VERSION ""

NS_ :

BS_:

BU_: SafetyRestraintSystem2 BrakeStrokeAlertMonitorTractor RearDoorStatusUnit SteeringColumnUnit BodyController ForwardRoadImageProcessor BrakesTrailer5 BrakesTrailer4 WeighingSystemDisplay Door6StatusUnit Door5StatusUnit Door4StatusUnit FuelTankMonitor PassengerCounterUnit3 PassengerCounterUnit2 IdleAdjustSystem EntryAssistControl2 EntryAssistControl1 EngineOilControlSystem InstrumentCluster2 IntersectionPreemptionEmitter SafetyRestraintSystem CommUnitCellular WeightingSystemAxleGroup6 WeightingSystemAxleGroup5 WeightingSystemAxleGroup4 WeightingSystemAxleGroup3 WeightingSystemAxleGroup2 WeightingSystemAxleGroup1 ParkingHeater TransmissiionShiftConsolePrimary DrivelineRetarder DriverInformationCenter2 Tachograph CollisionAvoidanceSystems Bridge_TrailerMounted Bridge_TractorMounted LightingControlAdministratorUnit SurveillanceMircrophone SilentAlarmUnit VehicleControlHeadTouchScreen MobileDataTerminal SmartCardTerminal BusChassisIdentificationUnit VehicleTurntable MaintenancePrinter BridgeFromDrivetrainLink BaseUnit VehicleProximityLeftSide VehicleProximityRightSide MobileDataTerminalUnit HighSpeedCommUnit VehicleStatusPointsMonitorUnit RouteAdherenceUnit EnvMonitorUnit ScheduleAdherenceUnit PassengerCounterUnit1 FareCollectionUnit AnnunciatorUnit MiddleDoorStatusUnit FrontDoorStatusUnit VehicleLocationUnit RefrigerantManagement VehicleHeadSigns VehicleLogicControlUnit VehicleControlHeadUnit TiresControlUnit PneumaticSystemController RearAxleSteeringController Engine3 OffBoardProgrammingStation CommUnitSatellite OffBoardDiagnostics2 DataLoggingComputer VehicleSensorsToDataConverter ParticulateTrapSystem TransmAddHybridCtrlModule Engine2 CrankingSystem EngineRetarder OffBoardDiagnostics1 DriverInformationCenter Electrical TiresTrailer3 TiresTrailer2 TiresTrailer1 TiresPowerUnit CommonUnitGround Multiplex VehicleSecurity VehicleNavigationUnit AerodynamicControlUnit ProximityDetectorRear ProximityDetectorFront ElectricalChargingSystem ParkBrakeController DiagSysTrailer2_obsolete DiagSysTrailer1 DiagSysPowerUnit SuspensionTrailer3_obsolete SuspensionTrailer2_obsolete SuspensionTrailer1 SuspensionPowerUnit CargoHeatingTrailer3_obsolete CargoHeatingTrailer2_obsolete CargoHeatingTrailer CabClimateControl RoadSpeedIndicator CruiseControl FuelSystem VehicleManagementSystem TripRecorder AxleTrailer2_obsolete BrakesTrailer3 BrakesTrailer2 BrakesTrailer1 BrakePowerUnit AxleTrailer3_obsolete AxleTrailer1 AxlePowerUnit PowerTakeoff InstrumentCluster Transmission TurboCharger Engine1
VAL_TABLE_ VtSitg_RqTempClutchDisengage 3 "NotAvailable" 2 "Error" 1 "ClutchDisengegementRequested" 0 "NoRequest" ;
VAL_TABLE_ VTSig_Lamp 3 "NotAvailable" 2 "Error" 1 "On" 0 "Off" ;
VAL_TABLE_ VTSig_Active 1 "Active" 0 "not Active" ;
VAL_TABLE_ VTSig_OnOff 3 "NotAvailable" 2 "Error" 1 "On" 0 "Off" ;

BO_ 510 Page2DataLinkEscape: 2 Vector__XXX
 SG_ VarLengthAndTypeData : 8|8@1+ (1,0) [0|255] "" Vector__XXX
 SG_ MID : 0|8@1+ (1,0) [0|255] "" Vector__XXX

BO_ 509 MilepostIdentification: 1 Vector__XXX
 SG_ VarNrASCIIChars : 0|8@1+ (1,0) [0|255] "ASCII" Vector__XXX

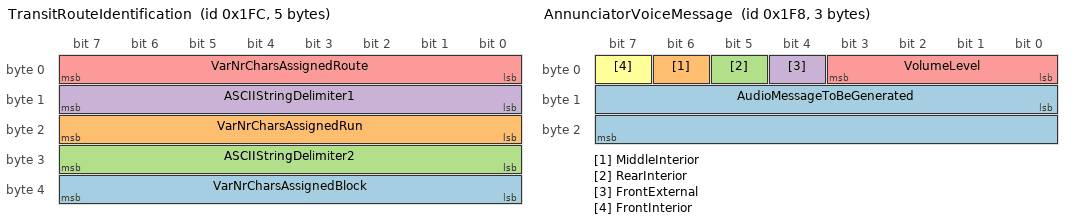
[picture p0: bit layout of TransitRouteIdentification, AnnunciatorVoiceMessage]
BO_ 508 TransitRouteIdentification: 5 Vector__XXX
 SG_ VarNrCharsAssignedBlock : 32|8@1+ (1,0) [0|255] "ASCII" Vector__XXX
 SG_ VarNrCharsAssignedRun : 16|8@1+ (1,0) [0|255] "ASCII" Vector__XXX
 SG_ ASCIIStringDelimiter2 : 24|8@1+ (1,0) [0|255] "ASCII" Vector__XXX
 SG_ ASCIIStringDelimiter1 : 8|8@1+ (1,0) [0|255] "ASCII" Vector__XXX
 SG_ VarNrCharsAssignedRoute : 0|8@1+ (1,0) [0|255] "ASCII" Vector__XXX

BO_ 507 DriverIdentification: 3 Vector__XXX
 SG_ VarNrCharsOtherDriverData : 16|8@1+ (1,0) [0|255] "ASCII" Vector__XXX
 SG_ ASCIIStringDelimiter1 : 8|8@1+ (1,0) [0|255] "ASCII" Vector__XXX
 SG_ VarNrCharsDriverId : 0|8@1+ (1,0) [0|255] "ASCII" Vector__XXX

BO_ 506 VehicleControlHeadDisplayMessage: 3 Vector__XXX
 SG_ VarNrASCIIChars : 16|8@1+ (1,0) [0|255] "ASCII" Vector__XXX
 SG_ SegmentPosForDisplayOfASCIIChars : 8|8@1+ (1,0) [0|255] "ASCII" Vector__XXX
 SG_ LinePosForDisplayOfASCIIChars : 0|8@1+ (1,0) [0|255] "ASCII" Vector__XXX

BO_ 505 VehicleCtrlHeadKeyboardMessage: 2 Vector__XXX
 SG_ IBMScanCode : 8|8@1+ (1,0) [0|255] "" Vector__XXX
 SG_ FunctionKeyDepression : 0|8@1+ (1,0) [0|255] "" Vector__XXX

BO_ 504 AnnunciatorVoiceMessage: 3 Vector__XXX
 SG_ AudioMessageToBeGenerated : 8|16@1+ (1,0) [0|65535] "" Vector__XXX
 SG_ MiddleInterior : 6|1@1+ (1,0) [0|1] "" Vector__XXX
 SG_ RearInterior : 5|1@1+ (1,0) [0|1] "" Vector__XXX
 SG_ FrontExternal : 4|1@1+ (1,0) [0|1] "" Vector__XXX
 SG_ VolumeLevel : 0|4@1+ (1,0) [0|15] "" Vector__XXX
 SG_ FrontInterior : 7|1@1+ (1,0) [0|1] "" Vector__XXX

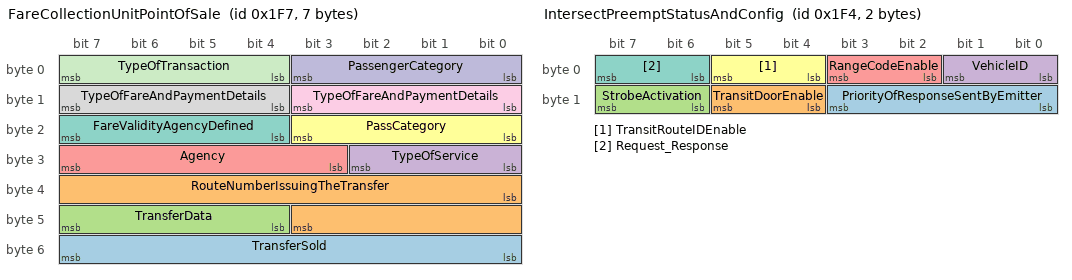
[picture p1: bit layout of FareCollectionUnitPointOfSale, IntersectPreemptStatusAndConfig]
BO_ 503 FareCollectionUnitPointOfSale: 7 Vector__XXX
 SG_ TransferSold : 48|8@1+ (1,0) [0|255] "" Vector__XXX
 SG_ RouteNumberIssuingTheTransfer : 32|12@1+ (1,0) [0|4095] "" Vector__XXX
 SG_ TransferData : 44|4@1+ (1,0) [0|15] "" Vector__XXX
 SG_ TypeOfService : 24|3@1+ (1,0) [0|7] "" Vector__XXX
 SG_ Agency : 27|5@1+ (1,0) [1|31] "" Vector__XXX
 SG_ PassCategory : 16|4@1+ (1,0) [0|15] "" Vector__XXX
 SG_ FareValidityAgencyDefined : 20|4@1+ (1,0) [0|15] "" Vector__XXX
 SG_ TypeOfFareAndPaymentDetails : 12|4@1+ (1,0) [0|15] "" Vector__XXX
 SG_ TypeOfFareAndPaymentDetails : 8|4@1+ (1,0) [0|15] "" Vector__XXX
 SG_ PassengerCategory : 0|4@1+ (1,0) [0|15] "" Vector__XXX
 SG_ TypeOfTransaction : 4|4@1+ (1,0) [0|15] "" Vector__XXX

BO_ 502 FareCollectionUnitServiceDetail: 14 Vector__XXX
 SG_ DriversSecurityCode : 96|16@1+ (1,0) [0|65535] "" Vector__XXX
 SG_ AssignedBlock : 80|16@1+ (1,0) [0|65535] "" Vector__XXX
 SG_ AssignedRun : 64|16@1+ (1,0) [0|65535] "" Vector__XXX
 SG_ AssignedRoute : 48|16@1+ (1,0) [0|65535] "" Vector__XXX
 SG_ PatternNumber : 32|16@1+ (1,0) [0|65535] "" Vector__XXX
 SG_ TripNumber : 16|16@1+ (1,0) [0|65535] "" Vector__XXX
 SG_ FarePresets : 8|8@1+ (1,0) [0|255] "" Vector__XXX
 SG_ TripStatus : 0|4@1+ (1,0) [0|15] "" Vector__XXX
 SG_ TripStatus : 4|3@1+ (1,0) [0|7] "" Vector__XXX
 SG_ FareboxStatus : 7|1@1+ (1,0) [0|1] "" Vector__XXX

BO_ 501 SignageMessage: 2 Vector__XXX
 SG_ DataCharacter1 : 8|8@1+ (1,0) [0|255] "" Vector__XXX
 SG_ RecordType : 0|8@1+ (1,0) [0|255] "ASCII" Vector__XXX

BO_ 500 IntersectPreemptStatusAndConfig: 2 Vector__XXX
 SG_ PriorityOfResponseSentByEmitter : 8|4@1+ (1,0) [0|15] "" Vector__XXX
 SG_ TransitDoorEnable : 12|2@1+ (1,0) [0|3] "" Vector__XXX
 SG_ StrobeActivation : 14|2@1+ (1,0) [0|3] "" Vector__XXX
 SG_ VehicleID : 0|2@1+ (1,0) [0|3] "" Vector__XXX
 SG_ RangeCodeEnable : 2|2@1+ (1,0) [0|3] "" Vector__XXX
 SG_ TransitRouteIDEnable : 4|2@1- (1,0) [0|3] "" Vector__XXX
 SG_ Request_Response : 6|2@1- (1,0) [0|3] "" Vector__XXX

BO_ 499 DriverInterfaceUnitDIUObjFormCmd: 5 Vector__XXX
 SG_ DataCharacter1 : 32|8@1+ (1,0) [0|255] "" Vector__XXX
 SG_ OID : 16|16@1+ (1,0) [0|65535] "" Vector__XXX
 SG_ FID : 8|8@1- (1,0) [0|255] "" Vector__XXX
 SG_ CommandType : 0|8@1+ (1,0) [0|255] "" Vector__XXX

BO_ 498 SendKeypressCommand: 3 Vector__XXX
 SG_ VarNrASCIIChars : 16|8@1+ (1,0) [0|255] "ASCII" Vector__XXX
 SG_ FID : 8|8@1- (1,0) [0|255] "" Vector__XXX
 SG_ MID : 0|8@1+ (1,0) [0|255] "" Vector__XXX

BO_ 450 BridgeFilterControl: 3 Vector__XXX
 SG_ TransmissionUpdatePeriod : 16|8@1+ (0.2,0) [0|51] "s" Vector__XXX
 SG_ PID : 8|8@1+ (1,0) [0|255] "" Vector__XXX
 SG_ MID : 0|8@1+ (1,0) [0|255] "" Vector__XXX

BO_ 449 ReportingIntervalRequest: 3 Vector__XXX
 SG_ TransmissionUpdatePeriod : 16|8@1+ (1,0) [0|255] "s" Vector__XXX
 SG_ PIDPage2 : 8|8@1+ (1,0) [0|255] "" Vector__XXX
 SG_ MID : 0|8@1+ (1,0) [0|255] "" Vector__XXX

BO_ 448 Page2MultisectionParameter: 3 Vector__XXX
 SG_ VarLengthDataSectionedParam : 24|8@1+ (1,0) [0|255] "" Vector__XXX
 SG_ ByteCountOrDataSectionedParam : 16|8@1+ (1,0) [0|255] "" Vector__XXX
 SG_ LastAndCurrentSectionNumber : 8|8@1+ (1,0) [0|255] "" Vector__XXX
 SG_ PIDPage2 : 0|8@1+ (1,0) [0|255] "" Vector__XXX

BO_ 447 PassengerCounter: 2 Vector__XXX
 SG_ PatronCount : 8|8@1+ (1,0) [0|255] "" Vector__XXX
 SG_ TypeOfPassengerCount : 0|8@1+ (1,0) [0|255] "" Vector__XXX

BO_ 446 CylHeadTemperatureBankB_Left: 2 Vector__XXX
 SG_ CylHeadTemperatureBankB_Left : 0|16@1- (0.25,0) [-8192|8191.75] "°F" Vector__XXX

BO_ 445 CylHeadTemperatureBankB_Right: 2 Vector__XXX
 SG_ CylHeadTemperatureBankB_Right : 0|16@1- (0.25,0) [-8192|8191.75] "°F" Vector__XXX

BO_ 444 Battery2Potential: 2 Vector__XXX
 SG_ Battery2Potential : 0|16@1+ (0.05,0) [0|3276.75] "V" Vector__XXX

BO_ 443 AuxiliaryGagePressureReading2: 2 Vector__XXX
 SG_ AuxiliaryGagePressureReading2 : 0|16@1+ (0.689,0) [0|45153.6] "kPa" Vector__XXX

BO_ 442 AuxiliaryTemperature2: 2 Vector__XXX
 SG_ AuxiliaryTemperature2 : 0|16@1- (0.1,0) [-3276.8|3276.7] "°F" Vector__XXX

BO_ 441 AuxiliaryTemperature1: 2 Vector__XXX
 SG_ AuxiliaryTemperature1 : 0|16@1- (0.1,0) [-3276.8|3276.7] "°F" Vector__XXX

BO_ 440 ExtendedRangeBoostPressure2: 2 Vector__XXX
 SG_ ExtendedRangeBoostPressure2 : 0|16@1+ (0.125,0) [0|8191.875] "kPa" Vector__XXX

BO_ 439 ExtendedRangeBoostPressure1: 2 Vector__XXX
 SG_ ExtendedRangeBoostPressure1 : 0|16@1+ (0.125,0) [0|8191.875] "kPa" Vector__XXX

BO_ 438 Trailer2Tag2PushChn2TirePressure: 2 Vector__XXX
 SG_ Trailer2Tag2PushChn2TirePressure : 0|16@1+ (0.689,0) [0|45153.6] "kPa" Vector__XXX

BO_ 437 Trail2Tag2PushChn2TirePrssreTarg: 2 Vector__XXX
 SG_ Trail2Tag2PushChn2TirePrssreTarg : 0|16@1+ (0.689,0) [0|45153.6] "kPa" Vector__XXX

BO_ 436 TripSuddenDecelerations: 2 Vector__XXX
 SG_ TripSuddenDecelerations : 0|16@1+ (1,0) [0|65535] "" Vector__XXX

BO_ 435 CargoAmbientTemperatreByLocation: 2 Vector__XXX
 SG_ CargoAmbientTemperature : 8|8@1- (1,0) [-127|128] "°F" Vector__XXX
 SG_ LocationOfTheAirTemperature : 0|2@1+ (1,0) [0|3] "" Vector__XXX

BO_ 434 ACVoltage: 2 Vector__XXX
 SG_ ACVoltage : 0|16@1+ (0.125,0) [0|8191.875] "V" Vector__XXX

BO_ 433 FuelShutoffSolenoidVoltage: 2 Vector__XXX
 SG_ FuelShutoffSolenoidVoltage : 0|16@1+ (0.05,0) [0|3276.75] "V" Vector__XXX

BO_ 432 StarterMotorVoltage: 2 Vector__XXX
 SG_ StarterMotorVoltage : 0|16@1+ (0.05,0) [0|3276.75] "V" Vector__XXX

BO_ 431 StarterNegativeCableVoltage: 2 Vector__XXX
 SG_ StarterNegativeCableVoltage : 0|16@1+ (0.0001,0) [0|6.5535] "V" Vector__XXX

BO_ 430 StarterSolenoidVoltage: 2 Vector__XXX
 SG_ StarterSolenoidVoltage : 0|16@1+ (0.05,0) [0|3276.75] "V" Vector__XXX

BO_ 429 StarterCurrentPeak: 2 Vector__XXX
 SG_ StarterCurrentPeak : 0|16@1+ (0.125,0) [0|8191.875] "A" Vector__XXX

BO_ 428 BatteryInternalResistance: 2 Vector__XXX
 SG_ BatteryInternalResistance : 0|16@1+ (0.25,0) [0|16383.75] "mOhm" Vector__XXX

BO_ 427 BatteryResistanceChange: 2 Vector__XXX
 SG_ BatteryResistanceChange : 0|16@1+ (0.25,0) [0|16383.75] "mOhm/s" Vector__XXX

BO_ 426 AlternatorGeneratorFieldVoltage: 2 Vector__XXX
 SG_ AlternatorGeneratorFieldVoltage : 0|16@1+ (0.05,0) [0|3276.75] "V" Vector__XXX

BO_ 425 AuxiliaryFrequency: 2 Vector__XXX
 SG_ AuxiliaryFrequency : 0|16@1+ (0.1,0) [0|6553.5] "Hz" Vector__XXX

BO_ 424 DCVoltage: 2 Vector__XXX
 SG_ DCVoltage : 0|16@1+ (0.05,0) [0|3276.75] "V" Vector__XXX

BO_ 423 ExtendedRangeNetBatteryCurrent: 2 Vector__XXX
 SG_ ExtendedRangeNetBatteryCurrent : 0|16@1- (0.125,0) [-4095.875|4096] "A" Vector__XXX

BO_ 422 AuxiliaryCurrent: 2 Vector__XXX
 SG_ AuxiliaryCurrent : 0|16@1- (0.125,0) [-4095.875|4096] "A" Vector__XXX

BO_ 421 AltrnatorGenratorNegCableVoltage: 2 Vector__XXX
 SG_ AltrnatorGenratorNegCableVoltage : 0|16@1+ (0.0001,0) [0|6.5535] "V" Vector__XXX

BO_ 420 StarterCurrentAverage: 2 Vector__XXX
 SG_ StarterCurrentAverage : 0|16@1+ (0.125,0) [0|8191.875] "A" Vector__XXX

BO_ 419 StarterCircuitResistance: 2 Vector__XXX
 SG_ StarterCircuitResistance : 0|16@1+ (0.25,0) [0|16383.75] "mOhm" Vector__XXX

BO_ 418 Transmission2OilTemperature: 2 Vector__XXX
 SG_ Transmission2OilTemperature : 0|16@1+ (0.25,0) [-8192|8191.75] "°F" Vector__XXX

BO_ 417 GrossVehicleWeight: 2 Vector__XXX
 SG_ GrossVehicleWeight : 0|16@1+ (17.792,0) [0|1166056.9] "N" Vector__XXX

BO_ 416 EvaporatorTemperature: 2 Vector__XXX
 SG_ EvaporatorTemperature : 0|16@1- (0.25,0) [-8192|8191.75] "°F" Vector__XXX

BO_ 415 AirCondRfrgerntHighSidePressure: 2 Vector__XXX
 SG_ AirCondRfrgerntHighSidePressure : 0|16@1- (1.379,0) [-45185|45184] "kPa" Vector__XXX

BO_ 414 AirCondRfrgerntLowSidePressure: 2 Vector__XXX
 SG_ AirCondRfrgerntLowSidePressure : 0|16@1- (1.379,0) [-45185|45184] "kPa" Vector__XXX

BO_ 413 NetVehicleWeightChange: 2 Vector__XXX
 SG_ NetVehicleWeightChange : 0|16@1- (17.792,0) [-583020.1|583037.3] "N" Vector__XXX

BO_ 412 RecircEngExhaustGasTemperature: 2 Vector__XXX
 SG_ RecircEngExhaustGasTemperature : 0|16@1- (0.25,0) [-8192|8191.75] "°F" Vector__XXX

BO_ 411 RecircEngExhaustGasDiffPressure: 2 Vector__XXX
 SG_ RecircEngExhaustGasDiffPressure : 0|16@1- (0.0078125,0) [-250|251.99] "kPa" Vector__XXX

BO_ 410 ExtRangeRoadSurfaceTemperature: 2 Vector__XXX
 SG_ ExtRangeRoadSurfaceTemperature : 0|16@1- (0.25,0) [-8192|8191.75] "°F" Vector__XXX

BO_ 409 AxleGroupWeight: 2 Vector__XXX
 SG_ AxleGroupWeight : 0|16@1+ (17.792,0) [0|1166056.9] "N" Vector__XXX

BO_ 408 AxleGroupEmptyWeightCalibration: 2 Vector__XXX
 SG_ AxleGroupEmptyWeightCalibration : 0|16@1+ (17.792,0) [0|1166056.9] "N" Vector__XXX

BO_ 407 AxleGroupFullWeightCalibration: 2 Vector__XXX
 SG_ AxleGroupFullWeightCalibration : 0|16@1+ (17.792,0) [0|1166056.9] "N" Vector__XXX

BO_ 406 HVACBlowerMotorSpeed: 2 Vector__XXX
 SG_ HVACBlowerMotorSpeed : 0|16@1+ (0.25,0) [0|16383.75] "rpm" Vector__XXX

BO_ 384 CompnentSpecificRequestParameter: 2 Vector__XXX
 SG_ IDFullParam : 0|8@1+ (1,0) [0|255] "" Vector__XXX
 SG_ MID : 8|8@1+ (1,0) [0|255] "" Vector__XXX

BO_ 383 VehicleAcceleration: 1 Vector__XXX
 SG_ VehicleAcceleration : 0|8@1- (0.322,0) [-41.216|40.894] "km/h/s" Vector__XXX

BO_ 382 TransitSilentAlarmStatus: 1 Vector__XXX
 SG_ SilentAlarmStatus : 0|2@1+ (1,0) [0|3] "" Vector__XXX

BO_ 381 VehicleUseStatus: 1 Vector__XXX
 SG_ TransitRunStatus : 8|2@1+ (1,0) [0|3] "" Vector__XXX
 SG_ VehicleUseStatus : 0|2@1+ (1,0) [0|3] "" Vector__XXX

BO_ 380 ArticulationAngle: 1 Vector__XXX
 SG_ ArticulationAngle : 0|8@1- (1,0) [-128|127] "°" Vector__XXX

BO_ 379 DoorStatus: 1 Vector__XXX
 SG_ TransitDoorStatus : 0|2@1+ (1,0) [0|3] "" Vector__XXX
 SG_ TrailerCargoDoorStatus : 2|2@1+ (1,0) [0|3] "" Vector__XXX

BO_ 378 FareCollectionUnitStatus: 1 Vector__XXX
 SG_ FareCollectionUnitStatus : 7|1@1+ (1,0) [0|1] "" Vector__XXX
 SG_ AlarmIdentifier : 0|7@1+ (1,0) [0|127] "" Vector__XXX

BO_ 377 CompressionUnbalance: 1 Vector__XXX
 SG_ CompressionUnbalance : 0|8@1+ (0.5,0) [0|127.5] "%" Vector__XXX

BO_ 376 FuelPumpInletVacuum: 1 Vector__XXX
 SG_ FuelPumpInletVacuum : 0|8@1+ (0.2,0) [0|51] "Hg" Vector__XXX

BO_ 375 FuelReturnPressure: 1 Vector__XXX
 SG_ FuelReturnPressure : 0|8@1+ (0.5,0) [0|127.5] "psi" Vector__XXX

BO_ 374 AlternatorACVoltage: 1 Vector__XXX
 SG_ AlternatorACVoltage : 0|8@1+ (0.125,0) [0|31.875] "V" Vector__XXX

BO_ 373 CenterRearDriveAxleTemperature: 1 Vector__XXX
 SG_ CenterRearDriveAxleTemperature : 0|8@1+ (1.2,0) [0|306] "°F" Vector__XXX

BO_ 372 RemoteAccelerator: 1 Vector__XXX
 SG_ RemoteAccelerator : 0|8@1+ (0.4,0) [0|102] "%" Vector__XXX

BO_ 371 TrailerPneumSupplyLinePressure: 1 Vector__XXX
 SG_ TrailerPneumSupplyLinePressure : 0|8@1+ (4.14,0) [0|1055] "kPa" Vector__XXX

BO_ 370 TrailrPneumBrkeCtrlLinePressure: 1 Vector__XXX
 SG_ TrailrPneumBrkeCtrlLinePressure : 0|8@1- (4.14,0) [0|1055] "kPa" Vector__XXX

BO_ 369 DistanceToRearObject_Reverse: 1 Vector__XXX
 SG_ DistanceToObjFromRearOfVehicle : 0|8@1+ (0.1,0) [0|25.5] "" Vector__XXX

BO_ 368 LaneDepartureIndication: 1 Vector__XXX
 SG_ RightSideIndicationStatus : 4|2@1+ (1,0) [0|3] "" Vector__XXX
 SG_ LeftSideIndicationStatus : 6|2@1+ (1,0) [0|3] "" Vector__XXX

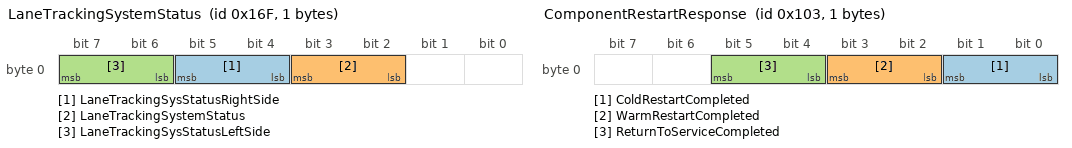
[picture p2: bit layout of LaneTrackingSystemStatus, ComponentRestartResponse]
BO_ 367 LaneTrackingSystemStatus: 1 Vector__XXX
 SG_ LaneTrackingSysStatusRightSide : 4|2@1+ (1,0) [0|3] "" Vector__XXX
 SG_ LaneTrackingSystemStatus : 2|2@1- (1,0) [0|3] "" Vector__XXX
 SG_ LaneTrackingSysStatusLeftSide : 6|2@1+ (1,0) [0|3] "" Vector__XXX

BO_ 366 EngineOilLevelHigh_Low: 1 Vector__XXX
 SG_ EngineOilLevelHigh_Low : 0|8@1- (0.473,0) [-60.544|60.071] "L" Vector__XXX

BO_ 365 WeighingSystemStatusCommand: 1 Vector__XXX
 SG_ WeighingSystemStatus2 : 0|2@1+ (1,0) [0|3] "" Vector__XXX
 SG_ WeighingSystemStatus1 : 2|2@1+ (1,0) [0|3] "" Vector__XXX

BO_ 364 HVACUnitDischargeTemperature: 1 Vector__XXX
 SG_ HVACUnitDischargeTemperature : 0|8@1- (2.5,0) [-320|317.5] "°F" Vector__XXX

BO_ 363 HydraulicRetarderCtrlAirPressure: 1 Vector__XXX
 SG_ HydraulicRetarderCtrlAirPressure : 0|8@1+ (4.14,0) [0|1055] "kPa" Vector__XXX

BO_ 362 PercentExhaustGasRecircValve2Pos: 1 Vector__XXX
 SG_ PercentExhaustGasRecircValve2Pos : 0|8@1+ (0.5,0) [0|127.5] "%" Vector__XXX

BO_ 259 ComponentRestartResponse: 1 Vector__XXX
 SG_ ColdRestartCompleted : 0|2@1+ (1,0) [0|3] "" Vector__XXX
 SG_ WarmRestartCompleted : 2|2@1+ (1,0) [0|3] "" Vector__XXX
 SG_ ReturnToServiceCompleted : 4|2@1+ (1,0) [0|3] "" Vector__XXX

BO_ 258 WarmRestartOfSpecificComponent: 1 Vector__XXX
 SG_ MID : 0|8@1+ (1,0) [0|255] "" Vector__XXX

BO_ 257 ColdRestartOfSpecificComponent: 1 Vector__XXX
 SG_ MID : 0|8@1+ (1,0) [0|255] "" Vector__XXX

BO_ 254 DataLinkEscape: 2 Vector__XXX

BO_ 253 ElapsedTime: 1 Vector__XXX
 SG_ Seconds : 0|8@1+ (0.25,0) [0|63.75] "s" Vector__XXX

BO_ 252 Date: 3 Vector__XXX
 SG_ Year : 16|8@1+ (1,0) [0|255] "y" Vector__XXX
 SG_ Month : 8|8@1+ (1,0) [0|255] "months" Vector__XXX
 SG_ Day : 0|8@1+ (0.25,0) [0|63.75] "d" Vector__XXX

BO_ 251 Clock: 3 Vector__XXX
 SG_ Hours : 16|8@1+ (1,0) [0|255] "h" Vector__XXX
 SG_ Minutes : 8|8@1+ (1,0) [0|255] "min" Vector__XXX
 SG_ Seconds : 0|8@1+ (0.25,0) [0|63.75] "s" Vector__XXX

BO_ 250 TotalFuelUsed2: 4 Vector__XXX
 SG_ TotalFuelUsed : 0|32@1+ (0.473,0) [0|2032277476] "L" Vector__XXX

BO_ 247 TotalEngineHours: 4 Vector__XXX
 SG_ TotalEngineHours : 0|32@1+ (0.05,0) [0|214748364.75] "h" Vector__XXX

BO_ 249 TotalEngineRevolutions: 4 Vector__XXX
 SG_ TotalEngineRevolutions : 0|32@1+ (1000,0) [0|4294967295000] "r" Vector__XXX

BO_ 248 TotalPTOHours: 4 Vector__XXX
 SG_ TotalPTOHours : 0|32@1+ (0.05,0) [0|214748364.75] "h" Vector__XXX

BO_ 246 TotalVehicleHours: 4 Vector__XXX
 SG_ TotalVehicleHours : 0|32@1+ (0.05,0) [0|214748364.75] "h" Vector__XXX

BO_ 245 TotalVehicleDistance: 4 Vector__XXX
 SG_ TotalVehicleDistance : 0|32@1+ (0.161,0) [0|691207984.6] "km" Vector__XXX

BO_ 244 TripDistance: 4 Vector__XXX
 SG_ TripDistance : 0|32@1+ (0.16,0) [0|687194767.2] "km" Vector__XXX

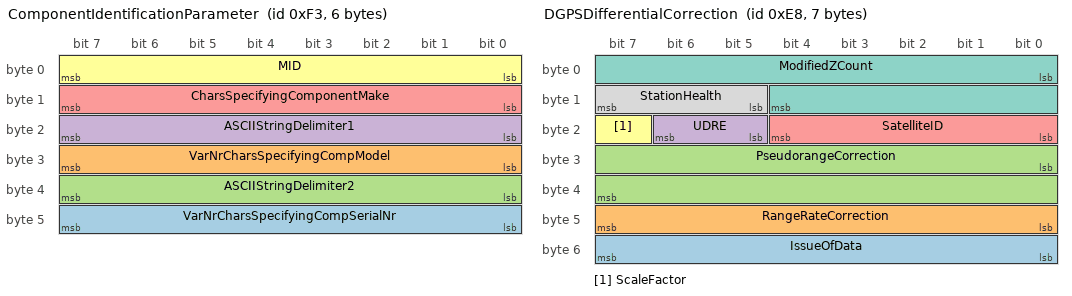
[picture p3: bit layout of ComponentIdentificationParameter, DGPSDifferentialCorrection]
BO_ 243 ComponentIdentificationParameter: 6 Vector__XXX
 SG_ VarNrCharsSpecifyingCompSerialNr : 40|8@1+ (1,0) [0|255] "ASCII" Vector__XXX
 SG_ VarNrCharsSpecifyingCompModel : 24|8@1+ (1,0) [0|255] "ASCII" Vector__XXX
 SG_ ASCIIStringDelimiter2 : 32|8@1+ (1,0) [0|255] "ASCII" Vector__XXX
 SG_ ASCIIStringDelimiter1 : 16|8@1+ (1,0) [0|255] "ASCII" Vector__XXX
 SG_ CharsSpecifyingComponentMake : 8|8@1+ (1,0) [0|255] "ASCII" Vector__XXX
 SG_ MID : 0|8@1+ (1,0) [0|255] "" Vector__XXX

BO_ 242 TireTemperatureByPosition: 3 Vector__XXX
 SG_ TirePosition : 8|8@1+ (1,0) [0|255] "" Vector__XXX
 SG_ MID : 0|8@1+ (1,0) [0|255] "" Vector__XXX
 SG_ TireTemperature : 16|8@1+ (2.5,0) [0|637.5] "°F" Vector__XXX

BO_ 241 TirePressureByPosition: 3 Vector__XXX
 SG_ TirePressure : 16|8@1+ (4.14,0) [0|1055.7] "kPa" Vector__XXX
 SG_ TirePosition : 8|8@1+ (1,0) [0|255] "" Vector__XXX
 SG_ MID : 0|8@1+ (1,0) [0|255] "" Vector__XXX

BO_ 240 ChangeReferenceNumber: 1 Vector__XXX
 SG_ VarLengthAndTypeChangeRefNr : 0|8@1+ (1,0) [0|255] "" Vector__XXX

BO_ 239 Position: 10 Vector__XXX
 SG_ Altitude : 64|16@1- (0.15,2418.2) [-2497|4993.7] "m" Vector__XXX
 SG_ Longitude : 32|32@1- (1E-006,0) [-2147.483648|2147.483647] "°" Vector__XXX
 SG_ Latitude : 0|32@1- (1E-006,0) [-2147.483648|2147.483647] "°" Vector__XXX

BO_ 238 VelocityVector: 5 Vector__XXX
 SG_ Pitch : 24|16@1- (0.01,0) [-327.68|327.67] "°" Vector__XXX
 SG_ PresentVehicleHeading : 8|16@1+ (0.01,0) [0|655.35] "°" Vector__XXX
 SG_ CalculatedVehicleSpeed : 0|8@1+ (0.805,-24) [-24|180.8] "km/h" Vector__XXX

BO_ 237 VehicleIdentificationNumberVIN: 1 Vector__XXX
 SG_ VarNrASCIIChars : 0|8@1+ (1,0) [0|255] "ASCII" Vector__XXX

BO_ 236 TotalIdleFuelUsed2: 4 Vector__XXX
 SG_ TotalIdleFuelUsed : 0|32@1+ (0.473,0) [0|2031519530.5] "L" Vector__XXX

BO_ 235 TotalIdleHours: 4 Vector__XXX
 SG_ TotalIdleHours : 0|32@1+ (0.05,0) [0|214748364.75] "h" Vector__XXX

BO_ 234 SoftwareIdentification: 1 Vector__XXX
 SG_ VarLengthSoftwareIdField : 0|8@1+ (1,0) [0|255] "ASCII" Vector__XXX

BO_ 233 UnitNumberPowerUnit: 1 Vector__XXX
 SG_ VarNrASCIIChars : 0|8@1+ (1,0) [0|255] "ASCII" Vector__XXX

BO_ 232 DGPSDifferentialCorrection: 7 Vector__XXX
 SG_ IssueOfData : 48|8@1+ (1,0) [0|255] "" Vector__XXX
 SG_ RangeRateCorrection : 40|8@1- (0.002,0) [-0.256|0.254] "m/s" Vector__XXX
 SG_ PseudorangeCorrection : 24|16@1- (0.02,0) [-655.36|655.34] "m" Vector__XXX
 SG_ UDRE : 21|2@1+ (1,0) [0|3] "" Vector__XXX
 SG_ SatelliteID : 16|5@1+ (1,0) [0|31] "" Vector__XXX
 SG_ ScaleFactor : 23|1@1+ (1,0) [0|1] "" Vector__XXX
 SG_ ModifiedZCount : 0|13@1+ (0.6,0) [0|4914.6] "s" Vector__XXX
 SG_ StationHealth : 13|3@1- (1,0) [0|7] "" Vector__XXX

BO_ 231 TripFuel2: 4 Vector__XXX
 SG_ TripFuel : 0|32@1+ (0.5,0) [0|2147483647.5] "kg" Vector__XXX

BO_ 230 TotalIdleFuelUsed: 4 Vector__XXX
 SG_ TotalIdleFuelUsed : 0|32@1+ (0.5,0) [0|2147483647.5] "kg" Vector__XXX

BO_ 229 TotalFuelUsed: 4 Vector__XXX
 SG_ TotalFuelUsed : 0|32@1+ (0.5,0) [0|2147483647.5] "kg" Vector__XXX

BO_ 228 SpeedSensorCalibration: 4 Vector__XXX
 SG_ SpeedSensorCalibration : 0|32@1+ (0.621,0) [0|2667174690.2] "pulses/km" Vector__XXX

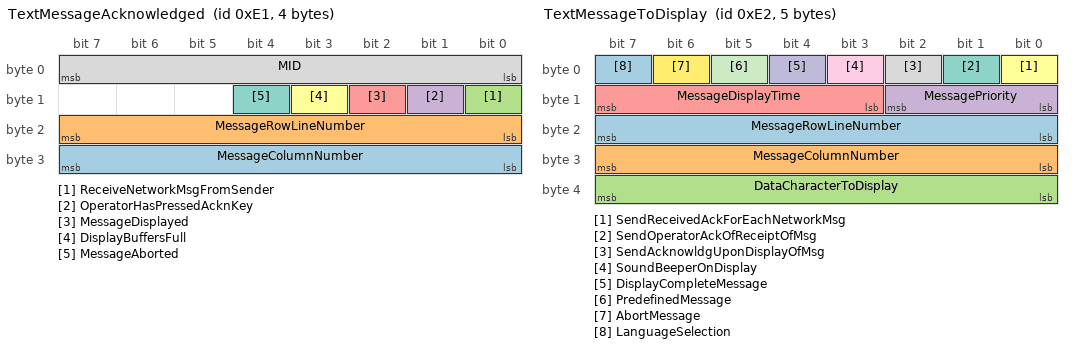
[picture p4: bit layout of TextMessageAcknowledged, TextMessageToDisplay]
BO_ 225 TextMessageAcknowledged: 4 Vector__XXX
 SG_ MessageColumnNumber : 24|8@1+ (1,0) [0|255] "" Vector__XXX
 SG_ MessageRowLineNumber : 16|8@1+ (1,0) [0|255] "" Vector__XXX
 SG_ ReceiveNetworkMsgFromSender : 8|1@1+ (1,0) [0|1] "" Vector__XXX
 SG_ OperatorHasPressedAcknKey : 9|1@1+ (1,0) [0|1] "" Vector__XXX
 SG_ MessageDisplayed : 10|1@1+ (1,0) [0|1] "" Vector__XXX
 SG_ DisplayBuffersFull : 11|1@1+ (1,0) [0|1] "" Vector__XXX
 SG_ MessageAborted : 12|1@1+ (1,0) [0|2] "" Vector__XXX
 SG_ MID : 0|8@1+ (1,0) [0|255] "" Vector__XXX

BO_ 226 TextMessageToDisplay: 5 Vector__XXX
 SG_ MessageRowLineNumber : 16|8@1+ (1,0) [0|255] "" Vector__XXX
 SG_ MessageColumnNumber : 24|8@1+ (1,0) [0|255] "" Vector__XXX
 SG_ DataCharacterToDisplay : 32|8@1+ (1,0) [0|255] "ASCII" Vector__XXX
 SG_ MessagePriority : 8|3@1+ (1,0) [0|7] "" Vector__XXX
 SG_ MessageDisplayTime : 11|5@1- (1,0) [0|31] "" Vector__XXX
 SG_ SendReceivedAckForEachNetworkMsg : 0|1@1+ (1,0) [0|1] "" Vector__XXX
 SG_ SendOperatorAckOfReceiptOfMsg : 1|1@1- (1,0) [0|1] "" Vector__XXX
 SG_ SendAcknowldgUponDisplayOfMsg : 2|1@1+ (1,0) [0|1] "" Vector__XXX
 SG_ SoundBeeperOnDisplay : 3|1@1+ (1,0) [0|1] "" Vector__XXX
 SG_ DisplayCompleteMessage : 4|1@1+ (1,0) [0|1] "" Vector__XXX
 SG_ PredefinedMessage : 5|1@1+ (1,0) [0|1] "" Vector__XXX
 SG_ AbortMessage : 6|1@1+ (1,0) [0|1] "" Vector__XXX
 SG_ LanguageSelection : 7|1@1+ (1,0) [0|1] "" Vector__XXX

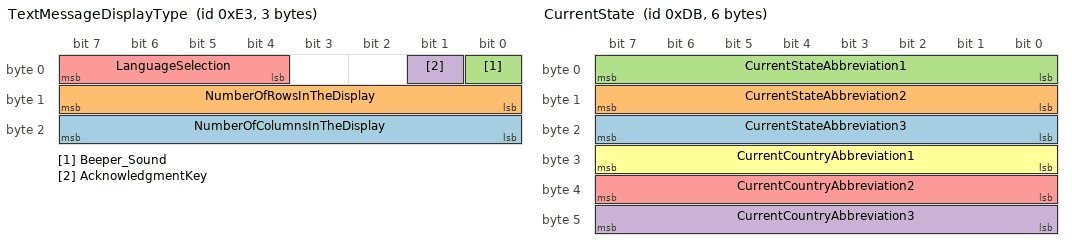
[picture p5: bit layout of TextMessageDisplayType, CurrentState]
BO_ 227 TextMessageDisplayType: 3 Vector__XXX
 SG_ NumberOfColumnsInTheDisplay : 16|8@1+ (1,0) [0|255] "" Vector__XXX
 SG_ NumberOfRowsInTheDisplay : 8|8@1+ (1,0) [0|255] "" Vector__XXX
 SG_ Beeper_Sound : 0|1@1+ (1,0) [0|1] "" Vector__XXX
 SG_ AcknowledgmentKey : 1|1@1+ (1,0) [0|1] "" Vector__XXX
 SG_ LanguageSelection : 4|4@1+ (1,0) [0|15] "" Vector__XXX

BO_ 224 ImmobilizerSecurityCode: 1 Vector__XXX
 SG_ VarLengthAndTypeImmobSecurtyCode : 0|8@1+ (1,0) [0|255] "" Vector__XXX

BO_ 223 AuxiliaryA_DCounts: 2 Vector__XXX
 SG_ A_DCountsForChannel1 : 0|16@1+ (1,0) [0|65535] "" Vector__XXX

BO_ 222 AntiTheftStatusReport: 9 Vector__XXX
 SG_ EncryptionSeedPresent : 8|2@1+ (1,0) [0|3] "" Vector__XXX
 SG_ RandomNumber : 16|56@1+ (1,0) [0|7.2057594038E+016] "" Vector__XXX
 SG_ PasswordValid : 10|2@1+ (1,0) [0|3] "" Vector__XXX
 SG_ ComponentStatus : 12|2@1- (1,0) [0|3] "" Vector__XXX
 SG_ StatusOfRequest : 14|2@1+ (1,0) [0|3] "" Vector__XXX
 SG_ MID : 0|8@1+ (1,0) [0|255] "" Vector__XXX

BO_ 221 AntiTheftRequest: 9 Vector__XXX
 SG_ PasswordRepresentation : 16|56@1+ (1,0) [0|7.2057594038E+016] "" Vector__XXX
 SG_ EncryptionIndicatorStates : 9|2@1- (1,0) [0|3] "" Vector__XXX
 SG_ DesiredExitMode : 11|2@1+ (1,0) [0|3] "" Vector__XXX
 SG_ CommandStates : 13|3@1+ (1,0) [0|7] "" Vector__XXX
 SG_ MID : 0|8@1+ (1,0) [0|255] "" Vector__XXX

BO_ 220 EngineTorqueHistory: 33 Vector__XXX
 SG_ EngineTorqueLimit6AxleInput : 248|16@1+ (2,0) [0|100000] "Nm" Vector__XXX
 SG_ EngineTorqueLimit5Switch : 232|16@1+ (1,0) [0|65535] "Nm" Vector__XXX
 SG_ EngineTorqueLimit3Transmission : 200|16@1+ (1,0) [0|65535] "Nm" Vector__XXX
 SG_ EngineTorqueLimit4Transmission : 216|16@1+ (1,0) [0|65535] "Nm" Vector__XXX
 SG_ TransmissionGearRatio3 : 184|16@1+ (0.01,0) [0|655] "ratio" Vector__XXX
 SG_ EngineTorqueLimit2Transmission : 168|16@1+ (1,0) [0|65535] "Nm" Vector__XXX
 SG_ TransmissionGearRatio2 : 152|16@1+ (0.01,0) [0|655] "ratio" Vector__XXX
 SG_ EngineTorqueLimit1Transmission : 136|16@1+ (1,0) [0|65535] "Nm" Vector__XXX
 SG_ TransmissionGearRatio1 : 120|16@1+ (0.01,0) [0|655] "ratio" Vector__XXX
 SG_ TorqueLimitingFeatureStatus : 112|2@1+ (1,0) [0|3] "" Vector__XXX
 SG_ TorqueLimitingFeature : 114|3@1+ (1,0) [0|7] "" Vector__XXX
 SG_ CalibrationRecordDurationTime : 80|32@1+ (0.05,0) [0|214748364.75] "h" Vector__XXX
 SG_ CalibrationRecordStartYear : 72|8@1+ (1,0) [0|255] "y" Vector__XXX
 SG_ CalibrationRecordStartDay : 64|8@1+ (0.25,0) [0.25|31.75] "d" Vector__XXX
 SG_ CalibrationRecordStartMonth : 56|8@1+ (1,0) [0|12] "month" Vector__XXX
 SG_ PeakEngineTorque2 : 40|16@1+ (1,0) [0|65535] "Nm" Vector__XXX
 SG_ PeakEngineTorque1 : 24|16@1+ (1,0) [0|65535] "Nm" Vector__XXX
 SG_ EnginePower : 8|16@1+ (0.5,0) [0|32767.5] "kW" Vector__XXX
 SG_ NumberOfCalibrationRecords : 0|8@1+ (1,0) [0|255] "" Vector__XXX

BO_ 219 CurrentState: 6 Vector__XXX
 SG_ CurrentStateAbbreviation3 : 16|8@1+ (1,0) [0|255] "ASCII" Vector__XXX
 SG_ CurrentStateAbbreviation2 : 8|8@1+ (1,0) [0|255] "ASCII" Vector__XXX
 SG_ CurrentStateAbbreviation1 : 0|8@1+ (1,0) [0|255] "ASCII" Vector__XXX
 SG_ CurrentCountryAbbreviation3 : 40|8@1+ (1,0) [0|255] "ASCII" Vector__XXX
 SG_ CurrentCountryAbbreviation2 : 32|8@1+ (1,0) [0|255] "ASCII" Vector__XXX
 SG_ CurrentCountryAbbreviation1 : 24|8@1+ (1,0) [0|255] "ASCII" Vector__XXX

BO_ 218 StateLineCrossing: 17 Vector__XXX
 SG_ OldStateAbbreviation3 : 56|8@1+ (1,0) [0|255] "ASCII" Vector__XXX
 SG_ OldStateAbbreviation2 : 48|8@1+ (1,0) [0|255] "ASCII" Vector__XXX
 SG_ OldStateAbbreviation1 : 40|8@1+ (1,0) [0|255] "ASCII" Vector__XXX
 SG_ OldCountryAbbreviation3 : 80|8@1+ (1,0) [0|255] "ASCII" Vector__XXX
 SG_ OldCountryAbbreviation2 : 72|8@1+ (1,0) [0|255] "ASCII" Vector__XXX
 SG_ OldCountryAbbreviation1 : 64|8@1+ (1,0) [0|255] "ASCII" Vector__XXX
 SG_ NewStateAbbreviation3 : 104|8@1+ (1,0) [0|255] "ASCII" Vector__XXX
 SG_ NewStateAbbreviation2 : 96|8@1+ (1,0) [0|255] "ASCII" Vector__XXX
 SG_ NewStateAbbreviation1 : 88|8@1+ (1,0) [0|255] "ASCII" Vector__XXX
 SG_ NewCountryAbbreviation3 : 128|8@1+ (1,0) [0|255] "ASCII" Vector__XXX
 SG_ NewCountryAbbreviation2 : 120|8@1+ (1,0) [0|255] "ASCII" Vector__XXX
 SG_ NewCountryAbbreviation1 : 112|8@1+ (1,0) [0|255] "ASCII" Vector__XXX
 SG_ Hours : 32|8@1+ (1,0) [0|255] "h" Vector__XXX
 SG_ Minutes : 24|8@1+ (1,0) [0|255] "min" Vector__XXX
 SG_ Year : 16|8@1+ (1,0) [0|255] "y" Vector__XXX
 SG_ Month : 8|8@1+ (1,0) [0|255] "months" Vector__XXX
 SG_ Day : 0|8@1+ (0.25,0) [0|63.75] "d" Vector__XXX

BO_ 216 FuelTankNozzleIdentification: 11 Vector__XXX
 SG_ NozzleIdentification9 : 72|8@1+ (1,0) [0|255] "ASCII" Vector__XXX
 SG_ NozzleIdentification8 : 64|8@1+ (1,0) [0|255] "ASCII" Vector__XXX
 SG_ NozzleIdentification7 : 56|8@1+ (1,0) [0|255] "ASCII" Vector__XXX
 SG_ NozzleIdentification6 : 48|8@1+ (1,0) [0|255] "ASCII" Vector__XXX
 SG_ NozzleIdentification5 : 40|8@1+ (1,0) [0|255] "ASCII" Vector__XXX
 SG_ NozzleIdentification4 : 32|8@1+ (1,0) [0|255] "ASCII" Vector__XXX
 SG_ NozzleIdentification3 : 24|8@1+ (1,0) [0|255] "ASCII" Vector__XXX
 SG_ NozzleIdentification2 : 16|8@1+ (1,0) [0|255] "ASCII" Vector__XXX
 SG_ NozzleIdentification10 : 80|8@1+ (1,0) [0|255] "ASCII" Vector__XXX
 SG_ TankAntennaStatus : 6|2@1+ (1,0) [0|3] "" Vector__XXX
 SG_ TankIdentification : 0|4@1- (1,0) [0|15] "" Vector__XXX
 SG_ NozzleIdentification1 : 8|8@1+ (1,0) [0|255] "ASCII" Vector__XXX

BO_ 215 BrakeTemperature: 3 Vector__XXX
 SG_ BrakeTemperature : 16|8@1+ (5,0) [0|1275] "°F" Vector__XXX
 SG_ WheelPosition : 8|8@1+ (1,0) [0|255] "" Vector__XXX
 SG_ TrailerOrPowerUnitMID : 0|8@1+ (1,0) [0|255] "" Vector__XXX

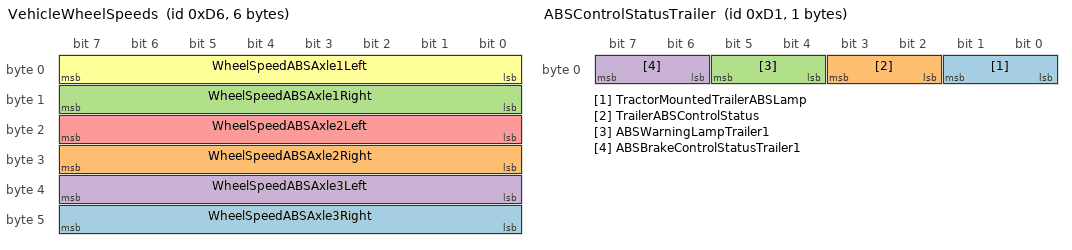
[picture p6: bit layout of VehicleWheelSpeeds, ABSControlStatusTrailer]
BO_ 214 VehicleWheelSpeeds: 6 Vector__XXX
 SG_ WheelSpeedABSAxle3Right : 40|8@1+ (0.805,0) [0|205.2] "km/h" Vector__XXX
 SG_ WheelSpeedABSAxle2Right : 24|8@1+ (0.805,0) [0|205.2] "km/h" Vector__XXX
 SG_ WheelSpeedABSAxle1Right : 8|8@1+ (0.805,0) [0|205.2] "km/h" Vector__XXX
 SG_ WheelSpeedABSAxle3Left : 32|8@1+ (0.805,0) [0|205.2] "km/h" Vector__XXX
 SG_ WheelSpeedABSAxle2Left : 16|8@1+ (0.805,0) [0|205.2] "km/h" Vector__XXX
 SG_ WheelSpeedABSAxle1Left : 0|8@1+ (0.805,0) [0|205.275] "km/h" Vector__XXX

BO_ 213 WheelEndAssemblyVibrationLevel: 3 Vector__XXX
 SG_ WheelEndAssemblyVibrationLevel : 0|8@1- (1,0) [0|255] "g" Vector__XXX

BO_ 212 TirePressureTargetBySeqNumber: 1 Vector__XXX
 SG_ VarLengthTirePressureTrgtBySeqNr : 0|8@1+ (4.14,0) [0|1035] "kPa" Vector__XXX

BO_ 211 TirePressureBySequenceNumber: 1 Vector__XXX
 SG_ VarLengthTirePressureBySquenceNr : 0|8@1+ (4.14,0) [0|1035] "kPa" Vector__XXX

BO_ 210 TireTemperatureBySequenceNumber: 1 Vector__XXX
 SG_ VarLengthTireTempBySequenceNr : 0|8@1+ (2.5,0) [0|625] "°F" Vector__XXX

BO_ 209 ABSControlStatusTrailer: 1 Vector__XXX
 SG_ TractorMountedTrailerABSLamp : 0|2@1+ (1,0) [0|3] "" Vector__XXX
 SG_ TrailerABSControlStatus : 2|2@1+ (1,0) [0|3] "" Vector__XXX
 SG_ ABSWarningLampTrailer1 : 4|2@1+ (1,0) [0|3] "" Vector__XXX
 SG_ ABSBrakeControlStatusTrailer1 : 6|2@1+ (1,0) [0|3] "" Vector__XXX

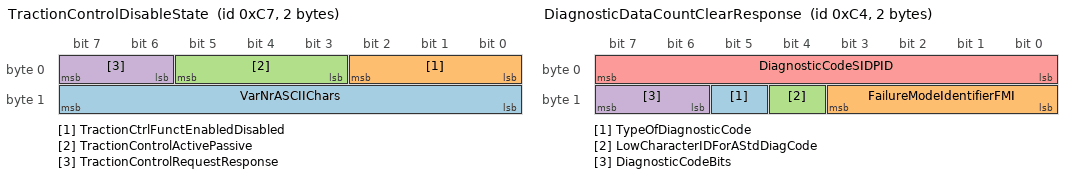
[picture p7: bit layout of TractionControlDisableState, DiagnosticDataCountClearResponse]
BO_ 199 TractionControlDisableState: 2 Vector__XXX
 SG_ VarNrASCIIChars : 8|8@1+ (1,0) [0|255] "ASCII" Vector__XXX
 SG_ TractionCtrlFunctEnabledDisabled : 0|3@1+ (1,0) [0|7] "" Vector__XXX
 SG_ TractionControlActivePassive : 3|3@1+ (1,0) [0|7] "" Vector__XXX
 SG_ TractionControlRequestResponse : 6|2@1+ (1,0) [0|3] "" Vector__XXX

BO_ 196 DiagnosticDataCountClearResponse: 2 Vector__XXX
 SG_ TypeOfDiagnosticCode : 13|1@1+ (1,0) [0|1] "" Vector__XXX
 SG_ FailureModeIdentifierFMI : 8|4@1+ (1,0) [0|15] "" Vector__XXX
 SG_ LowCharacterIDForAStdDiagCode : 12|1@1+ (1,0) [0|1] "" Vector__XXX
 SG_ DiagnosticCodeBits : 14|2@1+ (1,0) [0|3] "" Vector__XXX
 SG_ DiagnosticCodeSIDPID : 0|8@1+ (1,0) [0|255] "" Vector__XXX

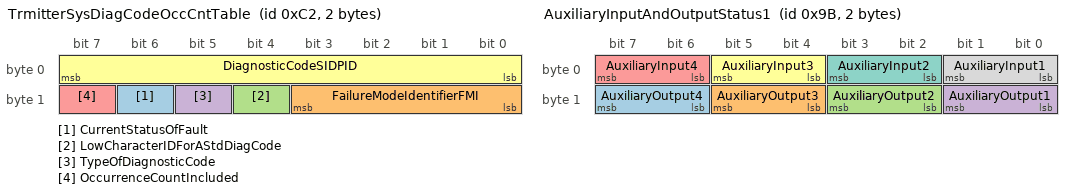
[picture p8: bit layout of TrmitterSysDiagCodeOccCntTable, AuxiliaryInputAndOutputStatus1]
BO_ 194 TrmitterSysDiagCodeOccCntTable: 2 Vector__XXX
 SG_ CurrentStatusOfFault : 14|1@1+ (1,0) [0|1] "" Vector__XXX
 SG_ FailureModeIdentifierFMI : 8|4@1- (1,0) [0|15] "" Vector__XXX
 SG_ LowCharacterIDForAStdDiagCode : 12|1@1+ (1,0) [0|1] "" Vector__XXX
 SG_ TypeOfDiagnosticCode : 13|1@1+ (1,0) [0|1] "" Vector__XXX
 SG_ OccurrenceCountIncluded : 15|1@1+ (1,0) [0|1] "" Vector__XXX
 SG_ DiagnosticCodeSIDPID : 0|8@1+ (1,0) [0|255] "" Vector__XXX

BO_ 192 MultisectionParameter: 4 Vector__XXX
 SG_ VarLengthDataSectionedParam : 24|8@1+ (1,0) [0|255] "" Vector__XXX
 SG_ ByteCountOrDataSectionedParam : 16|8@1+ (1,0) [0|255] "" Vector__XXX
 SG_ LastAndCurrentSectionNumber : 8|8@1+ (1,0) [0|255] "" Vector__XXX
 SG_ PIDPage1 : 0|8@1+ (1,0) [0|255] "" Vector__XXX

BO_ 191 TransmissionOutputShaftSpeed: 2 Vector__XXX
 SG_ TransmissionOutputShaftSpeed : 0|16@1+ (0.25,0) [0|16383.75] "rpm" Vector__XXX

BO_ 189 RatedEngineSpeed: 2 Vector__XXX
 SG_ RatedEngineSpeed : 0|16@1+ (0.25,0) [0|16383.75] "rpm" Vector__XXX

BO_ 188 IdleEngineSpeed: 2 Vector__XXX
 SG_ IdleEngineSpeed : 0|16@1+ (0.25,0) [0|16383.75] "rpm" Vector__XXX

BO_ 187 PowerTakeoffSetSpeed: 2 Vector__XXX
 SG_ PowerTakeoffSetSpeed : 0|16@1+ (0.25,0) [0|16383.75] "rpm" Vector__XXX

BO_ 186 PowerTakeoffSpeed: 2 Vector__XXX
 SG_ PowerTakeoffSpeed : 0|16@1+ (0.25,0) [0|16383.75] "rpm" Vector__XXX

BO_ 185 AverageFuelEconomy2: 2 Vector__XXX
 SG_ AverageFuelEconomy2 : 0|16@1+ (0.00166072,0) [0|108.835] "km/L" Vector__XXX

BO_ 184 InstantaneousFuelEconomy2: 2 Vector__XXX
 SG_ InstantaneousFuelEconomy2 : 0|16@1+ (0.00166072,0) [0|108.835] "km/L" Vector__XXX

BO_ 183 FuelRateInstantaneous: 2 Vector__XXX
 SG_ FuelRateInstantaneous : 0|16@1+ (1.6428E-005,0) [0|1.07665] "L/s" Vector__XXX

BO_ 182 TripFuel: 2 Vector__XXX
 SG_ TripFuel : 0|16@1+ (0.473,0) [0|31009.6] "L" Vector__XXX

BO_ 181 CargoWeight: 2 Vector__XXX
 SG_ CargoWeight : 0|16@1+ (17.792,0) [0|1166056.9] "N" Vector__XXX

BO_ 180 TrailerWeight: 2 Vector__XXX
 SG_ TrailerWeight : 0|16@1+ (17.792,0) [0|1166056.9] "N" Vector__XXX

BO_ 179 RearAxleWeight: 2 Vector__XXX
 SG_ RearAxleWeight : 0|16@1+ (4.448,0) [0|291514.2] "N" Vector__XXX

BO_ 178 FrontAxleWeight: 2 Vector__XXX
 SG_ FrontAxleWeight : 0|16@1+ (4.448,0) [0|291514.2] "N" Vector__XXX

BO_ 177 Transmission1OilTemperature: 2 Vector__XXX
 SG_ Transmission1OilTemperature : 0|16@1- (0.25,0) [-8192|8191.75] "°F" Vector__XXX

BO_ 176 TurboOilTemperature: 2 Vector__XXX
 SG_ TurboOilTemperature : 0|16@1- (0.25,0) [-8192|8191.75] "°F" Vector__XXX

BO_ 175 EngineOilTemperature: 2 Vector__XXX
 SG_ EngineOilTemperature : 0|16@1- (0.25,0) [-8192|8191.75] "°F" Vector__XXX

BO_ 174 FuelTemperature: 2 Vector__XXX
 SG_ FuelTemperature : 0|16@1- (0.25,0) [-8192|8191.75] "°F" Vector__XXX

BO_ 173 ExhaustGasTemperature: 2 Vector__XXX
 SG_ ExhaustGasTemperature : 0|16@1- (0.25,0) [-8192|8191.75] "°F" Vector__XXX

BO_ 172 AirInletTemperature: 2 Vector__XXX
 SG_ AirInletTemperature : 0|16@1- (0.25,0) [-8192|8191.75] "°F" Vector__XXX

BO_ 171 AmbientAirTemperature: 2 Vector__XXX
 SG_ AmbientAirTemperature : 0|16@1- (0.25,0) [-8192|8191.75] "°F" Vector__XXX

BO_ 170 CabInteriorTemperature: 2 Vector__XXX
 SG_ CabInteriorTemperature : 0|16@1- (0.25,0) [-8192|8191.75] "°F" Vector__XXX

BO_ 169 CargoAmbientTemperature: 2 Vector__XXX
 SG_ CargoAmbientTemperature : 0|16@1- (0.25,0) [-8192|8191.75] "°F" Vector__XXX

BO_ 168 BatteryPotential: 2 Vector__XXX
 SG_ BatteryPotential : 0|16@1+ (0.05,0) [0|3276.75] "V" Vector__XXX

BO_ 167 AlternatorPotential: 2 Vector__XXX
 SG_ AlternatorPotential : 0|16@1+ (0.05,0) [0|3276.75] "V" Vector__XXX

BO_ 166 RatedEnginePower: 2 Vector__XXX
 SG_ RatedEnginePower : 0|16@1+ (0.745,0) [0|48869.4] "kW" Vector__XXX

BO_ 165 CompassBearing: 2 Vector__XXX
 SG_ CompassBearing : 0|16@1+ (0.01,0) [0|655.35] "°" Vector__XXX

BO_ 164 InjectionControlPressure: 2 Vector__XXX
 SG_ InjectionControlPressure : 0|16@1+ (0.00390625,0) [0|255.996] "MPa" Vector__XXX

BO_ 163 TransmissionRangeAttained: 2 Vector__XXX
 SG_ ASCIICharacter2 : 8|8@1+ (1,0) [0|127] "ASCII" Vector__XXX
 SG_ ASCIICharacter1 : 0|8@1+ (1,0) [0|127] "ASCII" Vector__XXX

BO_ 162 TransmissionRangeSelected: 2 Vector__XXX
 SG_ ASCIICharacter2 : 8|8@1+ (1,0) [0|127] "ASCII" Vector__XXX
 SG_ ASCIICharacter1 : 0|8@1+ (1,0) [0|127] "ASCII" Vector__XXX

BO_ 159 GasSupplyPressure: 2 Vector__XXX
 SG_ GasSupplyPressure : 0|16@1+ (0.345,0) [0|22609.6] "kPa" Vector__XXX

BO_ 158 BatteryPotentialSwitched: 2 Vector__XXX
 SG_ BatteryPotentialSwitched : 0|16@1+ (0.05,0) [0|3276.75] "V" Vector__XXX

BO_ 157 InjectorMeteringRailPressure: 2 Vector__XXX
 SG_ InjectorMeteringRailPressure : 0|16@1+ (0.689,0) [0|45153.6] "kPa" Vector__XXX

BO_ 156 InjectorTimingRailPressure: 2 Vector__XXX
 SG_ InjectorTimingRailPressure : 0|16@1+ (0.689,0) [0|45153.6] "kPa" Vector__XXX

BO_ 155 AuxiliaryInputAndOutputStatus1: 2 Vector__XXX
 SG_ AuxiliaryOutput4 : 14|2@1+ (1,0) [0|3] "" Vector__XXX
 SG_ AuxiliaryOutput3 : 12|2@1+ (1,0) [0|3] "" Vector__XXX
 SG_ AuxiliaryOutput2 : 10|2@1+ (1,0) [0|3] "" Vector__XXX
 SG_ AuxiliaryOutput1 : 8|2@1+ (1,0) [0|3] "" Vector__XXX
 SG_ AuxiliaryInput4 : 6|2@1+ (1,0) [0|3] "" Vector__XXX
 SG_ AuxiliaryInput3 : 4|2@1+ (1,0) [0|3] "" Vector__XXX
 SG_ AuxiliaryInput2 : 2|2@1+ (1,0) [0|3] "" Vector__XXX
 SG_ AuxiliaryInput1 : 0|2@1+ (1,0) [0|3] "" Vector__XXX

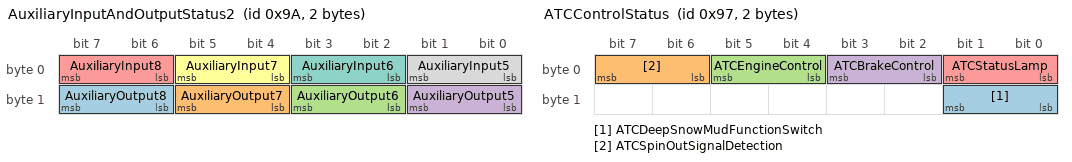
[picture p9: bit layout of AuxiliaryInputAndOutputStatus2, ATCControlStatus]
BO_ 154 AuxiliaryInputAndOutputStatus2: 2 Vector__XXX
 SG_ AuxiliaryOutput8 : 14|2@1+ (1,0) [0|3] "" Vector__XXX
 SG_ AuxiliaryOutput7 : 12|2@1+ (1,0) [0|3] "" Vector__XXX
 SG_ AuxiliaryOutput6 : 10|2@1+ (1,0) [0|3] "" Vector__XXX
 SG_ AuxiliaryOutput5 : 8|2@1+ (1,0) [0|3] "" Vector__XXX
 SG_ AuxiliaryInput8 : 6|2@1+ (1,0) [0|3] "" Vector__XXX
 SG_ AuxiliaryInput7 : 4|2@1+ (1,0) [0|3] "" Vector__XXX
 SG_ AuxiliaryInput6 : 2|2@1+ (1,0) [0|3] "" Vector__XXX
 SG_ AuxiliaryInput5 : 0|2@1+ (1,0) [0|3] "" Vector__XXX

BO_ 153 CrankcasePressure2: 2 Vector__XXX
 SG_ CrankcasePressure2 : 0|16@1- (0.0078125,0) [-256|255.99] "kPa" Vector__XXX

BO_ 152 NumberOfECUResets: 2 Vector__XXX
 SG_ NumberOfECUResets : 0|16@1+ (1,0) [0|65535] "" Vector__XXX

BO_ 151 ATCControlStatus: 2 Vector__XXX
 SG_ ATCDeepSnowMudFunctionSwitch : 8|2@1+ (1,0) [0|3] "" Vector__XXX
 SG_ ATCSpinOutSignalDetection : 6|2@1+ (1,0) [0|3] "" Vector__XXX
 SG_ ATCEngineControl : 4|2@1+ (1,0) [0|3] "" Vector__XXX
 SG_ ATCBrakeControl : 2|2@1+ (1,0) [0|3] "" Vector__XXX
 SG_ ATCStatusLamp : 0|2@1+ (1,0) [0|3] "" Vector__XXX

BO_ 149 MassFlowRate: 2 Vector__XXX
 SG_ MassFlowRate : 0|16@1+ (0.125,0) [0|8191.875] "kg/h" Vector__XXX

BO_ 148 InstantaneousFuelEconomy: 2 Vector__XXX
 SG_ InstantaneousFuelEconomy : 0|16@1+ (0.001953125,0) [0|127.998] "km/kg" Vector__XXX

BO_ 147 AverageFuelEconomy: 2 Vector__XXX
 SG_ AverageFuelEconomy : 0|16@1+ (0.001953125,0) [0|127.998] "km/kg" Vector__XXX

BO_ 146 SteerChannelTirePressure: 2 Vector__XXX
 SG_ SteerChannelTirePressure : 0|16@1+ (0.689,0) [0|45153.615] "kPa" Vector__XXX

BO_ 145 DriveChannelTirePressure: 2 Vector__XXX
 SG_ DriveChannelTirePressure : 0|16@1+ (0.689,0) [0|45153.6] "kPa" Vector__XXX

BO_ 198 CDP: 2 Vector__XXX
 SG_ SegmentID : 8|8@1+ (1,0) [0|255] "" Vector__XXX
 SG_ ReceiverMID : 0|8@1+ (1,0) [0|255] "" Vector__XXX

BO_ 197 CMP: 5 Vector__XXX
 SG_ RSDRequestAssignment m4 : 16|16@1+ (1,0) [0|65535] "" Vector__XXX
 SG_ CTSNextSegment m2 : 24|8@1+ (1,0) [0|255] "" Vector__XXX
 SG_ CTSNumberOfSegments m2 : 16|8@1+ (1,0) [0|255] "" Vector__XXX
 SG_ RTSNumberOfDataBytes m1 : 24|16@1+ (1,0) [0|65535] "" Vector__XXX
 SG_ RTSNumberOfSegments m1 : 16|8@1+ (1,0) [0|255] "" Vector__XXX
 SG_ ReceiverMID : 0|8@1+ (1,0) [0|255] "" Vector__XXX
 SG_ CMCommand M : 8|8@1+ (1,0) [0|255] "" Vector__XXX

BO_ 144 TirePressure1: 2 Vector__XXX
 SG_ TirePressure1 : 0|16@1+ (0.689,0) [0|56153.6] "kPa" Vector__XXX

BO_ 143 SteerChannelTirePressureTarget: 2 Vector__XXX
 SG_ SteerChannelTirePressureTarget : 0|16@1+ (0.689,0) [0|45153.6] "kPa" Vector__XXX

BO_ 142 DriveChannelTirePressureTarget: 2 Vector__XXX
 SG_ DriveChannelTirePressureTarget : 0|16@1+ (0.689,0) [0|45153.6] "kPa" Vector__XXX

BO_ 141 TirePressureTarget1: 2 Vector__XXX
 SG_ TirePressureTarget1 : 0|16@1+ (0.689,0) [0|45153.6] "kPa" Vector__XXX

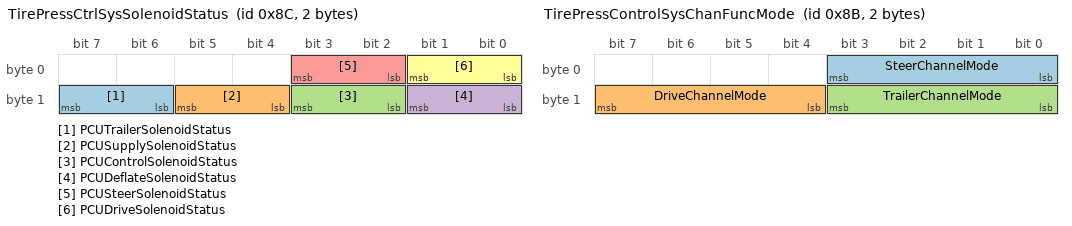
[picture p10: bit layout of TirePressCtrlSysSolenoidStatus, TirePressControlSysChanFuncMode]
BO_ 140 TirePressCtrlSysSolenoidStatus: 2 Vector__XXX
 SG_ PCUTrailerSolenoidStatus : 14|2@1+ (1,0) [0|0] "" Vector__XXX
 SG_ PCUSupplySolenoidStatus : 12|2@1+ (1,0) [0|0] "" Vector__XXX
 SG_ PCUControlSolenoidStatus : 10|2@1+ (1,0) [0|0] "" Vector__XXX
 SG_ PCUDeflateSolenoidStatus : 8|2@1+ (1,0) [0|0] "" Vector__XXX
 SG_ PCUSteerSolenoidStatus : 2|2@1+ (1,0) [0|0] "" Vector__XXX
 SG_ PCUDriveSolenoidStatus : 0|2@1+ (1,0) [0|0] "" Vector__XXX

BO_ 139 TirePressControlSysChanFuncMode: 2 Vector__XXX
 SG_ SteerChannelMode : 0|4@1+ (1,0) [0|15] "" Vector__XXX
 SG_ DriveChannelMode : 12|4@1+ (1,0) [0|15] "" Vector__XXX
 SG_ TrailerChannelMode : 8|4@1+ (1,0) [0|15] "" Vector__XXX

BO_ 138 AuxiliaryAbsolutePressureReading: 2 Vector__XXX
 SG_ AuxiliaryAbsolutePressureReading : 0|16@1+ (0.689,0) [0|45153.6] "kPa" Vector__XXX

BO_ 137 AuxiliaryGagePressureReading1: 2 Vector__XXX
 SG_ AuxiliaryGagePressureReading1 : 0|16@1+ (0.689,0) [0|45153.6] "kPa" Vector__XXX

BO_ 136 AuxVacuumPressureReading: 2 Vector__XXX
 SG_ AuxVacuumPressureReading : 0|16@1+ (0.689,0) [0|45153.6] "kPa" Vector__XXX

BO_ 135 ExRangeFuelDeliveryPressure: 2 Vector__XXX
 SG_ ExRangeFuelDeliveryPressure : 0|16@1+ (0.689,0) [0|45153.6] "kPa" Vector__XXX

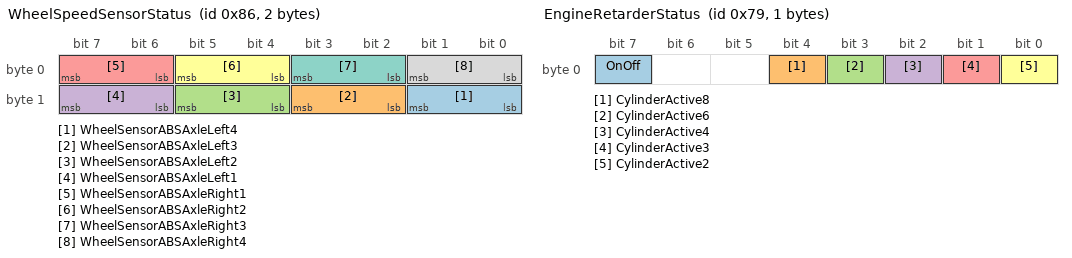
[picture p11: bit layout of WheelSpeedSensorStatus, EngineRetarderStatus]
BO_ 134 WheelSpeedSensorStatus: 2 Vector__XXX
 SG_ WheelSensorABSAxleLeft4 : 8|2@1+ (1,0) [0|3] "" Vector__XXX
 SG_ WheelSensorABSAxleLeft3 : 10|2@1+ (1,0) [0|3] "" Vector__XXX
 SG_ WheelSensorABSAxleLeft2 : 12|2@1+ (1,0) [0|3] "" Vector__XXX
 SG_ WheelSensorABSAxleLeft1 : 14|2@1+ (1,0) [0|3] "" Vector__XXX
 SG_ WheelSensorABSAxleRight1 : 6|2@1+ (1,0) [0|3] "" Vector__XXX
 SG_ WheelSensorABSAxleRight2 : 4|2@1+ (1,0) [0|3] "" Vector__XXX
 SG_ WheelSensorABSAxleRight3 : 2|2@1+ (1,0) [0|3] "" Vector__XXX
 SG_ WheelSensorABSAxleRight4 : 0|2@1+ (1,0) [0|3] "" Vector__XXX

BO_ 133 AverageFuelRate: 2 Vector__XXX
 SG_ AverageFuelRate : 0|16@1+ (1.6428E-005,0) [0|107665] "L/s" Vector__XXX

BO_ 132 MassAirFlow: 2 Vector__XXX
 SG_ MassAirFlow : 0|16@1+ (0.125,0) [0|8192.875] "kg/min" Vector__XXX

BO_ 131 ExhaustBackPressure: 2 Vector__XXX
 SG_ ExhaustBackPressure : 0|16@1+ (0.006733,0) [0|441.258] "kPa" Vector__XXX

BO_ 130 PowerSpecificFuelEconomy: 2 Vector__XXX
 SG_ PowerSpecificFuelEconomy : 0|16@1+ (0.00197,0) [0|129.1] "kW h/L" Vector__XXX

BO_ 129 InjectorMeteringRail2Pressure: 2 Vector__XXX
 SG_ InjectorMeteringRail2Pressure : 0|16@1+ (0.689,0) [0|45153.6] "kPa" Vector__XXX

BO_ 128 ComponentSpecificParamRequest: 2 Vector__XXX
 SG_ MID : 8|8@1+ (1,0) [0|255] "" Vector__XXX
 SG_ ParameterNumber : 0|8@1+ (1,0) [0|255] "" Vector__XXX

BO_ 127 TransmissionOilPressure: 1 Vector__XXX
 SG_ TransmissionOilPressure : 0|8@1+ (13.8,0) [0|3516] "kPa" Vector__XXX

BO_ 126 TransmissionFilterDiffPressure: 1 Vector__XXX
 SG_ TransmissionFilterDiffPressure : 0|8@1+ (1.724,0) [0|439.5] "kPa" Vector__XXX

BO_ 125 TransmissionOilLevelHighLow: 1 Vector__XXX
 SG_ TransmissionOilLevelHighLow : 0|8@1+ (0.473,-60.6) [-60.6|60.1] "L" Vector__XXX

BO_ 124 TransmissionOilLevel: 1 Vector__XXX
 SG_ TransmissionOilLevel : 0|8@1+ (0.5,0) [0|127.5] "%" Vector__XXX

BO_ 123 ClutchPressure: 1 Vector__XXX
 SG_ ClutchPressure : 0|8@1+ (14.8,0) [0|3516] "kPa" Vector__XXX

BO_ 122 EngineRetarderPercent: 1 Vector__XXX
 SG_ EngineRetarderPercent : 0|8@1+ (0.5,0) [0|127.5] "%" Vector__XXX

BO_ 121 EngineRetarderStatus: 1 Vector__XXX
 SG_ OnOff : 7|1@1+ (1,0) [0|1] "" Vector__XXX
 SG_ CylinderActive8 : 4|1@1+ (1,0) [0|1] "" Vector__XXX
 SG_ CylinderActive6 : 3|1@1+ (1,0) [0|1] "" Vector__XXX
 SG_ CylinderActive4 : 2|1@1+ (1,0) [0|1] "" Vector__XXX
 SG_ CylinderActive3 : 1|1@1+ (1,0) [0|1] "" Vector__XXX
 SG_ CylinderActive2 : 0|1@1+ (1,0) [0|1] "" Vector__XXX

BO_ 120 HydraulicRetarderOilTemp: 1 Vector__XXX
 SG_ HydraulicRetarderOilTemp : 0|8@1+ (2,0) [0|510] "°F" Vector__XXX

BO_ 119 HydraulicRetarderPressure: 1 Vector__XXX
 SG_ HydraulicRetarderPressure : 0|8@1+ (4.14,0) [0|1055] "kPa" Vector__XXX

BO_ 118 BrakeSecondaryPressure: 1 Vector__XXX
 SG_ BrakeSecondaryPressure : 0|8@1+ (4.14,0) [0|1055] "kPa" Vector__XXX

BO_ 117 BrakePrimaryPressure: 1 Vector__XXX
 SG_ BrakePrimaryPressure : 0|8@1+ (4.14,0) [0|1055] "kPa" Vector__XXX

BO_ 116 BrakeApplicationPressure: 1 Vector__XXX
 SG_ BrakeApplicationPressure : 0|8@1+ (4.14,0) [0|1055] "kPa" Vector__XXX

BO_ 115 AlternatorCurrent: 1 Vector__XXX
 SG_ AlternatorCurrent : 0|8@1+ (1.2,0) [0|306] "A" Vector__XXX

BO_ 114 NetBatteryCurrent: 1 Vector__XXX
 SG_ NetBatteryCurrent : 0|8@1+ (1.2,-153.6) [-153.6|152] "A" Vector__XXX

BO_ 113 GovernorDroop: 1 Vector__XXX
 SG_ GovernorDroop : 0|8@1+ (2,0) [0|510] "rpm" Vector__XXX

BO_ 112 CoolantFilterDiffPressure: 1 Vector__XXX
 SG_ CoolantFilterDiffPressure : 0|8@1+ (0.431,0) [0|109.9] "kPa" Vector__XXX

BO_ 111 CoolantLevel: 1 Vector__XXX
 SG_ CoolantLevel : 0|8@1+ (0.5,0) [0|127.5] "%" Vector__XXX

BO_ 109 CoolantPressure: 1 Vector__XXX
 SG_ CoolantPressure : 0|8@1+ (0.862,0) [0|219.8] "kPa" Vector__XXX

BO_ 108 BarometricPressure: 1 Vector__XXX
 SG_ BarometricPressure : 0|8@1+ (0.431,0) [0|109.9] "kPa" Vector__XXX

BO_ 107 AirFilterDifferentialPressure: 1 Vector__XXX
 SG_ AirFilterDifferentialPressure : 0|8@1+ (0.0498,0) [0|12.7] "kPa" Vector__XXX

BO_ 106 AirInletPressure: 1 Vector__XXX
 SG_ AirInletPressure : 0|8@1+ (1.724,0) [0|439.5] "kPa" Vector__XXX

BO_ 105 IntakeManifoldTemperature: 1 Vector__XXX
 SG_ IntakeManifoldTemperature : 0|8@1+ (1,0) [0|255] "°F" Vector__XXX

BO_ 102 BoostPressure: 1 Vector__XXX
 SG_ BoostPressure : 0|8@1+ (0.862,0) [0|219.8] "kPa" Vector__XXX

BO_ 101 CrankcasePressure: 1 Vector__XXX
 SG_ CrankcasePressure : 0|8@1+ (0.862,-110) [-110|109.5] "kPa" Vector__XXX

BO_ 99 EngineOilFilterDiffPressure: 1 Vector__XXX
 SG_ EngineOilFilterDiffPressure : 0|8@1+ (0.431,0) [0|109.9] "kPa" Vector__XXX

BO_ 97 WaterInFuelIndicator: 1 Vector__XXX
 SG_ WaterInFuelIndicator : 7|1@1+ (1,0) [0|1] "" Vector__XXX

BO_ 96 FuelLevel: 1 Vector__XXX
 SG_ FuelLevel : 0|8@1+ (0.5,0) [0|127.5] "%" Vector__XXX

BO_ 95 FuelFilterDifferentialPressure: 1 Vector__XXX

BO_ 94 FuelDeliveryPressure: 1 Vector__XXX
 SG_ FuelFilterDifferentialPressure : 8|8@1+ (1.724,0) [0|439.5] "kPa" Vector__XXX
 SG_ FuelDeliveryPressure : 0|8@1+ (3.45,0) [0|879] "kPa" Vector__XXX

BO_ 93 OutputTorque: 1 Vector__XXX
 SG_ OutputTorque : 0|8@1+ (0.4,0) [0|103] "%" Vector__XXX

BO_ 92 PercentEngineLoad: 1 Vector__XXX
 SG_ PercentEngineLoad : 0|8@1+ (0.5,0) [0|127.5] "%" Vector__XXX

BO_ 91 PercentAcceleratorPedalPosition: 1 Vector__XXX
 SG_ PercentAcceleratorPedalPosition : 0|8@1+ (0.4,0) [0|102] "%" Vector__XXX

BO_ 90 PowerTakeoffOilTemperature: 1 Vector__XXX
 SG_ PowerTakeoffOilTemperature : 0|8@1+ (1.2,0) [0|306] "°F" Vector__XXX

BO_ 86 CruiseControlSetSpeed: 1 Vector__XXX
 SG_ CruiseControlSetSpeed : 0|8@1+ (0.805,0) [0|205.2] "km/h" Vector__XXX

BO_ 83 RoadSpeedLimitStatus: 1 Vector__XXX
 SG_ RoadSpeedLimitStatus : 7|1@1+ (1,0) [0|1] "" Vector__XXX

BO_ 82 AirStartPressure: 1 Vector__XXX
 SG_ AirStartPressure : 0|8@1+ (4.14,0) [0|1055] "kPa" Vector__XXX

BO_ 81 ParticulateTrapInletPressure: 1 Vector__XXX
 SG_ ParticulateTrapInletPressure : 0|8@1+ (0.169,0) [0|43.1] "kPa" Vector__XXX

BO_ 80 WasherFluidLevel: 1 Vector__XXX
 SG_ WasherFluidLevel : 0|8@1+ (0.5,0) [0|127.5] "%" Vector__XXX

BO_ 79 RoadSurfaceTemperature: 1 Vector__XXX
 SG_ RoadSurfaceTemperature : 0|8@1+ (2.5,-320) [-320|317.5] "°F" Vector__XXX

BO_ 78 RearRearDriveAxleTemperature: 1 Vector__XXX
 SG_ RearRearDriveAxleTemperature : 0|8@1+ (1.2,0) [0|306] "°F" Vector__XXX

BO_ 77 ForwardRearDriveAxleTemperature: 1 Vector__XXX
 SG_ ForwardRearDriveAxleTemperature : 0|8@1+ (1.2,0) [0|306] "°F" Vector__XXX

BO_ 76 Axle1LiftAirPressure: 1 Vector__XXX
 SG_ Axle1LiftAirPressure : 0|8@1+ (4.14,0) [0|1055] "kPa" Vector__XXX

BO_ 75 SteeringAxleTemperature: 1 Vector__XXX
 SG_ SteeringAxleTemperature : 0|8@1+ (1.2,0) [0|306] "°F" Vector__XXX

BO_ 74 MaximumRoadSpeedLimit: 1 Vector__XXX
 SG_ MaximumRoadSpeedLimit : 0|8@1+ (0.805,0) [0|205.2] "km/h" Vector__XXX

BO_ 73 AuxiliaryWaterPumpPressure: 1 Vector__XXX
 SG_ AuxiliaryWaterPumpPressure : 0|8@1+ (13.8,0) [0|3516] "kPa" Vector__XXX

BO_ 72 BlowerBypassValvePosition: 1 Vector__XXX
 SG_ BlowerBypassValvePosition : 0|8@1+ (0.4,0) [0|102] "%" Vector__XXX

BO_ 69 TwoSpeedAxleSwitchStatus: 1 Vector__XXX
 SG_ TwoSpeedAxleSwitchStatus : 7|1@1+ (1,0) [0|1] "" Vector__XXX

BO_ 68 TorqueLimitingFactor: 1 Vector__XXX
 SG_ TorqueLimitingFactor : 0|8@1+ (0.5,0) [0|127.5] "%" Vector__XXX

BO_ 67 ShiftRequestSwitchStatus: 1 Vector__XXX
 SG_ DownshiftSwitchStatus : 2|2@1+ (1,0) [0|3] "" Vector__XXX
 SG_ UpshiftSwitchStatus : 0|2@1+ (1,0) [0|3] "" Vector__XXX

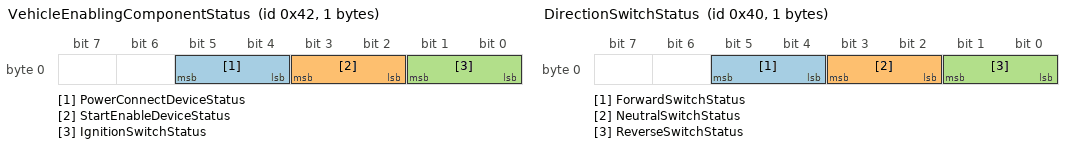
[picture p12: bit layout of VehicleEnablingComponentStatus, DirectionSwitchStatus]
BO_ 66 VehicleEnablingComponentStatus: 1 Vector__XXX
 SG_ PowerConnectDeviceStatus : 4|2@1+ (1,0) [0|3] "" Vector__XXX
 SG_ StartEnableDeviceStatus : 2|2@1+ (1,0) [0|3] "" Vector__XXX
 SG_ IgnitionSwitchStatus : 0|2@1+ (1,0) [0|3] "" Vector__XXX

BO_ 65 BrakeSwitchStatus: 1 Vector__XXX
 SG_ BrakeSystemSwitchStatus : 2|2@1+ (1,0) [0|3] "" Vector__XXX
 SG_ ServiceBrakeSwitchStatus : 0|2@1+ (1,0) [0|3] "" Vector__XXX

BO_ 64 DirectionSwitchStatus: 1 Vector__XXX
 SG_ ForwardSwitchStatus : 4|2@1+ (1,0) [0|3] "" Vector__XXX
 SG_ NeutralSwitchStatus : 2|2@1+ (1,0) [0|3] "" Vector__XXX
 SG_ ReverseSwitchStatus : 0|2@1+ (1,0) [0|3] "" Vector__XXX

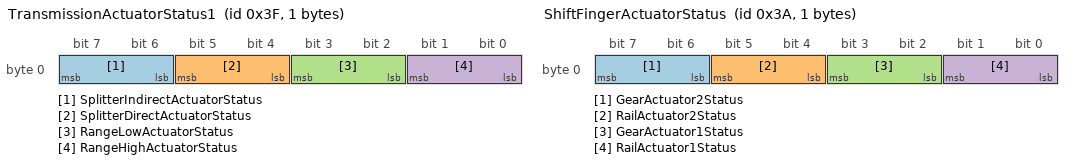
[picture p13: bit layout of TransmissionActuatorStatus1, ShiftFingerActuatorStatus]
BO_ 63 TransmissionActuatorStatus1: 1 Vector__XXX
 SG_ SplitterIndirectActuatorStatus : 6|2@1+ (1,0) [0|3] "" Vector__XXX
 SG_ SplitterDirectActuatorStatus : 4|2@1+ (1,0) [0|3] "" Vector__XXX
 SG_ RangeLowActuatorStatus : 2|2@1+ (1,0) [0|3] "" Vector__XXX
 SG_ RangeHighActuatorStatus : 0|2@1+ (1,0) [0|3] "" Vector__XXX

BO_ 62 RetarderInhibitStatus: 1 Vector__XXX
 SG_ RetarderInhibitStatus : 0|2@1+ (1,0) [0|3] "" Vector__XXX

BO_ 61 ParkingBrakeActuatorStatus: 1 Vector__XXX
 SG_ ParkingBrakeOffActuatorStatus : 2|2@1+ (1,0) [0|3] "" Vector__XXX
 SG_ ParkingBrakeOnActuatorStatus : 0|2@1+ (1,0) [0|3] "" Vector__XXX

BO_ 60 ShiftFingerRailPosition: 1 Vector__XXX
 SG_ ShiftFingerRailPosition : 0|8@1+ (0.4,0) [0|102] "%" Vector__XXX

BO_ 59 ShiftFingerGearPosition: 1 Vector__XXX
 SG_ ShiftFingerGearPosition : 0|8@1+ (0.4,0) [0|102] "%" Vector__XXX

BO_ 58 ShiftFingerActuatorStatus: 1 Vector__XXX
 SG_ GearActuator2Status : 6|2@1+ (1,0) [0|3] "" Vector__XXX
 SG_ RailActuator2Status : 4|2@1+ (1,0) [0|3] "" Vector__XXX
 SG_ GearActuator1Status : 2|2@1+ (1,0) [0|3] "" Vector__XXX
 SG_ RailActuator1Status : 0|2@1+ (1,0) [0|3] "" Vector__XXX

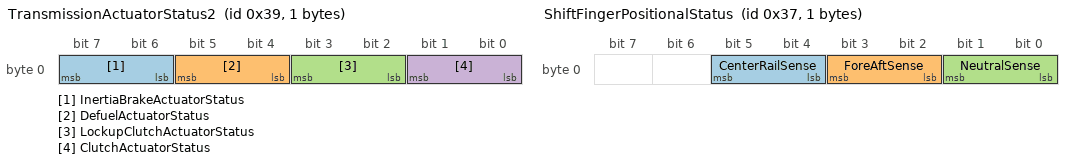
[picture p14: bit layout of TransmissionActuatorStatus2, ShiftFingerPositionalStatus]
BO_ 57 TransmissionActuatorStatus2: 1 Vector__XXX
 SG_ InertiaBrakeActuatorStatus : 6|2@1+ (1,0) [0|3] "" Vector__XXX
 SG_ DefuelActuatorStatus : 4|2@1+ (1,0) [0|3] "" Vector__XXX
 SG_ LockupClutchActuatorStatus : 2|2@1+ (1,0) [0|3] "" Vector__XXX
 SG_ ClutchActuatorStatus : 0|2@1+ (1,0) [0|3] "" Vector__XXX

BO_ 56 TransmissionRangeSwitchStatus: 1 Vector__XXX
 SG_ LowRangeSense : 2|2@1+ (1,0) [0|3] "" Vector__XXX
 SG_ HighRangeSense : 0|2@1+ (1,0) [0|3] "" Vector__XXX

BO_ 55 ShiftFingerPositionalStatus: 1 Vector__XXX
 SG_ CenterRailSense : 4|2@1+ (1,0) [0|3] "" Vector__XXX
 SG_ ForeAftSense : 2|2@1+ (1,0) [0|3] "" Vector__XXX
 SG_ NeutralSense : 0|2@1+ (1,0) [0|3] "" Vector__XXX

BO_ 54 TransmissionSyncBrakeValue: 1 Vector__XXX
 SG_ TransmissionSyncBrakeValue : 0|8@1+ (0.4,0) [0|102] "%" Vector__XXX

BO_ 53 TransmissionSyncClutchValue: 1 Vector__XXX
 SG_ TransmissionSyncClutchValue : 0|8@1+ (0.4,0) [0|102] "%" Vector__XXX

BO_ 51 ThrottlePosition: 1 Vector__XXX
 SG_ ThrottlePosition : 0|8@1+ (1,0) [0.4|102] "%" Vector__XXX

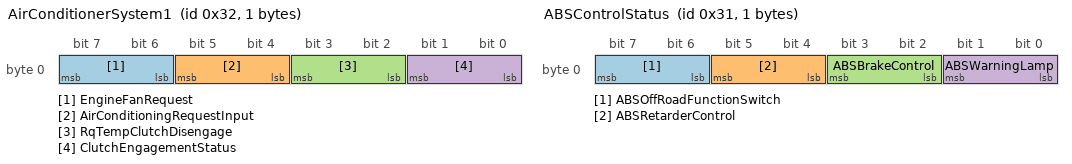
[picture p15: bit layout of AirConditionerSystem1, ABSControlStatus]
BO_ 50 AirConditionerSystem1: 1 Vector__XXX
 SG_ EngineFanRequest : 6|2@1+ (1,0) [0|3] "" Vector__XXX
 SG_ AirConditioningRequestInput : 4|2@1+ (1,0) [0|3] "" Vector__XXX
 SG_ RqTempClutchDisengage : 2|2@1+ (1,0) [0|3] "" Vector__XXX
 SG_ ClutchEngagementStatus : 0|2@1+ (1,0) [0|3] "" Vector__XXX

BO_ 49 ABSControlStatus: 1 Vector__XXX
 SG_ ABSOffRoadFunctionSwitch : 6|2@1+ (1,0) [0|3] "" Vector__XXX
 SG_ ABSRetarderControl : 4|2@1+ (1,0) [0|3] "" Vector__XXX
 SG_ ABSBrakeControl : 2|2@1+ (1,0) [0|3] "" Vector__XXX
 SG_ ABSWarningLamp : 0|2@1+ (1,0) [0|3] "" Vector__XXX

BO_ 48 ExtendedRangeBarometricPressure: 1 Vector__XXX
 SG_ ExtendedRangeBarometricPressure : 0|8@1+ (0.6,0) [0|153] "kPa" Vector__XXX

BO_ 47 RetarderStatus: 1 Vector__XXX
 SG_ TransmissionOutputRetarderStatus : 0|2@1+ (1,0) [0|3] "" Vector__XXX

BO_ 45 InletAirHeaterStatus: 1 Vector__XXX
 SG_ WaitToStartLamp : 4|2@1+ (1,0) [0|3] "" Vector__XXX
 SG_ Heater2Status : 2|2@1+ (1,0) [0|3] "" Vector__XXX
 SG_ Heater1Status : 0|2@1+ (1,0) [0|3] "" Vector__XXX

BO_ 42 PressureSwitchStatus: 1 Vector__XXX
 SG_ TirePressureSupplySwitchStatus : 0|2@1+ (1,0) [0|3] "" Vector__XXX

BO_ 41 CruiseControlSwitchesStatus: 1 Vector__XXX
 SG_ CruiseControlOnOffSwitchStatus : 4|2@1+ (1,0) [0|3] "" Vector__XXX
 SG_ CruiseControlSetSwitchStatus : 2|2@1+ (1,0) [0|3] "" Vector__XXX
 SG_ CruiseControlResumeSwitchStatus : 0|2@1+ (1,0) [0|3] "" Vector__XXX

BO_ 40 EngineRetarderSwitchesStatus: 1 Vector__XXX
 SG_ EngineRetarderLevelSwitch : 2|4@1+ (1,0) [0|15] "" Vector__XXX
 SG_ EngineRetarderSwitch : 0|2@1+ (1,0) [0|2] "" Vector__XXX

BO_ 39 TirePressureCheckInterval: 1 Vector__XXX
 SG_ TirePressureCheckInterval : 0|8@1+ (1,0) [0|255] "min" Vector__XXX

BO_ 38 SecondFuelLevel_RightSide: 1 Vector__XXX
 SG_ SecondFuelLevel_RightSide : 0|8@1+ (0.5,0) [0|127.5] "%" Vector__XXX

BO_ 37 TransmissionTankAirPressure: 1 Vector__XXX
 SG_ TransmissionTankAirPressure : 0|8@1+ (6.89,0) [0|1757] "kPa" Vector__XXX

BO_ 36 ClutchPlatesWearCondition: 1 Vector__XXX
 SG_ ClutchPlatesWearCondition : 0|8@1+ (0.4,0) [0|102] "%" Vector__XXX

BO_ 35 ShiftFingerActuatorStatus2: 1 Vector__XXX
 SG_ GearActuator3Status : 2|2@1+ (1,0) [0|3] "" Vector__XXX
 SG_ RailActuator3Status : 0|2@1+ (1,0) [0|3] "" Vector__XXX

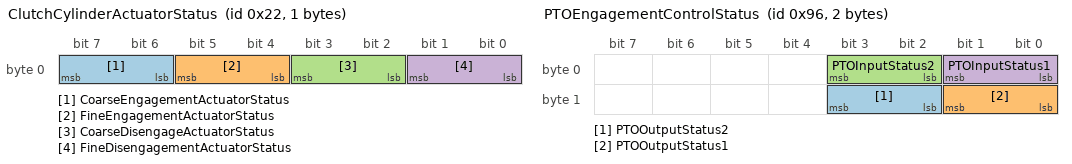
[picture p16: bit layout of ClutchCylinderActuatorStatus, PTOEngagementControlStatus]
BO_ 34 ClutchCylinderActuatorStatus: 1 Vector__XXX
 SG_ CoarseEngagementActuatorStatus : 6|2@1+ (1,0) [0|3] "" Vector__XXX
 SG_ FineEngagementActuatorStatus : 4|2@1+ (1,0) [0|3] "" Vector__XXX
 SG_ CoarseDisengageActuatorStatus : 2|2@1+ (1,0) [0|3] "" Vector__XXX
 SG_ FineDisengagementActuatorStatus : 0|2@1+ (1,0) [0|3] "" Vector__XXX

BO_ 33 ClutchCylinderPosition: 1 Vector__XXX
 SG_ ClutchCylinderPosition : 0|8@1+ (0.4,0) [0|102] "%" Vector__XXX

BO_ 32 TransmissionSplitterPosition: 1 Vector__XXX
 SG_ TransmissionSplitterPosition : 0|8@1+ (0.4,0) [0|102] "%" Vector__XXX

BO_ 150 PTOEngagementControlStatus: 2 Vector__XXX
 SG_ PTOOutputStatus2 : 10|2@1+ (1,0) [0|3] "" Vector__XXX
 SG_ PTOOutputStatus1 : 8|2@1+ (1,0) [0|3] "" Vector__XXX
 SG_ PTOInputStatus2 : 2|2@1+ (1,0) [0|3] "" Vector__XXX
 SG_ PTOInputStatus1 : 0|2@1+ (1,0) [0|3] "" Vector__XXX

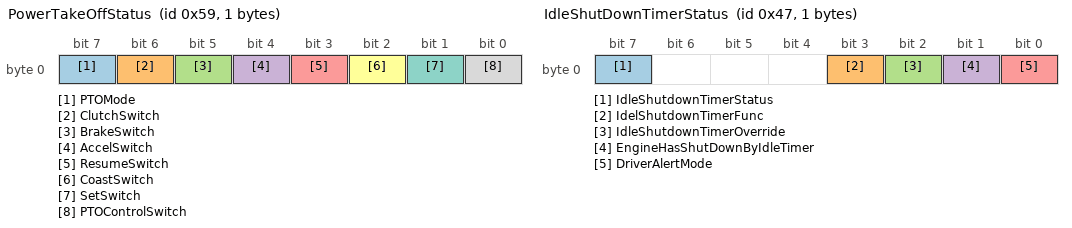
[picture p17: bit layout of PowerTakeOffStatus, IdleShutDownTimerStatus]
BO_ 89 PowerTakeOffStatus: 1 Vector__XXX
 SG_ PTOMode : 7|1@1+ (1,0) [0|1] "" Vector__XXX
 SG_ ClutchSwitch : 6|1@1+ (1,0) [0|1] "" Vector__XXX
 SG_ BrakeSwitch : 5|1@1+ (1,0) [0|1] "" Vector__XXX
 SG_ AccelSwitch : 4|1@1+ (1,0) [0|1] "" Vector__XXX
 SG_ ResumeSwitch : 3|1@1+ (1,0) [0|1] "" Vector__XXX
 SG_ CoastSwitch : 2|1@1+ (1,0) [0|1] "" Vector__XXX
 SG_ SetSwitch : 1|1@1+ (1,0) [0|1] "" Vector__XXX
 SG_ PTOControlSwitch : 0|1@1+ (1,0) [0|1] "" Vector__XXX

BO_ 71 IdleShutDownTimerStatus: 1 Vector__XXX
 SG_ IdleShutdownTimerStatus : 7|1@1+ (1,0) [0|0] "" Vector__XXX
 SG_ IdelShutdownTimerFunc : 3|1@1+ (1,0) [0|1] "" Vector__XXX
 SG_ IdleShutdownTimerOverride : 2|1@1+ (1,0) [0|1] "" Vector__XXX
 SG_ EngineHasShutDownByIdleTimer : 1|1@1+ (1,0) [0|1] "" Vector__XXX
 SG_ DriverAlertMode : 0|1@1+ (1,0) [0|1] "" Vector__XXX

BO_ 70 ParkingBrakeSwitch: 1 Vector__XXX
 SG_ ParkingBrakeSwitch : 7|1@1+ (1,0) [0|1] "" Vector__XXX

BO_ 46 VehicleWetTankPressure: 1 Vector__XXX
 SG_ VehicleWetTankPressue : 0|8@1+ (6.89,0) [0|1757] "kPa" Vector__XXX

BO_ 44 IndicatorLampStatus: 1 Vector__XXX
 SG_ ProtectLamp : 4|2@1+ (1,0) [0|3] "" Vector__XXX
 SG_ AmberLamp : 2|2@1+ (1,0) [0|3] "" Vector__XXX
 SG_ RedLamp : 0|2@1+ (1,0) [0|3] "" Vector__XXX

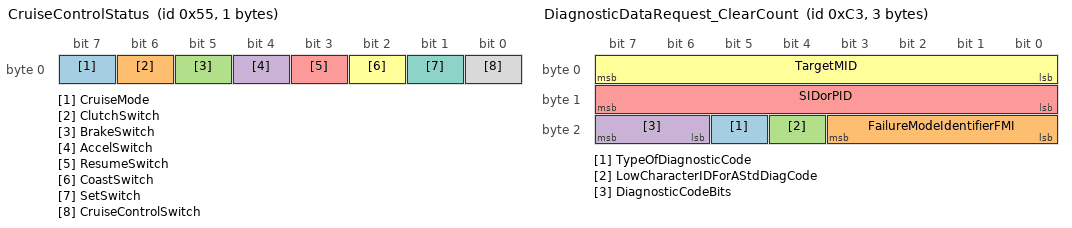
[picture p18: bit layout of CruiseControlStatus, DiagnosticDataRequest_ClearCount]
BO_ 85 CruiseControlStatus: 1 Vector__XXX
 SG_ CruiseMode : 7|1@1+ (1,0) [0|1] "" Vector__XXX
 SG_ ClutchSwitch : 6|1@1+ (1,0) [0|1] "" Vector__XXX
 SG_ BrakeSwitch : 5|1@1+ (1,0) [0|1] "" Vector__XXX
 SG_ AccelSwitch : 4|1@1+ (1,0) [0|1] "" Vector__XXX
 SG_ ResumeSwitch : 3|1@1+ (1,0) [0|1] "" Vector__XXX
 SG_ CoastSwitch : 2|1@1+ (1,0) [0|1] "" Vector__XXX
 SG_ SetSwitch : 1|1@1+ (1,0) [0|1] "" Vector__XXX
 SG_ CruiseControlSwitch : 0|1@1+ (1,0) [0|1] "" Vector__XXX

BO_ 84 RoadSpeed: 1 Vector__XXX
 SG_ RoadSpeed : 0|8@1+ (0.805,0) [0|205.2] "km/h" Vector__XXX

BO_ 195 DiagnosticDataRequest_ClearCount: 3 Vector__XXX
 SG_ TypeOfDiagnosticCode : 21|1@1+ (1,0) [0|1] "" Vector__XXX
 SG_ FailureModeIdentifierFMI : 16|4@1+ (1,0) [0|15] "" Vector__XXX
 SG_ LowCharacterIDForAStdDiagCode : 20|1@1+ (1,0) [0|1] "" Vector__XXX
 SG_ DiagnosticCodeBits : 22|2@1+ (1,0) [0|3] "" Vector__XXX
 SG_ SIDorPID : 8|8@1+ (1,0) [0|255] "" Vector__XXX
 SG_ TargetMID : 0|8@1+ (1,0) [0|255] "" Vector__XXX

BO_ 193 TransmitterSystemDiagnosticTable: 1 Vector__XXX
 SG_ VarLengthDiagCodeManufacturer : 0|8@1+ (1,0) [0|255] "" Vector__XXX

BO_ 190 EngineSpeed: 2 Vector__XXX
 SG_ EngineSpeed : 0|16@1+ (0.25,0) [0|16383.75] "rpm" Vector__XXX

BO_ 161 InputShaftSpeed: 2 Vector__XXX
 SG_ InputShaftSpeed : 0|16@1+ (0.25,0) [0|16383.75] "rpm" Vector__XXX

BO_ 160 MainShaftSpeed: 2 Vector__XXX
 SG_ MainShaftSpeed : 0|16@1+ (0.25,0) [0|16383.75] "rpm" Vector__XXX

BO_ 110 EngineCoolantTemperature: 1 Vector__XXX
 SG_ EngineCoolantTemperature : 0|8@1+ (1,0) [0|255] "°F" Vector__XXX

BO_ 104 TurboOilPressure: 1 Vector__XXX
 SG_ TurboOilPressure : 0|8@1+ (4.14,0) [0|1055] "kPa" Vector__XXX

BO_ 103 TurboSpeed: 1 Vector__XXX
 SG_ TurboSpeed : 0|8@1+ (500,0) [0|127500] "rpm" Vector__XXX

BO_ 100 EngineOilPressure: 1 Vector__XXX
 SG_ EngineOilPressure : 0|8@1+ (3.45,0) [0|879.75] "kPa" Vector__XXX

BO_ 98 EngineOilLevel: 1 Vector__XXX
 SG_ EngineOilLevel : 0|8@1+ (0.5,0) [0|127.5] "%" Vector__XXX

BO_ 52 EngineIntercoolerTemperature: 1 Vector__XXX
 SG_ EngineIntercoolerTemperature : 0|8@1+ (1,0) [0|255] "°F" Vector__XXX

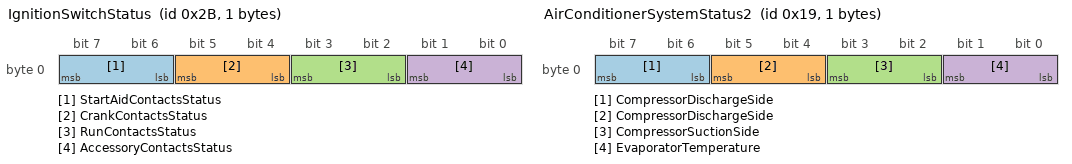
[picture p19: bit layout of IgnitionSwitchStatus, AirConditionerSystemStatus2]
BO_ 43 IgnitionSwitchStatus: 1 Vector__XXX
 SG_ StartAidContactsStatus : 6|2@1+ (1,0) [0|3] "" Vector__XXX
 SG_ CrankContactsStatus : 4|2@1+ (1,0) [0|3] "" Vector__XXX
 SG_ RunContactsStatus : 2|2@1+ (1,0) [0|3] "" Vector__XXX
 SG_ AccessoryContactsStatus : 0|2@1+ (1,0) [0|3] "" Vector__XXX

BO_ 31 TransmissionRangePosition: 1 Vector__XXX
 SG_ TransmissionRangePosition : 0|8@1+ (0.4,0) [0|102] "%" Vector__XXX

BO_ 30 CrankcaseBlowByPressure: 1 Vector__XXX
 SG_ CrankcaseBlowByPressure : 0|8@1+ (0.862,-110) [-110|109.5] "kPa" Vector__XXX

BO_ 29 PercentAcceleratorPosition2: 1 Vector__XXX
 SG_ PercentAcceleratorPosition3 : 0|8@1+ (0.4,0) [0|102] "%" Vector__XXX

BO_ 28 PercentAcceleratorPosition3: 1 Vector__XXX
 SG_ PercentAcceleratorPosition3 : 0|8@1+ (0.4,0) [0|102] "%" Vector__XXX

BO_ 27 PercentExhaustGasRecircValve1Pos: 1 Vector__XXX
 SG_ PercentExhaustGasRecircValve1Pos : 0|8@1+ (0.5,0) [0|127.5] "%" Vector__XXX

BO_ 26 EstimatedPercentFanSpeed: 1 Vector__XXX
 SG_ EstimatedPercentFanSpeed : 0|8@1+ (0.5,0) [0|127.5] "%" Vector__XXX

BO_ 25 AirConditionerSystemStatus2: 1 Vector__XXX
 SG_ CompressorDischargeSide : 6|2@1+ (1,0) [0|3] "" Vector__XXX
 SG_ CompressorDischargeSide : 4|2@1+ (1,0) [0|3] "" Vector__XXX
 SG_ CompressorSuctionSide : 2|2@1+ (1,0) [0|3] "" Vector__XXX
 SG_ EvaporatorTemperature : 0|2@1+ (1,0) [0|3] "" Vector__XXX

BO_ 24 GeneratorCoolantTemperature: 1 Vector__XXX
 SG_ GeneratorCoolantTemperature : 0|8@1+ (1,0) [0|255] "°F" Vector__XXX

BO_ 23 GeneratorOilPressure: 1 Vector__XXX
 SG_ GeneratorOilPressure : 0|8@1+ (3.45,0) [0|879] "kPa" Vector__XXX

BO_ 22 ExtendedCrankcaseBlowByPress: 1 Vector__XXX
 SG_ ExtendedCrankcaseBlowByPress : 0|8@1+ (0.029275,0) [0|7.4651] "kPa" Vector__XXX

BO_ 21 EngineECUTemperature: 1 Vector__XXX
 SG_ EngineECUTemperature : 0|8@1+ (2.5,-320) [-320|317.5] "°F" Vector__XXX

BO_ 20 ExtendedRangeEngineCoolantPress: 1 Vector__XXX
 SG_ ExtendedRangeEngineCoolantPress : 0|8@1+ (2,0) [0|510] "kPa" Vector__XXX

BO_ 19 ExtendedRangeEngineOilPressure: 1 Vector__XXX
 SG_ ExtendedRangeEngineOilPressure : 0|8@1+ (4,0) [0|1020] "kPa" Vector__XXX

BO_ 18 ExtendedRangeFuelPressure: 1 Vector__XXX
 SG_ ExtendedRangeFuelPressure : 0|8@1+ (4,0) [0|1020] "kPa" Vector__XXX

BO_ 17 EngineOilLevelRemoteReservoir: 1 Vector__XXX
 SG_ EngineOilLevelRemoteReservoir : 0|8@1+ (0.5,0) [0|127.5] "%" Vector__XXX

BO_ 16 SuctionSideFuelFilterDiffPress: 1 Vector__XXX
 SG_ SuctionSideFuelFilterDiffPress : 7|8@1+ (1.724,0) [0|439.5] "kPa" Vector__XXX

BO_ 15 FuelSupplyPumpInletPressure: 1 Vector__XXX
 SG_ FuelSupplyPumpInletPressure : 0|8@1+ (1.724,0) [0|439.5] "kPa" Vector__XXX

BO_ 14 EntryAssistMotorCurrent: 1 Vector__XXX
 SG_ EntryAssistMotorCurrent : 0|8@1+ (0.04,0) [0|10.2] "A" Vector__XXX

BO_ 13 EntryAssistPosition: 1 Vector__XXX
 SG_ EntryAssistPosition : 0|8@1+ (0.4,0) [0|102] "%" Vector__XXX

BO_ 256 RequestP2: 1 Vector__XXX
 SG_ RequestedPID : 0|8@1+ (1,0) [0|255] "" Vector__XXX

BO_ 12 BrakeStrokeStatus: 1 Vector__XXX
 SG_ BrakeStrokeStatus : 0|8@1+ (1,0) [0|255] "" Vector__XXX

BO_ 11 CargoSecurement: 1 Vector__XXX
 SG_ CargoSecurement : 0|8@1+ (1,0) [0|255] "" Vector__XXX

BO_ 10 AxleSliderStatus: 1 Vector__XXX
 SG_ AxleSliderStatus : 0|8@1+ (1,0) [0|255] "" Vector__XXX

BO_ 9 AxleLiftStatus: 1 Vector__XXX
 SG_ AxleLiftStatus : 0|8@1+ (1,0) [0|255] "" Vector__XXX

BO_ 8 BrakeSysAirPressLowWarningStatus: 1 Vector__XXX
 SG_ BrakeSysAirPressLowWarningStatus : 0|8@1+ (1,0) [0|255] "" Vector__XXX

BO_ 7 Axle2LiftAirPressure: 1 Vector__XXX
 SG_ Axle2LiftAirPressure : 0|8@1+ (4.14,0) [0|1055] "kPa" Vector__XXX

BO_ 0 RequestP1: 1 Vector__XXX
 SG_ RequestedPID : 0|8@1+ (1,0) [0|255] "" Vector__XXX

CM_ BO_ 510 "This PID allows transmission of information on the data bus in a nonstandard (per the protocol outlined in SAE J1587) but specific electronic module vendor's proprietary fashion.";
CM_ BO_ 509 "Used to identify the milepost as detected by a milepost sensor.";
CM_ BO_ 508 "Used to identify the Route, Run and Block information. This information may be entered into different devices at different authorities (fare collection, radio log, unit control panel, etc.).";
CM_ BO_ 507 "Used to obtain the driver identity.";
CM_ BO_ 506 "Used to display message on the vehicle control head display (driver console).";
CM_ BO_ 505 "Used to report key depression on the vehicle control head (driver console).";
CM_ BO_ 504 "Used to identify the message to be announced by the annunciator(s).";
CM_ BO_ 503 "Used to report stop level point of sale detail.";
CM_ BO_ 502 "Used to identify service, assignments, and fare preset detail of the fare collection unit.";
CM_ BO_ 501 "Used to identify the messages to be displayed on Destination, Head, or Next Stop signs.";
CM_ BO_ 500 "Status and configuration of the device used for intersection preemption.";
CM_ BO_ 499 "An object oriented driver interface unit can accept a PID command to display a particular object or form to the driver.";
CM_ BO_ 498 "Other network devices may require more than an acknowledgment from the DIU. They may require a series of keystrokes. However, there is a requirement that keystrokes be addressed to a specific MID so as not to confuse other network devices.";
CM_ BO_ 450 "Instructs the device connected to both the drivetrain data link and the transit link with which PIDs to repeat from the drivetrain link on the transit link.";
CM_ BO_ 449 "Used to request a device to change the specified transmission update period to a new interval for the given page 2 PID.";
CM_ BO_ 447 "Used to notify the transit link devices of real-time boarding and exiting passengers or to indicate the total number of passengers on vehicle referenced to the last transit stop.";
CM_ BO_ 446 "Temperature of cylinder head on the bank A (or left) side of the engine.";
CM_ BO_ 445 "Temperature of cylinder head on the bank B (or right) side of the engine.";
CM_ BO_ 444 "Measured electrical of the isolated battery #2.";
CM_ BO_ 443 "Identifies the current gage pressure (relative to atmosphere) that is configured uniquely per application. Not to be used in place of existing PIDs.";
CM_ BO_ 442 "Auxiliary sensor #2 temperature reading. Not to be used in place of existing PIDs.";
CM_ BO_ 441 "Auxiliary sensor #1 temperature reading. Not to be used in place of existing PIDs.";
CM_ BO_ 440 "Gage pressure of air is measured downstream on the compressor discharge side.";
CM_ BO_ 439 "Gage pressure of air is measured downstream on the compressor discharge side.";
CM_ BO_ 438 "The latest gage pressure reading of the trailer #2, tag #2, or push #2 group of tires, as opposed to the pressure in each tire.";
CM_ BO_ 437 "The tire pressure control system’s target gage pressure for the trailer #2, tag #2, or push #2 group of tires.";
CM_ BO_ 436 "Total number of decelerations whenever the vehicle is more than XYZ km/h/s (where XYZ is a calibrated threshold), since the last trip reset. A lengthy deceleration shall be counted as one sudden deceleration.";
CM_ BO_ 435 "Temperature of air inside vehicle container used to accommodate cargo.";
CM_ BO_ 434 "Auxiliary AC voltage measurement (RMS).";
CM_ BO_ 433 "Voltage measured at the positive terminal of the fuel shutoff solenoid.";
CM_ BO_ 432 "Voltage measured at the positive terminal of the starter motor.";
CM_ BO_ 431 "Voltage drop measured on the starter motor ground path.";
CM_ BO_ 430 "Voltage measured at the positive terminal of the starter solenoid.";
CM_ BO_ 429 "Current measured when the starter is engaged, before armature movement.";
CM_ BO_ 428 "Total resistance internal to the battery or batteries as defined by the equivalent circuit for a battery or batteries.";
CM_ BO_ 427 "Internal resistance change of the battery calculated by simultaneously measuring battery voltage and current over time.";
CM_ BO_ 426 "Voltage measured at the field windings.";
CM_ BO_ 425 "Frequency measurement.";
CM_ BO_ 424 "Auxiliary DC voltage measurement.";
CM_ BO_ 423 "Net flow of electrical current into/out of the battery or batteries.";
CM_ BO_ 422 "Auxiliary current measurement.";
CM_ BO_ 421 "Voltage measured at the negative cable of the vehicle alternator/generator.";
CM_ BO_ 420 "Starter current as averaged over the update period.";
CM_ BO_ 419 "Resistance of the starter circuit external to the battery.";
CM_ BO_ 418 "Temperature of transmission #2 lubricant.";
CM_ BO_ 417 "The PID will allow communication of the Gross Vehicle Weight";
CM_ BO_ 416 "Temperature of the air conditioner evaporator core or the temperature of the refrigerant in or near the evaporator core.";
CM_ SG_ 416 EvaporatorTemperature "Temperature of the air conditioner evaporator core or the temperature of the refrigerant in or near the evaporator core.";
CM_ BO_ 415 "Gage pressure of the refrigerant on the high pressure side of the air conditioning system.";
CM_ BO_ 414 "Gage pressure of the refrigerant on the low pressure (suction) side of the air conditioning system.";
CM_ BO_ 413 "Identifies Net Vehicle Weight Change from the time of last vehicle net weight zeroing.";
CM_ BO_ 412 "Current temperature of re-circulated engine exhaust gas.";
CM_ BO_ 411 "Current differential pressure across the engine EGR system.";
CM_ BO_ 410 "Indicated temperature of road surface over which vehicle is operating.";
CM_ BO_ 409 "Force of gravity imposed on the road surface by all the tires in an axle group.";
CM_ BO_ 408 "Allows for communication of the existing empty weight calibration measurement of an axle or axle group.";
CM_ BO_ 407 "Allows for communication of the existing full weight calibration measurement of an axle or axle group.";
CM_ BO_ 406 "Rotational velocity of blower motor rotor shaft.";
CM_ BO_ 384 "Used to request page 2 parameter data (PID) transmissions from a specified component on the data link.";
CM_ BO_ 383 "Scalar acceleration of vehicle. Negative numbers imply deceleration.";
CM_ BO_ 382 "Used to report silent alarm push button status.";
CM_ BO_ 381 "Used to indicate the proper or unauthorized use of the vehicle.";
CM_ BO_ 380 "Angle of deflection of an articulation turntable of an articulated transit vehicle. A right turn is indicated with a positive angle and a left turn is indicated with a negative angle.";
CM_ BO_ 379 "Used to report the open or closed status of a given door.";
CM_ BO_ 378 "Used to report alarms of the fare collection unit.";
CM_ BO_ 377 "The percent difference between the highest and the lowest compression values in an engine cycle as determined by monitoring the starter current.";
CM_ BO_ 376 "Vacuum reading on inlet side of the fuel pump (after the primary fuel filter).";
CM_ BO_ 375 "Pressure in fuel return line used to detect line blockage.";
CM_ BO_ 373 "Temperature of axle lubricant in center rear drive axle.";
CM_ BO_ 372 "Ratio of the actual remote accelerator position to the maximum remote accelerator position.";
CM_ BO_ 371 "Gage pressure of air in the pneumatic line that supplies air to the trailer pneumatic system, measured at the tractor. Typically controlled by the trailer supply valve. (Red Button)";
CM_ BO_ 370 "Gage pressure of air in the pneumatic line that controls the brake application of the trailer, measured at the tractor. (Service Brakes)";
CM_ BO_ 369 "Measures the distance from the back of the vehicle to the nearest object. The device sends a message only when the transmission is in reverse.";
CM_ BO_ 368 "Identifies the in-lane or out-of-lane status of the vehicle.";
CM_ BO_ 367 "Indicates the current status of the lane tracking system.";
CM_ BO_ 365 "Communicates the current zeroing status of the vehicle weighing system.";
CM_ BO_ 364 "Temperature of air on the discharge side of the mix door.";
CM_ BO_ 363 "The air pressure used to control the oil pressure of the hydraulic retarder.";
CM_ BO_ 362 "Ratio of current exhaust gas recirculation (EGR) valve position to the maximum EGR valve position. A value of 0% means no EGR.";
CM_ BO_ 259 "Used to acknowledge the warm or cold restart as requested by a component with administrative authority using PID 257 or 258.";
CM_ BO_ 258 "Components with administrative authority may request the warm restart of a selected component, usually to regain control of an errant component.";
CM_ BO_ 257 "Components with administrative authority may request the cold restart (powerup) of a selected component, usually to regain control of an errant component.";
CM_ BO_ 254 "This PID allows transmission of information on the data bus in a nonstandard (per the protocol outlined in SAE J1587) but specific electronic module vendor's proprietary fashion.";
CM_ BO_ 250 "Accumulated amount of fuel used during vehicle operation.";
CM_ BO_ 247 "Accumulated time of operation of engine.";
CM_ BO_ 249 "Accumulated number of revolutions of engine crankshaft during its operation.";
CM_ BO_ 248 "Accumulated time of operation of power takeoff device.";
CM_ BO_ 246 "Accumulated time of operation of vehicle.";
CM_ BO_ 245 "Accumulated distance travelled by vehicle during its operation.";
CM_ BO_ 244 "Distance traveled during all or part of a journey.";
CM_ BO_ 243 "Used to identify the Make, Model, and Serial Number of any component on the vehicle.";
CM_ BO_ 242 "Temperature at the surface of the tire sidewall.";
CM_ BO_ 241 "Pressure at which air is contained in cavity formed by tire and rim.";
CM_ BO_ 240 "Used to indicate that a change has occurred in the calibration data.";
CM_ BO_ 239 "The three-dimensional location of the vehicle.";
CM_ BO_ 238 "Any combination of the velocity, heading, and pitch, as calculated by the navigation device(s).";
CM_ BO_ 237 "Vehicle Identification Number (VIN) as assigned by the vehicle manufacturer.";
CM_ BO_ 236 "Accumulated amount of fuel used during vehicle operation while under idle conditions.";
CM_ BO_ 235 "Accumulated time of operation of the engine while under idle conditions.";
CM_ BO_ 234 "Software identification of an electronic module.";
CM_ BO_ 233 "Owner assigned unit number for power unit of a combination vehicle, straight truck, or transit vehicle.";
CM_ BO_ 232 "Equivalent to an RTCM-104 Type 9 differential GPS correction message.";
CM_ BO_ 231 "Fuel consumed during all or part of a journey.";
CM_ BO_ 230 "Accumulated amount of fuel used during vehicle operation while under idle conditions.";
CM_ BO_ 229 "Accumulated amount of fuel used during vehicle operation.";
CM_ BO_ 228 "The number of pulses per kilometer (pulses per mile) produced by the speed sensor.";
CM_ BO_ 225 "Used to provide an acknowledgment from the display device as requested by the electronic control system sending the information to be displayed, as instructed in status character 1 of the Text Message to Display message (PID 226).";
CM_ BO_ 226 "Used to provide the display device information to be displayed.";
CM_ BO_ 227 "Used to provide other electronic control systems in the truck with information regarding the capabilities of the display type.";
CM_ BO_ 224 "The encrypted security code data that is communicated between the vehicle security immobilizer control unit and the engine electronic control unit, immediately after the ignition key is turned on.";
CM_ BO_ 223 "Provides a mechanism to report the number of digital counts identifying one or more analog channels. Each channel is represented by 2 bytes and the number of channels reported can be determined by dividing the number of data characters (n) by 2.";
CM_ BO_ 222 "The information communicated via this message is always in response to an Anti-Theft Request message. This message is always sent by the component and never received by the component.";
CM_ BO_ 221 "The information communicated via this message are end-user based requests to a component. This message is always received by the component, and never sent by the component.";
CM_ BO_ 220 "Used to report the current engine torque configuration and all previous engine torque configurations available.";
CM_ BO_ 219 "Used to report the current country and state.";
CM_ BO_ 218 "Used to report when a vehicle crosses, or last crossed, a state line.";
CM_ BO_ 216 "Used to identify the fuel tank and fuel nozzle during fueling.";
CM_ BO_ 215 "Temperature of the brake shoe/brake pad/brake drum.";
CM_ BO_ 214 "Indicated velocity of the individual wheels.";
CM_ BO_ 213 "Measurement of vibration level at wheel end assembly.";
CM_ BO_ 212 "Communicates the tire pressure target(s) by sequence number. (Not position specific)";
CM_ BO_ 211 "PID to communicate the tire pressure(s) by sequence number. (Not position specific)";
CM_ BO_ 210 "Communicates the tire temperature(s) by sequence number. (Not position specific)";
CM_ BO_ 209 "To be used to send trailer ABS control and warning lamp status. A tractor mounted ECU may broadcast this message and report the ABS status of all trailers at once.";
CM_ BO_ 199 "Used to request the traction control unit to temporarily disable the traction control function during vehicle testing.";
CM_ BO_ 196 "Used to acknowledge the clearing of diagnostic codes or supply additional information about a diagnostic code as requested by PID 195.";
CM_ BO_ 194 "Used to notify other components on the data link of the diagnostic condition of the transmitting electronic component. The parameter contains a list of diagnostic codes and occurrence counts.";
CM_ BO_ 192 "Used to transmit parameters that are longer than what is limited by SAE J1708. A specified parameter can be broken into sections with each section being transmitted in a different message.";
CM_ BO_ 191 "Rotational velocity of shaft transferring force from transmission to driveshaft.";
CM_ BO_ 189 "The maximum governed rotational velocity of the engine crankshaft under full load conditions.";
CM_ BO_ 188 "Minimum nontransient rotational velocity of crankshaft while engine is supplying power to itself and its attendant support systems.";
CM_ BO_ 187 "Rotational velocity selected by operator for device used to transmit engine power to auxiliary equipment.";
CM_ BO_ 186 "Rotational velocity of device used to transmit engine power to auxiliary equipment.";
CM_ BO_ 185 "Average of instantaneous fuel economy for that segment of vehicle operation of interest.";
CM_ BO_ 184 "Current fuel economy at current vehicle velocity.";
CM_ BO_ 183 "Amount of fuel consumed by engine per unit of time.";
CM_ BO_ 182 "Fuel consumed during all or part of a journey.";
CM_ BO_ 181 "The force of gravity of freight carried.";
CM_ BO_ 180 "Total force of gravity of freight-carrying vehicle designed to be pulled by truck, including the
weight of the contents.";
CM_ BO_ 179 "Force of gravity imposed on the road surface by all the tires on each individual rear
axle.";
CM_ BO_ 178 "Total force of gravity imposed by the front tires on the road surface.";
CM_ BO_ 177 "Temperature of transmission lubricant.";
CM_ BO_ 176 "Temperature of turbocharger lubricant.";
CM_ BO_ 175 "Temperature of engine lubricant.";
CM_ BO_ 174 "Temperature of fuel entering injectors.";
CM_ BO_ 173 "Temperature of combustion byproducts leaving the engine.";
CM_ BO_ 172 "Temperature of air entering vehicle air induction system.";
CM_ BO_ 171 "Temperature of air surrounding vehicle.";
CM_ BO_ 170 "Temperature of air inside the part of the vehicle that encloses the driver and vehicle operating controls.";
CM_ BO_ 169 "Temperature of air inside vehicle container used to accommodate cargo.";
CM_ BO_ 168 "Measured electrical potential of the battery.";
CM_ BO_ 167 "Measured electrical potential of the alternator.";
CM_ BO_ 166 "Net brake power that the engine will deliver continuously, specified for a given
application at a rated speed.";
CM_ BO_ 165 "Present compass bearing of vehicle";
CM_ BO_ 164 "The gage pressure of the hydraulic accumulator that powers fuel injection.";
CM_ BO_ 163 "Range currently being commanded by the transmission control system. Characters may include P, R2, R1, R, N, D, D1, D2, L, L1, L2, 1, 2, 3, ... If the first character is a control character, refer to the manufacturer’s application document for definition.";
CM_ BO_ 162 "Range selected by operator. Characters may include P, R2, R1, R, N, D, D1, D2, L, L1, L2, 1, 2, 3, ... If the first character is a control character, refer to the manufacturer’s application document for definition.";
CM_ BO_ 159 "Gas supply pressure (gage) to fuel metering device.";
CM_ BO_ 158 "Electrical potential measured at the input of the electronic control unit supplied through a switching device.";
CM_ BO_ 157 "The gage pressure of fuel in the metering rail as delivered from the supply pump to the injector metering inlet.";
CM_ BO_ 156 "The gage pressure of fuel in the timing rail as delivered from the supply pump to the injector timing inlet.";
CM_ BO_ 155 "Identifies the current status of auxiliary input and output functions that are configured uniquely per application. Not to be used in place of existing PIDs.";
CM_ BO_ 154 "Identifies the current status of auxiliary input and output functions that are configured uniquely per application. Not to be used in place of existing PIDs.";
CM_ BO_ 153 "Gage air pressure inside engine crankcase.";
CM_ BO_ 152 "The number of times the ECU has completed a successful power-up sequence.";
CM_ BO_ 151 "Identifies the current state of the ATC control functions, signals, lamp, and switch.";
CM_ BO_ 149 "Amount of fuel consumed by engine per unit of time.";
CM_ BO_ 148 "Current fuel economy at current vehicle velocity.";
CM_ BO_ 147 "Average of instantaneous fuel economy for that segment of vehicle operation of interest.";
CM_ BO_ 146 "The latest gage pressure reading of the steer group of tires, as opposed to
the pressure in each tire.";
CM_ BO_ 145 "The latest gage pressure reading of the drive group of tires, as opposed to
the pressure in each tire.";
CM_ BO_ 198 "The CDP is used for the actual transfer of the segmented user data.";
CM_ SG_ 198 SegmentID "Segment Identification";
CM_ SG_ 198 ReceiverMID "MID of destination device";
CM_ SG_ 197 RSDRequestAssignment "Data request assignments";
CM_ SG_ 197 CTSNextSegment "The next segment to be transmitted";
CM_ SG_ 197 CTSNumberOfSegments "Number of segments the receiver is ready to accept";
CM_ SG_ 197 RTSNumberOfSegments "Number of segments";
CM_ SG_ 197 ReceiverMID "MID of destination device";
CM_ SG_ 197 CMCommand "Connection Management Command";
CM_ BO_ 144 "The latest gage pressure reading of the trailer #1, tag #1, or push #1 group of tires, as opposed to the pressure in each tire.";
CM_ BO_ 143 "The tire pressure control system's target gage pressure for the steer group of tires.";
CM_ BO_ 142 "The tire pressure control system's target gage pressure for the drive group of tires.";
CM_ BO_ 141 "The tire pressure control system's target gage pressure for the trailer #1, tag #1, or push #1 group of tires.";
CM_ BO_ 140 "Identifies the current state of the solenoids used to implement a tire pressure control system in its pneumatic control unit.";
CM_ BO_ 139 "Indicates the functional mode of each channel.";
CM_ BO_ 138 "Identifies the current absolute pressure that is configured uniquely per application.";
CM_ BO_ 137 "Identifies the current gage pressure that is configured uniquely per application.";
CM_ BO_ 136 "Identifies the current vacuum pressure that is configured uniquely per application.";
CM_ BO_ 135 "Absolute pressure of fuel in system delivered from the supply pump.";
CM_ BO_ 134 "Identifies the current state of the device that signals individual wheel speeds to the ABS Electronic control Unit.";
CM_ BO_ 133 "Continuous averaging of gallons of fuel per hour per segment of engine operation.";
CM_ BO_ 132 "Mass air flow measured at the fresh air intake.";
CM_ BO_ 131 "Gage pressure of exhaust gas measured at the exhaust manifold.";
CM_ BO_ 130 "Instantaneous fuel economy of the engine, typically for offhighwayequipment.";
CM_ BO_ 129 "The gage pressure of fuel in the metering rail #2 as delivered from the supply pump to the injector metering inlet.";
CM_ BO_ 128 "Used to request parameter data transmissions from a specified component on the data link.";
CM_ BO_ 127 "Gage pressure of lubrication fluid in transmission, measured after pump.";
CM_ BO_ 126 "Change in transmission fluid pressure, measured after the filter, due to accumulation of solid or semisolid material on or in the filter.";
CM_ BO_ 125 "Amount of current volume of transmission sump oil compared to recommended volume.";
CM_ BO_ 124 "Ratio of volume of transmission sump oil to recommended volume.";
CM_ BO_ 123 "Gage pressure of oil within a wet clutch.";
CM_ BO_ 122 "Ratio of current engine retard force to maximum retard force available.";
CM_ BO_ 121 "State of device used to convert engine power to vehicle retarding force.";
CM_ BO_ 120 "The temperature of the oil in the hydraulic retarder system.";
CM_ BO_ 119 "Gage pressure of oil in hydraulic retarder system.";
CM_ BO_ 118 "Gage pressure of air in the secondary or service side, of the air brake system.";
CM_ BO_ 117 "Gage pressure of air in the primary, or supply side, of the air brake system.";
CM_ BO_ 116 "Gage pressure of compressed air or fluid.";
CM_ BO_ 115 "Measure of electrical flow from the alternator.";
CM_ BO_ 114 "Net flow of electrical current into/out of the battery or batteries.";
CM_ BO_ 113 "The difference between full load rated engine speed and maximum no-load governed engine speed.";
CM_ BO_ 112 "Change in coolant pressure, measured after the filter, due to accumulation of solid or semisolid matter on or in the filter.";
CM_ BO_ 111 "Ratio of volume of liquid found in engine cooling system to total cooling system volume.";
CM_ BO_ 109 "The gage pressure of liquid found in engine cooling system.";
CM_ BO_ 108 "Absolute air pressure of the atmosphere.";
CM_ BO_ 107 "Change in engine air system pressure, measured after the filter, due to accumulation of solid foreign matter on or in the filter.";
CM_ BO_ 106 "Absolute air pressure at inlet to intake manifold or air box.";
CM_ BO_ 105 "Temperature of precombustion air found in intake manifold of engine air supply system.";
CM_ BO_ 102 "Gage pressure of air measured downstream on the compressor discharge side of the turbocharger.";
CM_ BO_ 101 "Gage air pressure inside engine crankcase.";
CM_ BO_ 99 "Change in engine oil pressure, measured after filter, due to accumulation of solid or semisolid material on or in the filter.";
CM_ BO_ 97 "Indication of presence of unacceptable amount of water in fuel system.";
CM_ BO_ 96 "Ratio of volume of fuel to the total volume of the primary fuel storage container.";
CM_ BO_ 95 "Change in fuel delivery pressure, measured across the filter, due to accumulation of solid or semisolid matter on the filter element.";
CM_ BO_ 94 "Gage pressure of fuel in system as delivered from supply pump to the injection pump.";
CM_ BO_ 93 "Amount of torque available at the engine flywheel.";
CM_ BO_ 92 "Ratio of current output torque to maximum torque available at the current engine speed.";
CM_ BO_ 91 "Ratio of actual accelerator pedal position to maximum pedal position.";
CM_ BO_ 90 "Temperature of lubricant in device used to transmit engine power to auxiliary equipment.";
CM_ BO_ 86 "Value of set velocity of velocity control system.";
CM_ BO_ 83 "State of the system used to limit maximum vehicle velocity.";
CM_ BO_ 82 "Gage pressure of air in an engine starting system that utilizes compressed air to provide the force required to rotate the crankshaft.";
CM_ BO_ 81 "Exhaust back pressure as a result of particle accumulation on filter media placed in the exhaust stream.";
CM_ BO_ 80 "Ratio of volume of liquid to total container volume of fluid reservoir in windshield wash system.";
CM_ BO_ 79 "Indicated temperature of road surface over which vehicle is operating.";
CM_ BO_ 78 "Temperature of axle lubricant in rear rear drive axle.";
CM_ BO_ 77 "Temperature of axle lubricant in forward rear drive axle.";
CM_ BO_ 76 "Gage pressure of air in system that utilizes compressed air to provide force between axle and frame.";
CM_ BO_ 75 "Temperature of lubricant in steering axle.";
CM_ BO_ 74 "Maximum vehicle velocity allowed.";
CM_ BO_ 73 "Gage pressure of auxiliary water pump driven as a PTO device.";
CM_ BO_ 72 "Relative position of the blower bypass valve.";
CM_ BO_ 69 "Identifies the commanded range for a two speed axle.";
CM_ BO_ 68 "Ratio of current output torque allowed to the maximum torque available at the current engine speed.";
CM_ BO_ 67 "Identifies the current state of the switches used to request an upshift or downshift.";
CM_ BO_ 66 "Identifies the current state of the components that enable the vehicle to start and operate properly.";
CM_ BO_ 65 "Identifies the current state of the brake switches.";
CM_ BO_ 64 "Identifies the current state of the switches that indicate the direction of the transmission.";
CM_ BO_ 63 "Identifies the current status of the actuators used to control the functions of the auxiliary unit.";
CM_ BO_ 62 "Identifies the current state of the device that inhibits use of the engine retarder.";
CM_ BO_ 61 "Identifies the current status of the actuators that control the parking brakes.";
CM_ BO_ 60 "The current position of the shift finger in the rail direction.";
CM_ BO_ 59 "The current position of the shift finger in the gear direction.";
CM_ BO_ 58 "Identifies the current status of the actuators that move the shift finger.";
CM_ BO_ 57 "Identifies the current status of the actuators that control the clutch.";
CM_ BO_ 56 "Identifies the current status of the switches that represent range position.";
CM_ BO_ 55 "dentifies the current status of the switches that represent the position of the shift finger.";
CM_ BO_ 54 "current modulation value for the air supply to the synchronizer brake.";
CM_ BO_ 53 "current modulation value for the air supply to the synchronizer clutch.";
CM_ BO_ 51 "The position of the valve used to regulate the supply of a fluid.";
CM_ BO_ 50 "Used to request the air conditioner (A/C) compressor clutch unit to temporarily disable the clutch.";
CM_ BO_ 49 "Identifies the current state of the ABS control functions, lamp and switch.";
CM_ BO_ 48 "Absolute air pressure of the atmosphere.";
CM_ BO_ 47 "Identifies the current state of vehicle retarders.";
CM_ BO_ 45 "Identifies the current state of the inlet air heaters.";
CM_ BO_ 42 "Identifies the current state of an open/closed type switch used to determine if adequate pressure exists for system implementation.";
CM_ BO_ 41 "Identifies the current state of the switch contacts used in the cruise control system.";
CM_ BO_ 40 "Identifies the current state of the switch contacts used in the engine retarder system.";
CM_ BO_ 39 "Identifies the interval at which the system will check the tire pressures.";
CM_ BO_ 38 "Ratio of volume of fuel to the total volume of the second fuel storage container.";
CM_ BO_ 37 "Pressure of the air in the tank supplying the automatically shifting transmission.";
CM_ BO_ 36 "The current wear condition of the clutch plates.";
CM_ BO_ 35 "Identifies the current status of the actuators that move the shift finger.";
CM_ SG_ 35 GearActuator3Status "Gear actuator #3 status";
CM_ SG_ 35 RailActuator3Status "Rail actuator #3 status";
CM_ BO_ 34 "Identifies the current status of the actuators used to control the functions of the clutch cylinder.";
CM_ SG_ 34 CoarseEngagementActuatorStatus "Coarse engagement actuator status";
CM_ SG_ 34 FineEngagementActuatorStatus "Fine engagement actuator status";
CM_ SG_ 34 CoarseDisengageActuatorStatus "Coarse disengagement actuator status";
CM_ SG_ 34 FineDisengagementActuatorStatus "Fine disengagement actuator status";
CM_ BO_ 33 "The current position of the clutch engagement cylinder.";
CM_ BO_ 32 "The current position of the splitter cylinder.";
CM_ BO_ 150 "Identifies the current state of the input and output functions used to control the engagement of PTO devices.";
CM_ BO_ 195 "Used to request additional information about a given diagnostic code or clear its count.";
CM_ SG_ 195 SIDorPID "SID or PID of a standard diagnostic code.";
CM_ SG_ 195 TargetMID "MID of device to which request is directed.";
CM_ BO_ 193 "Used to notify other components on the data link of the diagnostic condition of the transmitting electronic component.";
CM_ SG_ 190 EngineSpeed "Rotational velocity of crankshaft.";
CM_ SG_ 161 InputShaftSpeed "Rotational velocity of the primary shaft transferring power into the transmission.";
CM_ SG_ 160 MainShaftSpeed "Rotational velocity of the first intermediate shaft of the transmission.";
CM_ SG_ 110 EngineCoolantTemperature "The temperature of liquid found in engine cooling system.";
CM_ SG_ 104 TurboOilPressure "Gage pressure of oil in turbocharger lubrication system.";
CM_ SG_ 103 TurboSpeed "Rotational velocity of rotor in turbocharger.";
CM_ SG_ 100 EngineOilPressure "Gage pressure of oil in engine lubrication system as provided by oil pump.";
CM_ SG_ 98 EngineOilLevel "Ratio of current volume of engine sump oil to maximum required volume.";
CM_ SG_ 52 EngineIntercoolerTemperature "The temperature of liquid found in the engine intercooler.";
CM_ BO_ 43 "Identifies the current state of the contacts within the ignition switch.";
CM_ SG_ 31 TransmissionRangePosition "The current position of the range cylinder.";
CM_ SG_ 30 CrankcaseBlowByPressure "Crankcase blow-by pressure as measured through a tube with a venturi.";
CM_ SG_ 29 PercentAcceleratorPosition3 "Ratio of actual accelerator position to maximum accelerator position.";
CM_ SG_ 28 PercentAcceleratorPosition3 "Ratio of actual accelerator position to maximum accelerator position.";
CM_ SG_ 27 PercentExhaustGasRecircValve1Pos "Position—Ratio of current exhaust gas recirculation (EGR) valve position to the maximum EGR valve position.";
CM_ SG_ 26 EstimatedPercentFanSpeed "Fan speed as a ratio of the actual fan drive to the fully engaged fan drive.";
CM_ SG_ 24 GeneratorCoolantTemperature "The temperature of liquid found in an auxiliary generator engine cooling system.";
CM_ SG_ 23 GeneratorOilPressure "Gage pressure of oil in an auxiliary generator engine lubrication system.";
CM_ SG_ 22 ExtendedCrankcaseBlowByPress "Crankcase blow-by pressure as measured through a tube with a venturi.";
CM_ SG_ 21 EngineECUTemperature "Internal air temperature of the engine ECU.";
CM_ SG_ 20 ExtendedRangeEngineCoolantPress "Pressure—Gage pressure of liquid found in the engine cooling system.";
CM_ SG_ 19 ExtendedRangeEngineOilPressure "Gage pressure of oil in the engine lubrication system as provided by the oil pump.";
CM_ SG_ 18 ExtendedRangeFuelPressure "Gage pressure of fuel in system as delivered from the supply pump to the injection pump.";
CM_ SG_ 17 EngineOilLevelRemoteReservoir "Ratio of current volume of engine oil in remote reservoir to maximum recommended volume.";
CM_ SG_ 16 SuctionSideFuelFilterDiffPress "Differential pressure measured across the fuel filter between the fuel tank and the supply pump.";
CM_ SG_ 15 FuelSupplyPumpInletPressure "Absolute pressure of fuel at fuel supply pump inlet.";
CM_ SG_ 14 EntryAssistMotorCurrent "Current measured of the entry assist motor.";
CM_ SG_ 13 EntryAssistPosition "Position of the steps, chair lift, etc.";
CM_ SG_ 256 RequestedPID "Used to request parameter data transmission from other components on the data link.";
CM_ SG_ 12 BrakeStrokeStatus "Identifies the current state of the vehicle foundation brakes.";
CM_ SG_ 11 CargoSecurement "Used to monitor hold down device to include chain, cable or other device that may be
used to secure a load.";
CM_ SG_ 10 AxleSliderStatus "Identifies the current status of a sliding axle suspension.";
CM_ SG_ 9 AxleLiftStatus "Identifies the current status or position of a lift axle.";
CM_ SG_ 8 BrakeSysAirPressLowWarningStatus "Identifies the current status of the low pressure
warning switch that monitors the air brake system.";
CM_ SG_ 7 Axle2LiftAirPressure "Gage Pressure of air in system that utilizes compressed air to provide force
between axle and frame.";
CM_ SG_ 0 RequestedPID "Used to request parameter data transmission from other components on the data link.";
BA_DEF_  "J1587ProprietaryFormat" ENUM  "undefined","Volvo";
BA_DEF_  "BusType" STRING ;
BA_DEF_ BO_  "J1587CycleTime" INT 0 100000;
BA_DEF_ BU_  "NmStationAddress" INT 0 255;
BA_DEF_ BO_  "J1708Priority" INT 1 8;
BA_DEF_DEF_  "J1587ProprietaryFormat" "undefined";
BA_DEF_DEF_  "BusType" "";
BA_DEF_DEF_  "J1587CycleTime" 0;
BA_DEF_DEF_  "NmStationAddress" 0;
BA_DEF_DEF_  "J1708Priority" 6;
BA_ "BusType" "J1708";
BA_ "NmStationAddress" BU_ SafetyRestraintSystem2 254;
BA_ "NmStationAddress" BU_ BrakeStrokeAlertMonitorTractor 253;
BA_ "NmStationAddress" BU_ RearDoorStatusUnit 194;
BA_ "NmStationAddress" BU_ SteeringColumnUnit 250;
BA_ "NmStationAddress" BU_ BodyController 249;
BA_ "NmStationAddress" BU_ ForwardRoadImageProcessor 248;
BA_ "NmStationAddress" BU_ BrakesTrailer5 247;
BA_ "NmStationAddress" BU_ BrakesTrailer4 246;
BA_ "NmStationAddress" BU_ WeighingSystemDisplay 245;
BA_ "NmStationAddress" BU_ Door6StatusUnit 244;
BA_ "NmStationAddress" BU_ Door5StatusUnit 243;
BA_ "NmStationAddress" BU_ Door4StatusUnit 242;
BA_ "NmStationAddress" BU_ FuelTankMonitor 241;
BA_ "NmStationAddress" BU_ PassengerCounterUnit3 240;
BA_ "NmStationAddress" BU_ PassengerCounterUnit2 239;
BA_ "NmStationAddress" BU_ IdleAdjustSystem 238;
BA_ "NmStationAddress" BU_ EntryAssistControl2 237;
BA_ "NmStationAddress" BU_ EntryAssistControl1 236;
BA_ "NmStationAddress" BU_ EngineOilControlSystem 235;
BA_ "NmStationAddress" BU_ InstrumentCluster2 234;
BA_ "NmStationAddress" BU_ IntersectionPreemptionEmitter 233;
BA_ "NmStationAddress" BU_ SafetyRestraintSystem 232;
BA_ "NmStationAddress" BU_ CommUnitCellular 231;
BA_ "NmStationAddress" BU_ WeightingSystemAxleGroup6 230;
BA_ "NmStationAddress" BU_ WeightingSystemAxleGroup5 229;
BA_ "NmStationAddress" BU_ WeightingSystemAxleGroup4 228;
BA_ "NmStationAddress" BU_ WeightingSystemAxleGroup3 227;
BA_ "NmStationAddress" BU_ WeightingSystemAxleGroup2 226;
BA_ "NmStationAddress" BU_ WeightingSystemAxleGroup1 225;
BA_ "NmStationAddress" BU_ ParkingHeater 224;
BA_ "NmStationAddress" BU_ TransmissiionShiftConsolePrimary 223;
BA_ "NmStationAddress" BU_ DrivelineRetarder 222;
BA_ "NmStationAddress" BU_ DriverInformationCenter2 221;
BA_ "NmStationAddress" BU_ Tachograph 220;
BA_ "NmStationAddress" BU_ CollisionAvoidanceSystems 219;
BA_ "NmStationAddress" BU_ Bridge_TrailerMounted 218;
BA_ "NmStationAddress" BU_ Bridge_TractorMounted 217;
BA_ "NmStationAddress" BU_ LightingControlAdministratorUnit 216;
BA_ "NmStationAddress" BU_ SurveillanceMircrophone 215;
BA_ "NmStationAddress" BU_ SilentAlarmUnit 214;
BA_ "NmStationAddress" BU_ VehicleControlHeadTouchScreen 213;
BA_ "NmStationAddress" BU_ MobileDataTerminal 212;
BA_ "NmStationAddress" BU_ SmartCardTerminal 211;
BA_ "NmStationAddress" BU_ BusChassisIdentificationUnit 210;
BA_ "NmStationAddress" BU_ VehicleTurntable 209;
BA_ "NmStationAddress" BU_ MaintenancePrinter 208;
BA_ "NmStationAddress" BU_ BridgeFromDrivetrainLink 207;
BA_ "NmStationAddress" BU_ BaseUnit 206;
BA_ "NmStationAddress" BU_ VehicleProximityLeftSide 205;
BA_ "NmStationAddress" BU_ VehicleProximityRightSide 204;
BA_ "NmStationAddress" BU_ MobileDataTerminalUnit 203;
BA_ "NmStationAddress" BU_ HighSpeedCommUnit 202;
BA_ "NmStationAddress" BU_ VehicleStatusPointsMonitorUnit 201;
BA_ "NmStationAddress" BU_ RouteAdherenceUnit 199;
BA_ "NmStationAddress" BU_ EnvMonitorUnit 200;
BA_ "NmStationAddress" BU_ ScheduleAdherenceUnit 198;
BA_ "NmStationAddress" BU_ PassengerCounterUnit1 197;
BA_ "NmStationAddress" BU_ FareCollectionUnit 196;
BA_ "NmStationAddress" BU_ AnnunciatorUnit 195;
BA_ "NmStationAddress" BU_ MiddleDoorStatusUnit 193;
BA_ "NmStationAddress" BU_ FrontDoorStatusUnit 192;
BA_ "NmStationAddress" BU_ VehicleLocationUnit 191;
BA_ "NmStationAddress" BU_ RefrigerantManagement 190;
BA_ "NmStationAddress" BU_ VehicleHeadSigns 189;
BA_ "NmStationAddress" BU_ VehicleLogicControlUnit 188;
BA_ "NmStationAddress" BU_ VehicleControlHeadUnit 187;
BA_ "NmStationAddress" BU_ TiresControlUnit 186;
BA_ "NmStationAddress" BU_ PneumaticSystemController 185;
BA_ "NmStationAddress" BU_ RearAxleSteeringController 184;
BA_ "NmStationAddress" BU_ Engine3 183;
BA_ "NmStationAddress" BU_ OffBoardProgrammingStation 182;
BA_ "NmStationAddress" BU_ CommUnitSatellite 181;
BA_ "NmStationAddress" BU_ OffBoardDiagnostics2 180;
BA_ "NmStationAddress" BU_ DataLoggingComputer 179;
BA_ "NmStationAddress" BU_ VehicleSensorsToDataConverter 178;
BA_ "NmStationAddress" BU_ ParticulateTrapSystem 177;
BA_ "NmStationAddress" BU_ TransmAddHybridCtrlModule 176;
BA_ "NmStationAddress" BU_ Engine2 175;
BA_ "NmStationAddress" BU_ CrankingSystem 174;
BA_ "NmStationAddress" BU_ EngineRetarder 173;
BA_ "NmStationAddress" BU_ OffBoardDiagnostics1 172;
BA_ "NmStationAddress" BU_ DriverInformationCenter 171;
BA_ "NmStationAddress" BU_ Electrical 170;
BA_ "NmStationAddress" BU_ TiresTrailer3 169;
BA_ "NmStationAddress" BU_ TiresTrailer2 168;
BA_ "NmStationAddress" BU_ TiresTrailer1 167;
BA_ "NmStationAddress" BU_ TiresPowerUnit 166;
BA_ "NmStationAddress" BU_ CommonUnitGround 165;
BA_ "NmStationAddress" BU_ Multiplex 164;
BA_ "NmStationAddress" BU_ VehicleSecurity 163;
BA_ "NmStationAddress" BU_ VehicleNavigationUnit 162;
BA_ "NmStationAddress" BU_ AerodynamicControlUnit 161;
BA_ "NmStationAddress" BU_ ProximityDetectorRear 160;
BA_ "NmStationAddress" BU_ ProximityDetectorFront 159;
BA_ "NmStationAddress" BU_ ElectricalChargingSystem 158;
BA_ "NmStationAddress" BU_ ParkBrakeController 157;
BA_ "NmStationAddress" BU_ DiagSysTrailer2_obsolete 156;
BA_ "NmStationAddress" BU_ DiagSysTrailer1 155;
BA_ "NmStationAddress" BU_ DiagSysPowerUnit 154;
BA_ "NmStationAddress" BU_ SuspensionTrailer3_obsolete 153;
BA_ "NmStationAddress" BU_ SuspensionTrailer2_obsolete 152;
BA_ "NmStationAddress" BU_ SuspensionTrailer1 151;
BA_ "NmStationAddress" BU_ SuspensionPowerUnit 150;
BA_ "NmStationAddress" BU_ CargoHeatingTrailer3_obsolete 149;
BA_ "NmStationAddress" BU_ CargoHeatingTrailer2_obsolete 148;
BA_ "NmStationAddress" BU_ CargoHeatingTrailer 147;
BA_ "NmStationAddress" BU_ CabClimateControl 146;
BA_ "NmStationAddress" BU_ RoadSpeedIndicator 145;
BA_ "NmStationAddress" BU_ CruiseControl 144;
BA_ "NmStationAddress" BU_ FuelSystem 143;
BA_ "NmStationAddress" BU_ VehicleManagementSystem 142;
BA_ "NmStationAddress" BU_ TripRecorder 141;
BA_ "NmStationAddress" BU_ AxleTrailer2_obsolete 134;
BA_ "NmStationAddress" BU_ BrakesTrailer3 139;
BA_ "NmStationAddress" BU_ BrakesTrailer2 138;
BA_ "NmStationAddress" BU_ BrakesTrailer1 137;
BA_ "NmStationAddress" BU_ BrakePowerUnit 136;
BA_ "NmStationAddress" BU_ AxleTrailer3_obsolete 135;
BA_ "NmStationAddress" BU_ AxleTrailer1 133;
BA_ "NmStationAddress" BU_ AxlePowerUnit 132;
BA_ "NmStationAddress" BU_ PowerTakeoff 131;
BA_ "NmStationAddress" BU_ InstrumentCluster 140;
BA_ "NmStationAddress" BU_ Transmission 130;
BA_ "NmStationAddress" BU_ TurboCharger 129;
BA_ "NmStationAddress" BU_ Engine1 128;
BA_ "J1708Priority" BO_ 509 8;
BA_ "J1708Priority" BO_ 508 8;
BA_ "J1708Priority" BO_ 507 8;
BA_ "J1708Priority" BO_ 506 7;
BA_ "J1708Priority" BO_ 505 7;
BA_ "J1708Priority" BO_ 500 8;
BA_ "J1708Priority" BO_ 450 8;
BA_ "J1708Priority" BO_ 449 8;
BA_ "J1708Priority" BO_ 447 8;
BA_ "J1708Priority" BO_ 446 4;
BA_ "J1587CycleTime" BO_ 446 1;
BA_ "J1708Priority" BO_ 445 4;
BA_ "J1587CycleTime" BO_ 445 1;
BA_ "J1708Priority" BO_ 444 5;
BA_ "J1587CycleTime" BO_ 444 1000;
BA_ "J1708Priority" BO_ 443 8;
BA_ "J1708Priority" BO_ 442 4;
BA_ "J1587CycleTime" BO_ 442 1000;
BA_ "J1708Priority" BO_ 441 4;
BA_ "J1587CycleTime" BO_ 441 1000;
BA_ "J1708Priority" BO_ 440 4;
BA_ "J1587CycleTime" BO_ 440 1000;
BA_ "J1708Priority" BO_ 439 4;
BA_ "J1587CycleTime" BO_ 439 1000;
BA_ "J1708Priority" BO_ 438 8;
BA_ "J1708Priority" BO_ 437 8;
BA_ "J1708Priority" BO_ 436 8;
BA_ "J1708Priority" BO_ 435 8;
BA_ "J1708Priority" BO_ 434 7;
BA_ "J1708Priority" BO_ 433 7;
BA_ "J1708Priority" BO_ 432 7;
BA_ "J1708Priority" BO_ 431 7;
BA_ "J1708Priority" BO_ 430 7;
BA_ "J1708Priority" BO_ 429 7;
BA_ "J1708Priority" BO_ 428 7;
BA_ "J1708Priority" BO_ 427 7;
BA_ "J1708Priority" BO_ 426 7;
BA_ "J1708Priority" BO_ 425 7;
BA_ "J1708Priority" BO_ 424 7;
BA_ "J1708Priority" BO_ 423 7;
BA_ "J1708Priority" BO_ 422 7;
BA_ "J1708Priority" BO_ 421 7;
BA_ "J1708Priority" BO_ 420 7;
BA_ "J1708Priority" BO_ 419 7;
BA_ "J1708Priority" BO_ 418 4;
BA_ "J1587CycleTime" BO_ 418 1000;
BA_ "J1708Priority" BO_ 417 8;
BA_ "J1708Priority" BO_ 416 8;
BA_ "J1708Priority" BO_ 415 8;
BA_ "J1708Priority" BO_ 414 8;
BA_ "J1708Priority" BO_ 413 8;
BA_ "J1708Priority" BO_ 412 5;
BA_ "J1587CycleTime" BO_ 412 1000;
BA_ "J1708Priority" BO_ 411 4;
BA_ "J1587CycleTime" BO_ 411 1000;
BA_ "J1708Priority" BO_ 410 5;
BA_ "J1587CycleTime" BO_ 410 1000;
BA_ "J1708Priority" BO_ 409 8;
BA_ "J1708Priority" BO_ 408 8;
BA_ "J1708Priority" BO_ 407 8;
BA_ "J1708Priority" BO_ 406 7;
BA_ "J1708Priority" BO_ 384 8;
BA_ "J1708Priority" BO_ 382 7;
BA_ "J1708Priority" BO_ 381 7;
BA_ "J1708Priority" BO_ 380 8;
BA_ "J1587CycleTime" BO_ 380 1000;
BA_ "J1708Priority" BO_ 379 7;
BA_ "J1708Priority" BO_ 377 7;
BA_ "J1708Priority" BO_ 376 7;
BA_ "J1708Priority" BO_ 375 7;
BA_ "J1708Priority" BO_ 374 7;
BA_ "J1708Priority" BO_ 373 5;
BA_ "J1587CycleTime" BO_ 373 1000;
BA_ "J1708Priority" BO_ 372 4;
BA_ "J1587CycleTime" BO_ 372 100;
BA_ "J1708Priority" BO_ 371 5;
BA_ "J1587CycleTime" BO_ 371 1000;
BA_ "J1708Priority" BO_ 370 5;
BA_ "J1587CycleTime" BO_ 370 1000;
BA_ "J1708Priority" BO_ 369 2;
BA_ "J1587CycleTime" BO_ 369 100;
BA_ "J1708Priority" BO_ 368 2;
BA_ "J1587CycleTime" BO_ 368 100;
BA_ "J1587CycleTime" BO_ 367 500;
BA_ "J1587CycleTime" BO_ 366 10000;
BA_ "J1708Priority" BO_ 365 8;
BA_ "J1708Priority" BO_ 364 7;
BA_ "J1708Priority" BO_ 363 5;
BA_ "J1587CycleTime" BO_ 363 1000;
BA_ "J1708Priority" BO_ 362 4;
BA_ "J1587CycleTime" BO_ 362 1000;
BA_ "J1708Priority" BO_ 259 3;
BA_ "J1708Priority" BO_ 258 3;
BA_ "J1708Priority" BO_ 257 3;
BA_ "J1708Priority" BO_ 253 7;
BA_ "J1587CycleTime" BO_ 253 10000;
BA_ "J1708Priority" BO_ 251 8;
BA_ "J1708Priority" BO_ 250 8;
BA_ "J1708Priority" BO_ 247 8;
BA_ "J1708Priority" BO_ 249 8;
BA_ "J1708Priority" BO_ 248 8;
BA_ "J1708Priority" BO_ 246 8;
BA_ "J1708Priority" BO_ 245 7;
BA_ "J1587CycleTime" BO_ 245 10000;
BA_ "J1708Priority" BO_ 244 7;
BA_ "J1587CycleTime" BO_ 244 10000;
BA_ "J1708Priority" BO_ 243 8;
BA_ "J1587CycleTime" BO_ 242 10000;
BA_ "J1587CycleTime" BO_ 241 10000;
BA_ "J1708Priority" BO_ 240 8;
BA_ "J1708Priority" BO_ 237 8;
BA_ "J1708Priority" BO_ 235 8;
BA_ "J1708Priority" BO_ 234 8;
BA_ "J1708Priority" BO_ 233 8;
BA_ "J1708Priority" BO_ 232 7;
BA_ "J1587CycleTime" BO_ 232 5000;
BA_ "J1708Priority" BO_ 231 7;
BA_ "J1587CycleTime" BO_ 231 10000;
BA_ "J1708Priority" BO_ 230 8;
BA_ "J1708Priority" BO_ 229 8;
BA_ "J1708Priority" BO_ 228 8;
BA_ "J1708Priority" BO_ 225 8;
BA_ "J1708Priority" BO_ 226 8;
BA_ "J1708Priority" BO_ 227 8;
BA_ "J1708Priority" BO_ 224 1;
BA_ "J1708Priority" BO_ 223 8;
BA_ "J1708Priority" BO_ 222 8;
BA_ "J1708Priority" BO_ 221 8;
BA_ "J1708Priority" BO_ 220 8;
BA_ "J1587CycleTime" BO_ 219 10000;
BA_ "J1708Priority" BO_ 219 7;
BA_ "J1708Priority" BO_ 218 8;
BA_ "J1587CycleTime" BO_ 215 10000;
BA_ "J1708Priority" BO_ 214 8;
BA_ "J1587CycleTime" BO_ 213 10000;
BA_ "J1708Priority" BO_ 213 7;
BA_ "J1587CycleTime" BO_ 212 10000;
BA_ "J1587CycleTime" BO_ 211 10000;
BA_ "J1587CycleTime" BO_ 210 10000;
BA_ "J1708Priority" BO_ 209 3;
BA_ "J1587CycleTime" BO_ 209 500;
BA_ "J1708Priority" BO_ 199 8;
BA_ "J1708Priority" BO_ 196 8;
BA_ "J1708Priority" BO_ 194 8;
BA_ "J1708Priority" BO_ 191 2;
BA_ "J1587CycleTime" BO_ 191 100;
BA_ "J1708Priority" BO_ 189 8;
BA_ "J1708Priority" BO_ 188 8;
BA_ "J1587CycleTime" BO_ 187 10000;
BA_ "J1708Priority" BO_ 186 2;
BA_ "J1587CycleTime" BO_ 186 100;
BA_ "J1708Priority" BO_ 185 7;
BA_ "J1587CycleTime" BO_ 185 10000;
BA_ "J1708Priority" BO_ 184 3;
BA_ "J1587CycleTime" BO_ 184 200;
BA_ "J1708Priority" BO_ 183 3;
BA_ "J1587CycleTime" BO_ 183 200;
BA_ "J1708Priority" BO_ 182 7;
BA_ "J1587CycleTime" BO_ 182 10000;
BA_ "J1708Priority" BO_ 181 8;
BA_ "J1708Priority" BO_ 180 8;
BA_ "J1708Priority" BO_ 179 8;
BA_ "J1708Priority" BO_ 178 8;
BA_ "J1708Priority" BO_ 177 4;
BA_ "J1587CycleTime" BO_ 177 1000;
BA_ "J1708Priority" BO_ 176 4;
BA_ "J1587CycleTime" BO_ 176 1000;
BA_ "J1708Priority" BO_ 175 4;
BA_ "J1587CycleTime" BO_ 175 1000;
BA_ "J1708Priority" BO_ 174 4;
BA_ "J1587CycleTime" BO_ 174 1000;
BA_ "J1708Priority" BO_ 173 5;
BA_ "J1587CycleTime" BO_ 173 1000;
BA_ "J1708Priority" BO_ 172 5;
BA_ "J1587CycleTime" BO_ 172 1000;
BA_ "J1708Priority" BO_ 171 7;
BA_ "J1587CycleTime" BO_ 171 10000;
BA_ "J1708Priority" BO_ 170 7;
BA_ "J1587CycleTime" BO_ 170 10000;
BA_ "J1587CycleTime" BO_ 169 10000;
BA_ "J1708Priority" BO_ 168 5;
BA_ "J1587CycleTime" BO_ 168 1000;
BA_ "J1708Priority" BO_ 167 5;
BA_ "J1587CycleTime" BO_ 167 1000;
BA_ "J1708Priority" BO_ 166 8;
BA_ "J1708Priority" BO_ 164 5;
BA_ "J1587CycleTime" BO_ 164 1000;
BA_ "J1708Priority" BO_ 163 4;
BA_ "J1587CycleTime" BO_ 163 500;
BA_ "J1708Priority" BO_ 162 4;
BA_ "J1587CycleTime" BO_ 162 500;
BA_ "J1708Priority" BO_ 159 4;
BA_ "J1587CycleTime" BO_ 159 1000;
BA_ "J1708Priority" BO_ 158 8;
BA_ "J1708Priority" BO_ 157 4;
BA_ "J1587CycleTime" BO_ 157 1000;
BA_ "J1708Priority" BO_ 156 4;
BA_ "J1587CycleTime" BO_ 156 1000;
BA_ "J1708Priority" BO_ 155 8;
BA_ "J1708Priority" BO_ 154 8;
BA_ "J1708Priority" BO_ 153 4;
BA_ "J1587CycleTime" BO_ 153 1000;
BA_ "J1708Priority" BO_ 152 8;
BA_ "J1587CycleTime" BO_ 151 500;
BA_ "J1708Priority" BO_ 151 3;
BA_ "J1587CycleTime" BO_ 149 200;
BA_ "J1708Priority" BO_ 149 3;
BA_ "J1587CycleTime" BO_ 148 200;
BA_ "J1708Priority" BO_ 148 3;
BA_ "J1587CycleTime" BO_ 147 10000;
BA_ "J1708Priority" BO_ 147 7;
BA_ "J1708Priority" BO_ 146 8;
BA_ "J1708Priority" BO_ 145 8;
BA_ "J1708Priority" BO_ 198 8;
BA_ "J1708Priority" BO_ 144 8;
BA_ "J1708Priority" BO_ 143 8;
BA_ "J1708Priority" BO_ 142 8;
BA_ "J1708Priority" BO_ 141 8;
BA_ "J1708Priority" BO_ 140 8;
BA_ "J1708Priority" BO_ 139 8;
BA_ "J1708Priority" BO_ 138 8;
BA_ "J1708Priority" BO_ 137 8;
BA_ "J1708Priority" BO_ 136 8;
BA_ "J1587CycleTime" BO_ 135 1000;
BA_ "J1708Priority" BO_ 135 4;
BA_ "J1587CycleTime" BO_ 134 200;
BA_ "J1708Priority" BO_ 134 3;
BA_ "J1708Priority" BO_ 133 3;
BA_ "J1587CycleTime" BO_ 133 200;
BA_ "J1708Priority" BO_ 132 4;
BA_ "J1587CycleTime" BO_ 132 1000;
BA_ "J1708Priority" BO_ 131 4;
BA_ "J1587CycleTime" BO_ 131 1000;
BA_ "J1708Priority" BO_ 130 3;
BA_ "J1587CycleTime" BO_ 130 1000;
BA_ "J1708Priority" BO_ 129 4;
BA_ "J1587CycleTime" BO_ 129 1000;
BA_ "J1708Priority" BO_ 128 8;
BA_ "J1708Priority" BO_ 127 4;
BA_ "J1587CycleTime" BO_ 127 1000;
BA_ "J1708Priority" BO_ 126 7;
BA_ "J1587CycleTime" BO_ 126 10000;
BA_ "J1587CycleTime" BO_ 125 10000;
BA_ "J1708Priority" BO_ 124 7;
BA_ "J1587CycleTime" BO_ 124 10000;
BA_ "J1708Priority" BO_ 123 4;
BA_ "J1587CycleTime" BO_ 123 1000;
BA_ "J1708Priority" BO_ 122 5;
BA_ "J1587CycleTime" BO_ 122 1000;
BA_ "J1708Priority" BO_ 121 3;
BA_ "J1587CycleTime" BO_ 121 200;
BA_ "J1708Priority" BO_ 120 5;
BA_ "J1587CycleTime" BO_ 120 1000;
BA_ "J1708Priority" BO_ 119 5;
BA_ "J1587CycleTime" BO_ 119 1000;
BA_ "J1708Priority" BO_ 118 1;
BA_ "J1587CycleTime" BO_ 118 1000;
BA_ "J1708Priority" BO_ 117 1;
BA_ "J1587CycleTime" BO_ 117 1000;
BA_ "J1708Priority" BO_ 116 1;
BA_ "J1587CycleTime" BO_ 116 200;
BA_ "J1708Priority" BO_ 115 5;
BA_ "J1587CycleTime" BO_ 115 1000;
BA_ "J1708Priority" BO_ 114 5;
BA_ "J1587CycleTime" BO_ 114 1000;
BA_ "J1708Priority" BO_ 113 8;
BA_ "J1587CycleTime" BO_ 112 10000;
BA_ "J1708Priority" BO_ 111 7;
BA_ "J1587CycleTime" BO_ 111 10000;
BA_ "J1587CycleTime" BO_ 109 10000;
BA_ "J1708Priority" BO_ 108 5;
BA_ "J1587CycleTime" BO_ 108 1000;
BA_ "J1708Priority" BO_ 107 7;
BA_ "J1587CycleTime" BO_ 107 10000;
BA_ "J1708Priority" BO_ 106 5;
BA_ "J1587CycleTime" BO_ 106 1000;
BA_ "J1708Priority" BO_ 105 5;
BA_ "J1587CycleTime" BO_ 105 1000;
BA_ "J1708Priority" BO_ 102 4;
BA_ "J1587CycleTime" BO_ 102 1000;
BA_ "J1708Priority" BO_ 101 4;
BA_ "J1587CycleTime" BO_ 101 1000;
BA_ "J1587CycleTime" BO_ 99 10000;
BA_ "J1708Priority" BO_ 97 7;
BA_ "J1587CycleTime" BO_ 97 10000;
BA_ "J1587CycleTime" BO_ 96 10000;
BA_ "J1708Priority" BO_ 95 7;
BA_ "J1587CycleTime" BO_ 95 10000;
BA_ "J1708Priority" BO_ 94 4;
BA_ "J1587CycleTime" BO_ 94 1000;
BA_ "J1708Priority" BO_ 93 5;
BA_ "J1587CycleTime" BO_ 93 1000;
BA_ "J1708Priority" BO_ 92 3;
BA_ "J1587CycleTime" BO_ 92 100;
BA_ "J1708Priority" BO_ 91 3;
BA_ "J1587CycleTime" BO_ 91 100;
BA_ "J1708Priority" BO_ 90 5;
BA_ "J1587CycleTime" BO_ 90 1000;
BA_ "J1587CycleTime" BO_ 86 10000;
BA_ "J1587CycleTime" BO_ 83 1000;
BA_ "J1708Priority" BO_ 83 4;
BA_ "J1708Priority" BO_ 82 8;
BA_ "J1587CycleTime" BO_ 81 10000;
BA_ "J1708Priority" BO_ 81 7;
BA_ "J1587CycleTime" BO_ 80 10000;
BA_ "J1708Priority" BO_ 80 7;
BA_ "J1587CycleTime" BO_ 79 10;
BA_ "J1708Priority" BO_ 79 7;
BA_ "J1587CycleTime" BO_ 78 1000;
BA_ "J1708Priority" BO_ 78 5;
BA_ "J1587CycleTime" BO_ 77 1000;
BA_ "J1708Priority" BO_ 77 5;
BA_ "J1587CycleTime" BO_ 76 1000;
BA_ "J1708Priority" BO_ 76 5;
BA_ "J1587CycleTime" BO_ 75 1000;
BA_ "J1708Priority" BO_ 75 5;
BA_ "J1708Priority" BO_ 74 8;
BA_ "J1587CycleTime" BO_ 73 1000;
BA_ "J1708Priority" BO_ 73 4;
BA_ "J1587CycleTime" BO_ 72 500;
BA_ "J1708Priority" BO_ 72 3;
BA_ "J1587CycleTime" BO_ 69 1000;
BA_ "J1587CycleTime" BO_ 68 1000;
BA_ "J1708Priority" BO_ 68 4;
BA_ "J1708Priority" BO_ 67 8;
BA_ "J1708Priority" BO_ 66 8;
BA_ "J1587CycleTime" BO_ 65 1000;
BA_ "J1708Priority" BO_ 65 4;
BA_ "J1708Priority" BO_ 64 8;
BA_ "J1708Priority" BO_ 63 8;
BA_ "J1708Priority" BO_ 62 8;
BA_ "J1708Priority" BO_ 61 8;
BA_ "J1708Priority" BO_ 60 8;
BA_ "J1708Priority" BO_ 59 8;
BA_ "J1708Priority" BO_ 58 8;
BA_ "J1708Priority" BO_ 57 8;
BA_ "J1708Priority" BO_ 56 8;
BA_ "J1708Priority" BO_ 55 8;
BA_ "J1708Priority" BO_ 54 8;
BA_ "J1708Priority" BO_ 53 8;
BA_ "J1587CycleTime" BO_ 51 200;
BA_ "J1708Priority" BO_ 51 3;
BA_ "J1587CycleTime" BO_ 50 5000;
BA_ "J1708Priority" BO_ 50 8;
BA_ "J1587CycleTime" BO_ 49 500;
BA_ "J1708Priority" BO_ 49 3;
BA_ "J1587CycleTime" BO_ 48 1000;
BA_ "J1708Priority" BO_ 48 5;
BA_ "J1587CycleTime" BO_ 47 1000;
BA_ "J1708Priority" BO_ 47 5;
BA_ "J1587CycleTime" BO_ 45 1000;
BA_ "J1708Priority" BO_ 45 5;
BA_ "J1708Priority" BO_ 42 8;
BA_ "J1587CycleTime" BO_ 41 1000;
BA_ "J1708Priority" BO_ 41 3;
BA_ "J1587CycleTime" BO_ 40 200;
BA_ "J1708Priority" BO_ 40 3;
BA_ "J1708Priority" BO_ 39 8;
BA_ "J1587CycleTime" BO_ 38 10000;
BA_ "J1587CycleTime" BO_ 37 1000;
BA_ "J1708Priority" BO_ 37 4;
BA_ "J1708Priority" BO_ 36 8;
BA_ "J1708Priority" BO_ 35 8;
BA_ "J1708Priority" BO_ 34 8;
BA_ "J1708Priority" BO_ 33 8;
BA_ "J1708Priority" BO_ 32 8;
BA_ "J1708Priority" BO_ 150 8;
BA_ "J1708Priority" BO_ 89 5;
BA_ "J1587CycleTime" BO_ 89 1000;
BA_ "J1708Priority" BO_ 71 5;
BA_ "J1587CycleTime" BO_ 71 1000;
BA_ "J1708Priority" BO_ 70 5;
BA_ "J1587CycleTime" BO_ 70 1000;
BA_ "J1708Priority" BO_ 46 5;
BA_ "J1587CycleTime" BO_ 46 1000;
BA_ "J1708Priority" BO_ 44 5;
BA_ "J1587CycleTime" BO_ 44 1000;
BA_ "J1708Priority" BO_ 85 3;
BA_ "J1587CycleTime" BO_ 85 200;
BA_ "J1708Priority" BO_ 84 1;
BA_ "J1587CycleTime" BO_ 84 100;
BA_ "J1708Priority" BO_ 195 8;
BA_ "J1708Priority" BO_ 193 8;
BA_ "J1587CycleTime" BO_ 190 100;
BA_ "J1708Priority" BO_ 190 1;
BA_ "J1708Priority" BO_ 161 2;
BA_ "J1708Priority" BO_ 160 2;
BA_ "J1587CycleTime" BO_ 110 1000;
BA_ "J1708Priority" BO_ 110 4;
BA_ "J1587CycleTime" BO_ 104 1000;
BA_ "J1708Priority" BO_ 104 4;
BA_ "J1587CycleTime" BO_ 103 1000;
BA_ "J1708Priority" BO_ 103 4;
BA_ "J1587CycleTime" BO_ 100 1000;
BA_ "J1708Priority" BO_ 100 2;
BA_ "J1587CycleTime" BO_ 98 10000;
BA_ "J1587CycleTime" BO_ 52 1000;
BA_ "J1708Priority" BO_ 52 4;
BA_ "J1587CycleTime" BO_ 43 1000;
BA_ "J1708Priority" BO_ 43 5;
BA_ "J1708Priority" BO_ 31 8;
BA_ "J1587CycleTime" BO_ 30 1000;
BA_ "J1708Priority" BO_ 30 4;
BA_ "J1587CycleTime" BO_ 29 100;
BA_ "J1708Priority" BO_ 29 3;
BA_ "J1587CycleTime" BO_ 28 100;
BA_ "J1708Priority" BO_ 28 3;
BA_ "J1587CycleTime" BO_ 27 1000;
BA_ "J1708Priority" BO_ 27 4;
BA_ "J1708Priority" BO_ 26 8;
BA_ "J1587CycleTime" BO_ 25 10000;
BA_ "J1708Priority" BO_ 25 8;
BA_ "J1587CycleTime" BO_ 24 1000;
BA_ "J1708Priority" BO_ 24 4;
BA_ "J1587CycleTime" BO_ 23 1000;
BA_ "J1708Priority" BO_ 23 4;
BA_ "J1587CycleTime" BO_ 22 1000;
BA_ "J1708Priority" BO_ 22 4;
BA_ "J1587CycleTime" BO_ 21 1000;
BA_ "J1708Priority" BO_ 21 8;
BA_ "J1587CycleTime" BO_ 20 1000;
BA_ "J1708Priority" BO_ 20 4;
BA_ "J1587CycleTime" BO_ 19 1000;
BA_ "J1708Priority" BO_ 19 4;
BA_ "J1587CycleTime" BO_ 18 1000;
BA_ "J1708Priority" BO_ 18 4;
BA_ "J1587CycleTime" BO_ 17 10000;
BA_ "J1708Priority" BO_ 17 7;
BA_ "J1587CycleTime" BO_ 16 10000;
BA_ "J1708Priority" BO_ 16 7;
VAL_ 504 MiddleInterior 1 "generate message" 0 "do not generate message" ;
VAL_ 504 RearInterior 1 "generate message" 0 "do not generate message" ;
VAL_ 504 FrontExternal 1 "generate message" 0 "do not generate message" ;
VAL_ 504 FrontInterior 1 "generate message" 0 "do not generate message" ;
VAL_ 503 TransferData 15 "Agency defined" 14 "Agency defined" 13 "Agency defined" 12 "Agency defined" 11 "Agency defined" 10 "Agency defined" 9 "Agency defined" 8 "Agency defined" 7 "Agency defined" 6 "Agency defined" 5 "Out" 4 "In" 3 "West" 2 "East" 1 "South" 0 "North" ;
VAL_ 503 TypeOfService 7 "agency defined" 6 "agency defined" 5 "agency defined" 4 "agency defined" 3 "agency defined" 2 "agency defined" 1 "express service" 0 "local service" ;
VAL_ 503 TypeOfFareAndPaymentDetails 15 "agency defined" 14 "agency defined" 13 "agency defined" 12 "agency defined" 11 "agency defined" 10 "reserved—to be assigned" 9 "reserved—to be assigned" 8 "reserved—to be assigned" 7 "reserved—to be assigned" 6 "pass B" 5 "pass A" 4 "ticket B" 3 "ticket A" 2 "token B" 1 "token A" 0 "cash/no detail" ;
VAL_ 503 TypeOfTransaction 15 "agency defined" 14 "agency defined" 13 "agency defined" 12 "agency defined" 11 "reserved—to be assigned" 10 "reserved—to be assigned" 9 "reserved—to be assigned" 8 "reserved—to be assigned" 7 "free" 6 "transfer" 5 "permit" 4 "card" 3 "pass" 2 "ticket" 1 "token" 0 "cash" ;
VAL_ 502 TripStatus 7 "undefined" 6 "layover end" 5 "layover start" 4 "undefined" 3 "undefined" 2 "trip end" 1 "trip start" 0 "undefined" ;
VAL_ 502 FareboxStatus 1 "farebox in service" 0 "farebox out of service" ;
VAL_ 500 PriorityOfResponseSentByEmitter 15 "Not available" 14 "Error condition" 13 "Reserved" 12 "Reserved" 11 "Prio set by hw to high prio" 10 "Prio set by hw to probe prio" 9 "Prio set by hardware to low prio" 8 "Reserved" 7 "Reserved" 6 "Reserved" 5 "Reserved" 4 "Reserved" 3 "High priority" 2 "Probe priority" 1 "Low priority" 0 "Reserved" ;
VAL_ 500 TransitDoorEnable 3 "Description for the value '3'" 2 "Error condition" 1 "Status will overr strobe activtn" 0 "Ignore transit door status" ;
VAL_ 500 StrobeActivation 3 "Not available" 2 "Error condition" 1 "Activate strobe" 0 "Deactivate Strobe" ;
VAL_ 500 VehicleID 3 "Not available" 2 "Error condition" 1 "ID is included in byte (c)" 0 "ID is NOT included in byte (c)" ;
VAL_ 500 RangeCodeEnable 3 "Not available" 2 "Error condition" 1 "ID used for interleaved data" 0 "ID NOT used for interleaved data" ;
VAL_ 500 TransitRouteIDEnable 3 "Not available" 2 "Error condition" 1 "ID used for interleaved data" 0 "ID not used for interleaved data" ;
VAL_ 500 Request_Response 3 "Not available" 2 "Error condition" 1 "Msg is response from emitter" 0 "Msg is request directd to emittr" ;
VAL_ 499 CommandType 11 "Paint Form to screen" 10 "Erase Form from screen" 9 "DIU control" 8 "Paint object to screen" 7 "Erase object from screen" 6 "Object attribute assignment" 5 "Request display type" 4 "Query object" 3 "Read from non-volatile memory" 2 "Write to non-volatile memory" 1 "Delete" 0 "Create" ;
VAL_ 447 TypeOfPassengerCount 4 "exiting passenger (2nd stream)" 3 "boarding passenger (2nd stream)" 2 "exiting passenger" 1 "boarding passenger" 0 "absolute passenger count" ;
VAL_ 435 LocationOfTheAirTemperature 3 "Description for the value '3'" 2 "Temperature up rear" 1 "Temperature down front" 0 "Temperature up front" ;
VAL_ 381 TransitRunStatus 3 "Not available" 2 "Error condition" 1 "On" 0 "Off" ;
VAL_ 381 VehicleUseStatus 3 "Not available" 2 "Error condition" 1 "Unauthorized use" 0 "Normal use" ;
VAL_ 379 TransitDoorStatus 3 "Not available" 2 "Error condition" 1 "Door Open" 0 "Door Closed" ;
VAL_ 379 TrailerCargoDoorStatus 3 "Not available" 2 "Error condition" 1 "Door Open" 0 "Door Closed" ;
VAL_ 378 FareCollectionUnitStatus 1 "voltage restored" 0 "non-emergency status" ;
VAL_ 378 AlarmIdentifier 25 "maintennce access—out or service" 24 "maintenance access—in service" 23 "paper currency jam cleared" 22 "paper currency jam" 21 "pass/transfer jam cleared" 20 "pass/transfer jam" 19 "farebox reset to automatic mode" 18 "farebox set in manual bypass" 17 "coin de-jam operated" 16 "card/pass box full" 15 "card/pass box less than 75% full" 14 "card/pass box 75% full" 13 "currency box full" 12 "currency box less than 75% full" 11 "currency box 75% full" 10 "coinbox full" 9 "coinbox 75% full" 8 "insufficient fare accepted" 7 "cashbox opened in service" 6 "cashbox door timeout" 5 "cashbox restored" 4 "cashbox removed" 3 "probe completed" 2 "probe started" 1 "voltage restored" 0 "voltage dropout" ;
VAL_ 368 RightSideIndicationStatus 3 "Not available" 2 "Error condition" 1 "Active/Out of lane detected" 0 "Not Actve/Out of lane not detctd" ;
VAL_ 368 LeftSideIndicationStatus 3 "Not available" 2 "Error condition" 1 "Active/Out of lane detected" 0 "Not Actve/Out of lane not detctd" ;
VAL_ 367 LaneTrackingSysStatusRightSide 3 "Not available" 2 "Error Condition" 1 "Tracking" 0 "Not Tracking" ;
VAL_ 367 LaneTrackingSysStatusLeftSide 3 "Not available" 2 "Error Condition" 1 "Tracking" 0 "Not Tracking" ;
VAL_ 365 WeighingSystemStatus2 3 "Don’t care / Take no action" 2 "Reserved" 1 "0 Net Vehicle Weight Change cmd" 0 "No chng to Net Vehicle Wght Chng" ;
VAL_ 365 WeighingSystemStatus1 3 "Not available / not applicable" 2 "5.wheel is on its calibr. point" 1 "5.wheel will be off its cal. pt" 0 "No change to fifth wheel" ;
VAL_ 225 ReceiveNetworkMsgFromSender 1 "Receive network message" 0 "No reply requested" ;
VAL_ 225 OperatorHasPressedAcknKey 1 "Operator acknowledge" 0 "No key press" ;
VAL_ 225 MessageDisplayed 1 "Message is being displayed" 0 "Message is in buffer" ;
VAL_ 225 DisplayBuffersFull 1 "Buffer(s) full" 0 "Additional msg can be accepted" ;
VAL_ 225 MessageAborted 1 "Message aborted" 0 "Message OK" ;
VAL_ 226 SendReceivedAckForEachNetworkMsg 1 "Send acknowld for receipt of msg" 0 "Do not send acknowledgment" ;
VAL_ 226 SendOperatorAckOfReceiptOfMsg 1 "Expect acknowldgmt from operator" 0 "Do not expect ackn from operator" ;
VAL_ 226 SendAcknowldgUponDisplayOfMsg 1 "Send acknowledgment" 0 "No acknowledgment" ;
VAL_ 226 SoundBeeperOnDisplay 1 "Initiate beeper" 0 "No sound" ;
VAL_ 226 DisplayCompleteMessage 1 "Display buffered message" 0 "Continue to buffer message" ;
VAL_ 226 PredefinedMessage 1 "Message predefined" 0 "Message not predefined" ;
VAL_ 226 AbortMessage 1 "Abort buffered message" 0 "Message OK" ;
VAL_ 226 LanguageSelection 1 "Revert to English" 0 "Use selected language" ;
VAL_ 227 Beeper_Sound 1 "Beeper is supported" 0 "Beeper is not supported" ;
VAL_ 227 AcknowledgmentKey 1 "Acknowledgment key is supported" 0 "Acknowledgm key is not supported" ;
VAL_ 227 LanguageSelection 15 "Reserved" 14 "Reserved" 13 "Reserved" 12 "Reserved" 11 "Reserved" 10 "Reserved" 9 "Reserved" 8 "Reserved" 7 "Reserved" 6 "Reserved" 5 "Reserved" 4 "Italian" 3 "German" 2 "French" 1 "Spanish" 0 "English" ;
VAL_ 222 EncryptionSeedPresent 3 "not defined" 2 "not defined" 1 "True" 0 "False" ;
VAL_ 222 PasswordValid 3 "not defined" 2 "not defined" 1 "True" 0 "False" ;
VAL_ 222 ComponentStatus 3 "not defined" 2 "Blocked" 1 "Locked" 0 "Unlocked" ;
VAL_ 222 StatusOfRequest 3 "Not_Valid" 2 "’Empty_Of_Passwords’" 1 "’Full_Of_Passwords’" 0 "Ok" ;
VAL_ 221 EncryptionIndicatorStates 3 "Not_Available" 2 "not defined" 1 "Encrypted_Code_Present" 0 "Encryption_Seed_Request" ;
VAL_ 221 DesiredExitMode 3 "Not_Available" 2 "not defined" 1 "Lock_When_Key_Off" 0 "Lock_Upon_Operator_Request" ;
VAL_ 221 CommandStates 7 "not defined" 6 "not defined" 5 "Login" 4 "Check_Status" 3 "Lock_or_Unlock" 2 "Change_Password" 1 "Delete_Password" 0 "Add_Password" ;
VAL_ 220 TorqueLimitingFeatureStatus 3 "Description for the value '3'" 2 "Reserved" 1 "Feature is enabled" 0 "Feature is disabled" ;
VAL_ 220 TorqueLimitingFeature 7 "Reserved" 6 "Reserved" 5 "Reserved" 4 "Current torque rating" 3 "Previous torque rating" 2 "First torque rating" 1 "Highest torque rating" 0 "Not available" ;
VAL_ 216 TankAntennaStatus 3 "Not available" 2 "Error condition" 1 "Active" 0 "Not active" ;
VAL_ 216 TankIdentification 15 "tank 16" 14 "tank 15" 13 "tank 14" 12 "tank 13" 11 "tank 12" 10 "tank 11" 9 "tank 10" 8 "tank 9" 7 "tank 8" 6 "tank 7" 5 "tank 6" 4 "tank 5" 3 "tank 4" 2 "tank 3" 1 "tank 2" 0 "tank 1" ;
VAL_ 209 TractorMountedTrailerABSLamp 3 "Not available" 2 "Error condition" 1 "On/Active" 0 "Off/Not Active" ;
VAL_ 209 TrailerABSControlStatus 3 "Not available" 2 "Error condition" 1 "On/Active" 0 "Off/Not Active" ;
VAL_ 209 ABSWarningLampTrailer1 3 "Not available" 2 "Error condition" 1 "On/Active" 0 "Off/Not Active" ;
VAL_ 209 ABSBrakeControlStatusTrailer1 3 "Not available" 2 "Error condition" 1 "On/Active" 0 "Off/Not Active" ;
VAL_ 199 TractionCtrlFunctEnabledDisabled 7 "Not available" 6 "Error" 5 "Reserved" 4 "Reserved" 3 "Tr ctrl diff brak&eng ctrl enbl" 2 "Tr brak disbl&tr eng enbl" 1 "Tr brak enbl&tr eng disbl" 0 "Tr ctrl diff brak&eng ctrl disbl" ;
VAL_ 199 TractionControlActivePassive 7 "Not available" 6 "Error" 5 "Reserved" 4 "Reserved" 3 "Trct ctrl diff brak&eng ctrl act" 2 "Tract ctrl engine ctrl func act" 1 "Tract ctrl diff braking func act" 0 "Traction ctrl function passive" ;
VAL_ 199 TractionControlRequestResponse 3 "Not viable" 2 "Error" 1 "Msg is resp. from traction ctrl" 0 "Msg is request to traction ctrl" ;
VAL_ 196 TypeOfDiagnosticCode 1 "standard diagnostic code" 0 "expansion diagnostic code PID" ;
VAL_ 196 FailureModeIdentifierFMI 15 "Reserved" 14 "Special Instructions" 13 "Out of Calibration" 12 "Bad intelligent device or compon" 11 "Failure mode not identifiable" 10 "Abnormal rate of change" 9 "Abnormal update rate" 8 "Abnrm freq,pulse width,or period" 7 "Mech system not responding prop" 6 "Current abve norm or ground circ" 5 "Current below norm or open circ" 4 "Voltage below norm or shortd low" 3 "Voltage above norm or short high" 2 "Data erratc,intrmittnt,or incorr" 1 "Data below norm operationl range" 0 "Data above norm operationl range" ;
VAL_ 196 LowCharacterIDForAStdDiagCode 1 "low char is subsystem id (SID)" 0 "low char is parameter id (PID)" ;
VAL_ 196 DiagnosticCodeBits 3 "Additional diag information." 2 "Diag cnts cleared for device." 1 "Cnt cleared for given diag code." 0 "Msg is ASCII descr. for S/PID." ;
VAL_ 194 CurrentStatusOfFault 1 "fault is inactive" 0 "fault is active" ;
VAL_ 194 FailureModeIdentifierFMI 15 "Reserved" 14 "Special Instructions" 13 "Out of Calibration" 12 "Bad intelligent device or compon" 11 "Failure mode not identifiable" 10 "Abnormal rate of change" 9 "Abnormal update rate" 8 "Abnrm freq,pulse width,or period" 7 "Mech system not responding prop" 6 "Current abve norm or ground circ" 5 "Current below norm or open circ" 4 "Voltage below norm or shortd low" 3 "Voltage above norm or short high" 2 "Data erratc,intrmittnt,or incorr" 1 "Data below norm operationl range" 0 "Data above norm operationl range" ;
VAL_ 194 LowCharacterIDForAStdDiagCode 1 "low char is subsystem id (SID)" 0 "low char is parameter id (PID)" ;
VAL_ 194 TypeOfDiagnosticCode 1 "standard diagnostic code" 0 "expansion diagnostic code PID" ;
VAL_ 194 OccurrenceCountIncluded 1 "count is included" 0 "count is not included" ;
VAL_ 155 AuxiliaryOutput4 3 "Not available" 2 "Error condition" 1 "On" 0 "Off" ;
VAL_ 155 AuxiliaryOutput3 3 "Not available" 2 "Error condition" 1 "On" 0 "Off" ;
VAL_ 155 AuxiliaryOutput2 3 "Not available" 2 "Error condition" 1 "On" 0 "Off" ;
VAL_ 155 AuxiliaryOutput1 3 "Not available" 2 "Error condition" 1 "On" 0 "Off" ;
VAL_ 155 AuxiliaryInput4 3 "Not available" 2 "Error condition" 1 "On" 0 "Off" ;
VAL_ 155 AuxiliaryInput3 3 "Not available" 2 "Error condition" 1 "On" 0 "Off" ;
VAL_ 155 AuxiliaryInput2 3 "Not available" 2 "Error condition" 1 "On" 0 "Off" ;
VAL_ 155 AuxiliaryInput1 3 "Not available" 2 "Error condition" 1 "On" 0 "Off" ;
VAL_ 154 AuxiliaryOutput8 3 "Not available" 2 "Error condition" 1 "On" 0 "Off" ;
VAL_ 154 AuxiliaryOutput7 3 "Not available" 2 "Error condition" 1 "On" 0 "Off" ;
VAL_ 154 AuxiliaryOutput6 3 "Not available" 2 "Error condition" 1 "On" 0 "Off" ;
VAL_ 154 AuxiliaryOutput5 3 "Not available" 2 "Error condition" 1 "On" 0 "Off" ;
VAL_ 154 AuxiliaryInput8 3 "Not available" 2 "Error condition" 1 "On" 0 "Off" ;
VAL_ 154 AuxiliaryInput7 3 "Not available" 2 "Error condition" 1 "On" 0 "Off" ;
VAL_ 154 AuxiliaryInput6 3 "Not available" 2 "Error condition" 1 "On" 0 "Off" ;
VAL_ 154 AuxiliaryInput5 3 "Not available" 2 "Error condition" 1 "On" 0 "Off" ;
VAL_ 151 ATCDeepSnowMudFunctionSwitch 3 "Not Available" 2 "Error" 1 "On" 0 "Off" ;
VAL_ 151 ATCSpinOutSignalDetection 3 "Not Available" 2 "Error" 1 "On" 0 "Off" ;
VAL_ 151 ATCEngineControl 3 "Not Available" 2 "Error" 1 "On" 0 "Off" ;
VAL_ 151 ATCBrakeControl 3 "Not Available" 2 "Error" 1 "On" 0 "Off" ;
VAL_ 151 ATCStatusLamp 3 "Not Available" 2 "Error" 1 "On" 0 "Off" ;
VAL_ 197 CMCommand 255 "Abort" 4 "RSD" 3 "EOM" 2 "CTS" 1 "RTS" ;
VAL_ 140 PCUTrailerSolenoidStatus 3 "NotAvailable" 2 "Error" 1 "On" 0 "Off" ;
VAL_ 140 PCUSupplySolenoidStatus 3 "NotAvailable" 2 "Error" 1 "On" 0 "Off" ;
VAL_ 140 PCUControlSolenoidStatus 3 "NotAvailable" 2 "Error" 1 "On" 0 "Off" ;
VAL_ 140 PCUDeflateSolenoidStatus 3 "NotAvailable" 2 "Error" 1 "On" 0 "Off" ;
VAL_ 140 PCUSteerSolenoidStatus 3 "NotAvailable" 2 "Error" 1 "On" 0 "Off" ;
VAL_ 140 PCUDriveSolenoidStatus 3 "NotAvailable" 2 "Error" 1 "On" 0 "Off" ;
VAL_ 139 SteerChannelMode 15 "NotAvailable" 14 "Error" 6 "PressureCheck" 5 "DeflateWait" 4 "InflateWait" 3 "Confirm" 2 "Deflate" 1 "Inflate" 0 "Maintain" ;
VAL_ 139 DriveChannelMode 15 "NotAvailable" 14 "Error" 6 "PressureCheck" 5 "DeflateWait" 4 "InflateWait" 3 "Confirm" 2 "Deflate" 1 "Inflate" 0 "Maintain" ;
VAL_ 139 TrailerChannelMode 15 "NotAvailable" 14 "Error" 6 "PressureCheck" 5 "DeflateWait" 4 "InflateWait" 3 "Confirm" 2 "Deflate" 1 "Inflate" 0 "Maintain" ;
VAL_ 134 WheelSensorABSAxleLeft4 3 "NotAvailable" 2 "Error" 1 "Active" 0 "NotActive" ;
VAL_ 134 WheelSensorABSAxleLeft3 3 "NotAvailable" 2 "Error" 1 "Active" 0 "NotActive" ;
VAL_ 134 WheelSensorABSAxleLeft2 3 "NotAvailable" 2 "Error" 1 "Active" 0 "NotActive" ;
VAL_ 134 WheelSensorABSAxleLeft1 3 "NotAvailable" 2 "Error" 1 "Active" 0 "NotActive" ;
VAL_ 134 WheelSensorABSAxleRight1 3 "NotAvailable" 2 "Error" 1 "Active" 0 "NotActive" ;
VAL_ 134 WheelSensorABSAxleRight2 3 "NotAvailable" 2 "Error" 1 "Active" 0 "NotActive" ;
VAL_ 134 WheelSensorABSAxleRight3 3 "NotAvailable" 2 "Error" 1 "Active" 0 "NotActive" ;
VAL_ 134 WheelSensorABSAxleRight4 3 "NotAvailable" 2 "Error" 1 "Active" 0 "NotActive" ;
VAL_ 97 WaterInFuelIndicator 1 "Yes" 0 "No" ;
VAL_ 83 RoadSpeedLimitStatus 1 "active" 0 "notActive" ;
VAL_ 69 TwoSpeedAxleSwitchStatus 1 "LowRangeIsCommanded" 0 "HighRangeIsCommanded" ;
VAL_ 67 DownshiftSwitchStatus 3 "NotAvailable" 2 "Error" 1 "On" 0 "Off" ;
VAL_ 66 PowerConnectDeviceStatus 3 "NotAvailable" 2 "Error" 1 "On" 0 "Off" ;
VAL_ 66 StartEnableDeviceStatus 3 "NotAvailable" 2 "Error" 1 "On" 0 "Off" ;
VAL_ 66 IgnitionSwitchStatus 3 "NotAvailable" 2 "Error" 1 "On" 0 "Off" ;
VAL_ 65 BrakeSystemSwitchStatus 3 "NotAvailable" 2 "Error" 1 "On" 0 "Off" ;
VAL_ 65 ServiceBrakeSwitchStatus 3 "NotAvailable" 2 "Error" 1 "On" 0 "Off" ;
VAL_ 64 ForwardSwitchStatus 3 "NotAvailable" 2 "Error" 1 "On" 0 "Off" ;
VAL_ 64 NeutralSwitchStatus 3 "NotAvailable" 2 "Error" 1 "On" 0 "Off" ;
VAL_ 64 ReverseSwitchStatus 3 "NotAvailable" 2 "Error" 1 "On" 0 "Off" ;
VAL_ 63 SplitterIndirectActuatorStatus 3 "NotAvailable" 2 "Error" 1 "On" 0 "Off" ;
VAL_ 63 SplitterDirectActuatorStatus 3 "NotAvailable" 2 "Error" 1 "On" 0 "Off" ;
VAL_ 63 RangeLowActuatorStatus 3 "NotAvailable" 2 "Error" 1 "On" 0 "Off" ;
VAL_ 63 RangeHighActuatorStatus 3 "NotAvailable" 2 "Error" 1 "On" 0 "Off" ;
VAL_ 62 RetarderInhibitStatus 3 "NotAvailable" 2 "Error" 1 "On" 0 "Off" ;
VAL_ 61 ParkingBrakeOffActuatorStatus 3 "NotAvailable" 2 "Error" 1 "On" 0 "Off" ;
VAL_ 61 ParkingBrakeOnActuatorStatus 3 "NotAvailable" 2 "Error" 1 "On" 0 "Off" ;
VAL_ 58 GearActuator2Status 3 "NotAvailable" 2 "Error" 1 "On" 0 "Off" ;
VAL_ 58 RailActuator2Status 3 "NotAvailable" 2 "Error" 1 "On" 0 "Off" ;
VAL_ 58 GearActuator1Status 3 "NotAvailable" 2 "Error" 1 "On" 0 "Off" ;
VAL_ 58 RailActuator1Status 3 "NotAvailable" 2 "Error" 1 "On" 0 "Off" ;
VAL_ 57 InertiaBrakeActuatorStatus 3 "NotAvailable" 2 "Error" 1 "On" 0 "Off" ;
VAL_ 57 DefuelActuatorStatus 3 "NotAvailable" 2 "Error" 1 "On" 0 "Off" ;
VAL_ 57 LockupClutchActuatorStatus 3 "NotAvailable" 2 "Error" 1 "On" 0 "Off" ;
VAL_ 57 ClutchActuatorStatus 3 "NotAvailable" 2 "Error" 1 "On" 0 "Off" ;
VAL_ 56 LowRangeSense 3 "NotAvailable" 2 "Error" 1 "On" 0 "Off" ;
VAL_ 56 HighRangeSense 3 "NotAvailable" 2 "Error" 1 "On" 0 "Off" ;
VAL_ 55 CenterRailSense 3 "NotAvailable" 2 "Error" 1 "On" 0 "Off" ;
VAL_ 55 ForeAftSense 3 "NotAvailable" 2 "Error" 1 "On" 0 "Off" ;
VAL_ 55 NeutralSense 3 "NotAvailable" 2 "Error" 1 "On" 0 "Off" ;
VAL_ 50 EngineFanRequest 3 "NotAvailable" 2 "Error" 1 "FanIsRequested" 0 "NoRequest" ;
VAL_ 50 AirConditioningRequestInput 3 "NotAvailable" 2 "Error" 1 "ACisRequested" 0 "NoRequest" ;
VAL_ 50 RqTempClutchDisengage 3 "NotAvailable" 2 "Error" 1 "ClutchDisengegementRequested" 0 "NoRequest" ;
VAL_ 50 ClutchEngagementStatus 3 "NotAvailable" 2 "Error" 1 "Engaged" 0 "Disengaged" ;
VAL_ 49 ABSOffRoadFunctionSwitch 3 "NotAvailable" 2 "Error" 1 "On" 0 "Off" ;
VAL_ 49 ABSRetarderControl 3 "NotAvailable" 2 "Error" 1 "On" 0 "Off" ;
VAL_ 49 ABSBrakeControl 3 "NotAvailable" 2 "Error" 1 "On" 0 "Off" ;
VAL_ 49 ABSWarningLamp 3 "NotAvailable" 2 "Error" 1 "On" 0 "Off" ;
VAL_ 47 TransmissionOutputRetarderStatus 3 "NotAvailable" 2 "Error" 1 "On" 0 "Off" ;
VAL_ 45 WaitToStartLamp 3 "NotAvailable" 2 "Error" 1 "On" 0 "Off" ;
VAL_ 45 Heater2Status 3 "NotAvailable" 2 "Error" 1 "On" 0 "Off" ;
VAL_ 45 Heater1Status 3 "NotAvailable" 2 "Error" 1 "On" 0 "Off" ;
VAL_ 42 TirePressureSupplySwitchStatus 3 "NotAvailable" 2 "Error" 1 "AtOrAboveSetPressure" 0 "BelowSetPressure" ;
VAL_ 41 CruiseControlOnOffSwitchStatus 3 "NotAvailable" 2 "Error" 1 "On" 0 "Off" ;
VAL_ 41 CruiseControlSetSwitchStatus 3 "NotAvailable" 2 "Error" 1 "On" 0 "Off" ;
VAL_ 41 CruiseControlResumeSwitchStatus 3 "NotAvailable" 2 "Error" 1 "On" 0 "Off" ;
VAL_ 40 EngineRetarderLevelSwitch 15 "NotAvailable" 14 "Error" 9 "Beschreibung für den Wert '0x9'" 8 "8 Cylinders" 7 "7 Cylinders" 6 "6 Cylinders" 5 "5 Cylinders" 4 "4 Cylinders" 3 "3 Cylinders" 2 "2 Cylinders" 1 "1 Cylinders" 0 "0 Cylinders" ;
VAL_ 40 EngineRetarderSwitch 3 "NotAvailable" 2 "Error" 1 "On" 0 "Off" ;
VAL_ 35 GearActuator3Status 3 "NotAvailable" 2 "Error" 1 "On" 0 "Off" ;
VAL_ 35 RailActuator3Status 3 "NotAvailable" 2 "Error" 1 "On" 0 "Off" ;
VAL_ 34 CoarseEngagementActuatorStatus 3 "NotAvailable" 2 "Error" 1 "On" 0 "Off" ;
VAL_ 34 FineEngagementActuatorStatus 3 "NotAvailable" 2 "Error" 1 "On" 0 "Off" ;
VAL_ 34 CoarseDisengageActuatorStatus 3 "NotAvailable" 2 "Error" 1 "On" 0 "Off" ;
VAL_ 34 FineDisengagementActuatorStatus 3 "NotAvailable" 2 "Error" 1 "On" 0 "Off" ;
VAL_ 150 PTOOutputStatus2 3 "Not Available" 2 "Error" 1 "On" 0 "Off" ;
VAL_ 150 PTOOutputStatus1 3 "Not Available" 2 "Error" 1 "On" 0 "Off" ;
VAL_ 150 PTOInputStatus2 3 "Not Available" 2 "Error" 1 "On" 0 "Off" ;
VAL_ 150 PTOInputStatus1 3 "Not Available" 2 "Error" 1 "On" 0 "Off" ;
VAL_ 89 PTOMode 1 "Active" 0 "not Active" ;
VAL_ 89 ClutchSwitch 1 "On" 0 "Off" ;
VAL_ 89 BrakeSwitch 1 "Yes" 0 "No" ;
VAL_ 89 AccelSwitch 1 "On" 0 "Off" ;
VAL_ 89 ResumeSwitch 1 "On" 0 "Off" ;
VAL_ 89 CoastSwitch 1 "On" 0 "Off" ;
VAL_ 89 SetSwitch 1 "On" 0 "Off" ;
VAL_ 89 PTOControlSwitch 1 "On" 0 "Off" ;
VAL_ 71 IdleShutdownTimerStatus 1 "Active" 0 "not Active" ;
VAL_ 71 IdelShutdownTimerFunc 1 "Enabled" 0 "Disabled" ;
VAL_ 71 IdleShutdownTimerOverride 1 "Active" 0 "not Active" ;
VAL_ 71 EngineHasShutDownByIdleTimer 1 "Yes" 0 "No" ;
VAL_ 71 DriverAlertMode 1 "Active" 0 "not Active" ;
VAL_ 70 ParkingBrakeSwitch 1 "Active" 0 "not Active" ;
VAL_ 44 ProtectLamp 3 "NotAvailable" 2 "Error" 1 "On" 0 "Off" ;
VAL_ 44 AmberLamp 3 "NotAvailable" 2 "Error" 1 "On" 0 "Off" ;
VAL_ 44 RedLamp 3 "NotAvailable" 2 "Error" 1 "On" 0 "Off" ;
VAL_ 85 CruiseMode 1 "Active" 0 "not Active" ;
VAL_ 85 ClutchSwitch 1 "On" 0 "Off" ;
VAL_ 85 BrakeSwitch 1 "On" 0 "Off" ;
VAL_ 85 AccelSwitch 1 "On" 0 "Off" ;
VAL_ 85 ResumeSwitch 1 "On" 0 "Off" ;
VAL_ 85 CoastSwitch 1 "On" 0 "Off" ;
VAL_ 85 SetSwitch 1 "On" 0 "Off" ;
VAL_ 85 CruiseControlSwitch 1 "On" 0 "Off" ;
VAL_ 195 TypeOfDiagnosticCode 1 "standard diagnostic code" 0 "expansion diagnostic code PID" ;
VAL_ 195 FailureModeIdentifierFMI 15 "Reserved" 14 "Special Instructions" 13 "Out of Calibration" 12 "Bad intelligent device or compon" 11 "Failure mode not identifiable" 10 "Abnormal rate of change" 9 "Abnormal update rate" 8 "Abnrm freq,pulse width,or period" 7 "Mech system not responding prop" 6 "Current abve norm or ground circ" 5 "Current below norm or open circ" 4 "Voltage below norm or shortd low" 3 "Voltage above norm or short high" 2 "Data erratc,intrmittnt,or incorr" 1 "Data below norm operationl range" 0 "Data above norm operationl range" ;
VAL_ 195 LowCharacterIDForAStdDiagCode 1 "low char is subsystem id (SID)" 0 "low char is parameter id (PID)" ;
VAL_ 195 DiagnosticCodeBits 3 "Additional diag information." 2 "Diag cnts cleared for device." 1 "Cnt cleared for given diag code." 0 "Msg is ASCII descr. for S/PID." ;
